VERSION ""

NS_ :

BS_:

BU_: PowertrainControlModule AtmosphericSensor SafetyRestraintSystem2 Aftertreatment_2_GasOutlet Aftertreatment_2_GasIntake DieselPartFilterControl Turbocharger SafetyRestraintSystem1 CabDisplay2 Aftertreatment_1_GasOutlet Aftertreatment_1_GasIntake OnBoardDataLogger OffBoardDiagnosticTool2 OffBoardDiagnosticTool1 FileServer ParkingBrakeController SeatController2 FanDriveController SteeringColumnUnit CommunicationUnitRadio CommunicationUnitSatellite CommunicationUnitCellular PropulsionBatteryCharger ChassisController2 ChassisController1 EngineValveControl AuxiliaryHeater2 AuxiliaryHeater1 ClutchUnit RampControl InformationSystem1 SuspensionSystemController2 OilSensor VehicleDynamicStability ExhaustEmissionController TransmissionDisplay2 TransmissionDisplay1 ClimateControl2 WaterPumpController RearAxleSteeringController LightingOperatorControl SeatController1 IgnitionController2 IgnitionController1 TirePressureController CabController2 CabController1 PneumaticSystemController SuspensionSystemController1 HydraulicPumpController EnduranceBrakingSystem RetarderExhaustEngine2 OnBoardDiagnosticUnit HeadwayController RetarderExhaustEngine1 CabDisplay1 ManagementComputer VirtualTerminal OffVehicleGateway PowerTakeOffFront HitchControl AuxiliaryValveControl BodyController TractorTrailerBridge1 StarterSystem ElectricalSystem VehicleSecurity VehicleNavigation AerodynamicControl ElectricalChargingSystem ClimateControl1 TripRecorder InstrumentCluster SuspensionDriveAxle2 SuspensionDriveAxle1 SuspensionSteerAxle SteeringController FuelSystem CruiseControl RetarderDriveline RetarderEngine BrakesDriveAxle2 BrakesDriveAxle1 BrakesSystemController BrakesSteerAxle AxleDrive2 AxleDrive1 AxleSteering PowerTakeOff ShiftConsoleSecondary ShiftConsolePrimary Transmission2 Transmission1 Engine2 Engine1

BO_ 2365403390 BJM4: 8 Vector__XXX
 SG_ Joystick4Button9PressedStatus : 62|2@1+ (1,0) [0|3] "" Vector__XXX
 SG_ Joystick4Button10PressedStatus : 60|2@1+ (1,0) [0|3] "" Vector__XXX
 SG_ Joystick4Button11PressedStatus : 58|2@1+ (1,0) [0|3] "" Vector__XXX
 SG_ Joystick4Button12PressedStatus : 56|2@1+ (1,0) [0|3] "" Vector__XXX
 SG_ Joystick4Button5PressedStatus : 54|2@1+ (1,0) [0|3] "" Vector__XXX
 SG_ Joystick4Button6PressedStatus : 52|2@1+ (1,0) [0|3] "" Vector__XXX
 SG_ Joystick4Button7PressedStatus : 50|2@1+ (1,0) [0|3] "" Vector__XXX
 SG_ Joystick4Button8PressedStatus : 48|2@1+ (1,0) [0|3] "" Vector__XXX
 SG_ Joystick4Button1PressedStatus : 46|2@1+ (1,0) [0|3] "" Vector__XXX
 SG_ Joystick4Button2PressedStatus : 44|2@1+ (1,0) [0|3] "" Vector__XXX
 SG_ Joystick4Button3PressedStatus : 42|2@1+ (1,0) [0|3] "" Vector__XXX
 SG_ Joystick4Button4PressedStatus : 40|2@1+ (1,0) [0|3] "" Vector__XXX
 SG_ Joystick4XAxisDetentPosStatus : 38|2@1+ (1,0) [0|3] "" Vector__XXX
 SG_ Joystick4YAxisDetentPosStatus : 36|2@1+ (1,0) [0|3] "" Vector__XXX
 SG_ Joystick4YAxisPos : 22|10@1+ (0.1,0) [0|102] "%" Vector__XXX
 SG_ Jystck4YAxsLvrFrwrdPstvPosStatus : 20|2@1+ (1,0) [0|3] "" Vector__XXX
 SG_ Jystck4YAxsLvrBckNgtivePosStatus : 18|2@1+ (1,0) [0|3] "" Vector__XXX
 SG_ Joystick4YAxisNeutralPosStatus : 16|2@1+ (1,0) [0|3] "" Vector__XXX
 SG_ Joystick4XAxisPos : 6|10@1+ (0.1,0) [0|102] "%" Vector__XXX
 SG_ Jystck4XAxsLvrRghtPstvePosStatus : 4|2@1+ (1,0) [0|3] "" Vector__XXX
 SG_ Jystck4XAxsLvrLftNgtivePosStatus : 2|2@1+ (1,0) [0|3] "" Vector__XXX
 SG_ Joystick4XAxisNeutralPosStatus : 0|2@1+ (1,0) [0|3] "" Vector__XXX

BO_ 2365400318 BJM10: 8 Vector__XXX
 SG_ Joystick10Button9PressedStatus : 62|2@1+ (1,0) [0|3] "" Vector__XXX
 SG_ Joystick10Button10PressedStatus : 60|2@1+ (1,0) [0|3] "" Vector__XXX
 SG_ Joystick10Button11PressedStatus : 58|2@1+ (1,0) [0|3] "" Vector__XXX
 SG_ Joystick10Button12PressedStatus : 56|2@1+ (1,0) [0|3] "" Vector__XXX
 SG_ Joystick10Button5PressedStatus : 54|2@1+ (1,0) [0|3] "" Vector__XXX
 SG_ Joystick10Button6PressedStatus : 52|2@1+ (1,0) [0|3] "" Vector__XXX
 SG_ Joystick10Button7PressedStatus : 50|2@1+ (1,0) [0|3] "" Vector__XXX
 SG_ Joystick10Button8PressedStatus : 48|2@1+ (1,0) [0|3] "" Vector__XXX
 SG_ Joystick10Button1PressedStatus : 46|2@1+ (1,0) [0|3] "" Vector__XXX
 SG_ Joystick10Button2PressedStatus : 44|2@1+ (1,0) [0|3] "" Vector__XXX
 SG_ Joystick10Button3PressedStatus : 42|2@1+ (1,0) [0|3] "" Vector__XXX
 SG_ Joystick10Button4PressedStatus : 40|2@1+ (1,0) [0|3] "" Vector__XXX
 SG_ Joystick10XAxisDetentPosStatus : 38|2@1+ (1,0) [0|3] "" Vector__XXX
 SG_ Joystick10YAxisDetentPosStatus : 36|2@1+ (1,0) [0|3] "" Vector__XXX
 SG_ Joystick10YAxisPos : 22|10@1+ (0.1,0) [0|102] "%" Vector__XXX
 SG_ Jystck10YAxsLvrFrwrdPstvPsStatus : 20|2@1+ (1,0) [0|3] "" Vector__XXX
 SG_ Jystck10YAxsLvrBckNgtvePosStatus : 18|2@1+ (1,0) [0|3] "" Vector__XXX
 SG_ Joystick10YAxisNeutralPosStatus : 16|2@1+ (1,0) [0|3] "" Vector__XXX
 SG_ Joystick10XAxisPos : 6|10@1+ (0.1,0) [0|102] "%" Vector__XXX
 SG_ Jystck10XAxsLvrRghtPstvPosStatus : 4|2@1+ (1,0) [0|3] "" Vector__XXX
 SG_ Jystck10XAxsLvrLftNgtvePosStatus : 2|2@1+ (1,0) [0|3] "" Vector__XXX
 SG_ Joystick10XAxisNeutralPosStatus : 0|2@1+ (1,0) [0|3] "" Vector__XXX

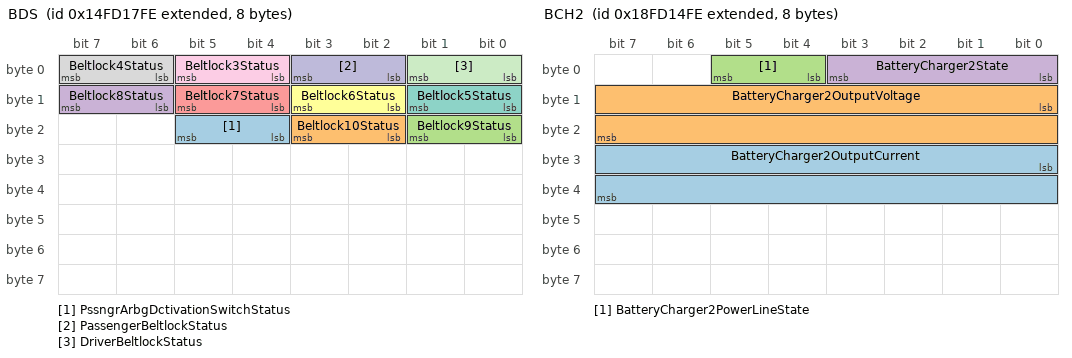
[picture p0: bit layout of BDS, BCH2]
BO_ 2499614718 BDS: 8 Vector__XXX
 SG_ PssngrArbgDctivationSwitchStatus : 20|2@1+ (1,0) [0|3] "" Vector__XXX
 SG_ Beltlock10Status : 18|2@1+ (1,0) [0|3] "" Vector__XXX
 SG_ Beltlock9Status : 16|2@1+ (1,0) [0|3] "" Vector__XXX
 SG_ Beltlock8Status : 14|2@1+ (1,0) [0|3] "" Vector__XXX
 SG_ Beltlock7Status : 12|2@1+ (1,0) [0|3] "" Vector__XXX
 SG_ Beltlock6Status : 10|2@1+ (1,0) [0|3] "" Vector__XXX
 SG_ Beltlock5Status : 8|2@1+ (1,0) [0|3] "" Vector__XXX
 SG_ Beltlock4Status : 6|2@1+ (1,0) [0|3] "" Vector__XXX
 SG_ Beltlock3Status : 4|2@1+ (1,0) [0|3] "" Vector__XXX
 SG_ PassengerBeltlockStatus : 2|2@1+ (1,0) [0|3] "" Vector__XXX
 SG_ DriverBeltlockStatus : 0|2@1+ (1,0) [0|3] "" Vector__XXX

BO_ 2566722814 BCH2: 8 Vector__XXX
 SG_ BatteryCharger2OutputCurrent : 24|16@1+ (0.05,-1600) [-1600|1612.75] "A" Vector__XXX
 SG_ BatteryCharger2OutputVoltage : 8|16@1+ (0.05,0) [0|3212.75] "V" Vector__XXX
 SG_ BatteryCharger2PowerLineState : 4|2@1+ (1,0) [0|3] "" Vector__XXX
 SG_ BatteryCharger2State : 0|4@1+ (1,0) [0|15] "" Vector__XXX

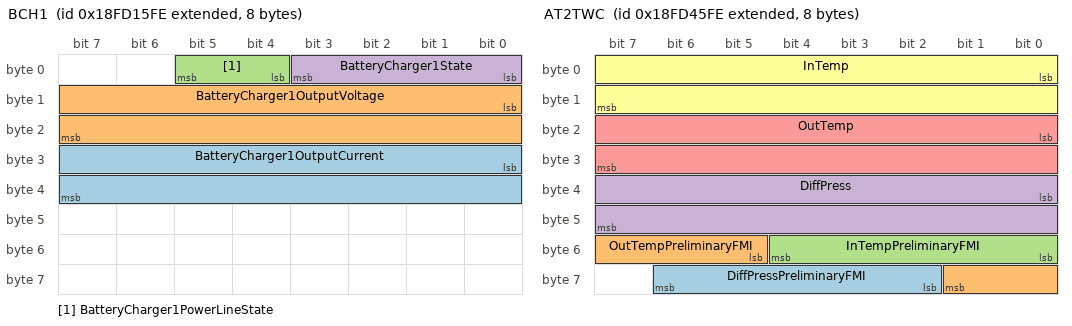
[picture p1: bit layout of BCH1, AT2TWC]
BO_ 2566723070 BCH1: 8 Vector__XXX
 SG_ BatteryCharger1OutputCurrent : 24|16@1+ (0.05,-1600) [-1600|1612.75] "A" Vector__XXX
 SG_ BatteryCharger1OutputVoltage : 8|16@1+ (0.05,0) [0|3212.75] "V" Vector__XXX
 SG_ BatteryCharger1PowerLineState : 4|2@1+ (1,0) [0|3] "" Vector__XXX
 SG_ BatteryCharger1State : 0|4@1+ (1,0) [0|15] "" Vector__XXX

BO_ 2566725118 ATDT2: 8 Vector__XXX
 SG_ TwoTWCDiffTemp : 16|16@1+ (0.03125,-273) [-273|1734.96875] "°C" Vector__XXX
 SG_ OneTWCDiffTemp : 0|16@1+ (0.03125,-273) [-273|1734.96875] "°C" Vector__XXX

BO_ 2566725374 ATDT1: 8 Vector__XXX
 SG_ TwoGOCDiffTemp : 16|16@1+ (0.03125,-273) [-273|1734.96875] "°C" Vector__XXX
 SG_ OneGOCDiffTemp : 0|16@1+ (0.03125,-273) [-273|1734.96875] "°C" Vector__XXX

BO_ 2566712830 AT2WUDOC: 8 Vector__XXX
 SG_ OutTemp : 16|16@1+ (0.03125,-273) [-273|1734.96875] "°C" Vector__XXX
 SG_ InTemp : 0|16@1+ (0.03125,-273) [-273|1734.96875] "°C" Vector__XXX

BO_ 2566735358 AT2TWC: 8 Vector__XXX
 SG_ DiffPressPreliminaryFMI : 58|5@1+ (1,0) [0|31] "" Vector__XXX
 SG_ OutTempPreliminaryFMI : 53|5@1+ (1,0) [0|31] "" Vector__XXX
 SG_ InTempPreliminaryFMI : 48|5@1+ (1,0) [0|31] "" Vector__XXX
 SG_ DiffPress : 32|16@1+ (0.1,0) [0|6425.5] "kPa" Vector__XXX
 SG_ OutTemp : 16|16@1+ (0.03125,-273) [-273|1734.96875] "°C" Vector__XXX
 SG_ InTemp : 0|16@1+ (0.03125,-273) [-273|1734.96875] "°C" Vector__XXX

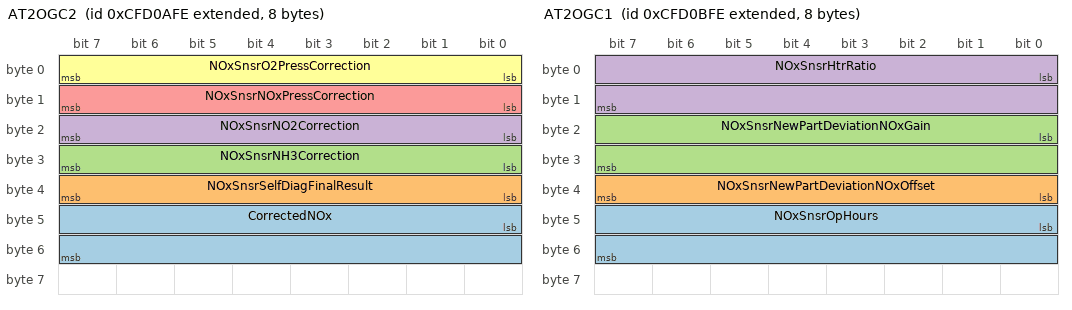
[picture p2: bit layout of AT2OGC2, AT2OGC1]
BO_ 2365393662 AT2OGC2: 8 Vector__XXX
 SG_ CorrectedNOx : 40|16@1+ (0.05,-200) [-200|3012.75] "ppm" Vector__XXX
 SG_ NOxSnsrSelfDiagFinalResult : 32|8@1+ (1,0) [0|250] "" Vector__XXX
 SG_ NOxSnsrNH3Correction : 24|8@1+ (0.5,0) [0|125] "%" Vector__XXX
 SG_ NOxSnsrNO2Correction : 16|8@1+ (0.5,0) [0|125] "%" Vector__XXX
 SG_ NOxSnsrNOxPressCorrection : 8|8@1+ (0.5,0) [0|125] "%/bar" Vector__XXX
 SG_ NOxSnsrO2PressCorrection : 0|8@1+ (0.5,0) [0|125] "%/bar" Vector__XXX

BO_ 2365393918 AT2OGC1: 8 Vector__XXX
 SG_ NOxSnsrOpHours : 40|16@1+ (1,0) [0|64255] "h" Vector__XXX
 SG_ NOxSnsrNewPartDeviationNOxOffset : 32|8@1+ (1,-125) [-125|125] "ppm" Vector__XXX
 SG_ NOxSnsrNewPartDeviationNOxGain : 16|16@1+ (0.1,-100) [-100|100] "%" Vector__XXX
 SG_ NOxSnsrHtrRatio : 0|16@1+ (0.001,0) [0|64.255] "" Vector__XXX

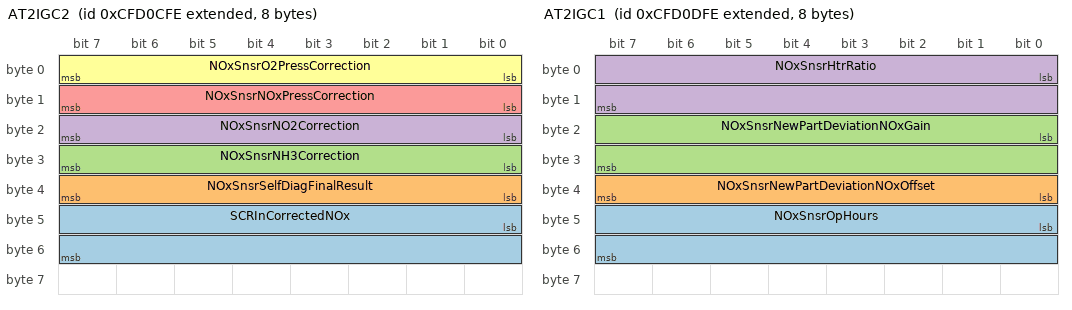
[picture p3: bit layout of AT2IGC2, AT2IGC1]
BO_ 2365394174 AT2IGC2: 8 Vector__XXX
 SG_ SCRInCorrectedNOx : 40|16@1+ (0.05,-200) [-200|3012.75] "ppm" Vector__XXX
 SG_ NOxSnsrSelfDiagFinalResult : 32|8@1+ (1,0) [0|250] "" Vector__XXX
 SG_ NOxSnsrNH3Correction : 24|8@1+ (0.5,0) [0|125] "%" Vector__XXX
 SG_ NOxSnsrNO2Correction : 16|8@1+ (0.5,0) [0|125] "%" Vector__XXX
 SG_ NOxSnsrNOxPressCorrection : 8|8@1+ (0.5,0) [0|125] "%/bar" Vector__XXX
 SG_ NOxSnsrO2PressCorrection : 0|8@1+ (0.5,0) [0|125] "%/bar" Vector__XXX

BO_ 2365394430 AT2IGC1: 8 Vector__XXX
 SG_ NOxSnsrOpHours : 40|16@1+ (1,0) [0|64255] "h" Vector__XXX
 SG_ NOxSnsrNewPartDeviationNOxOffset : 32|8@1+ (1,-125) [-125|125] "ppm" Vector__XXX
 SG_ NOxSnsrNewPartDeviationNOxGain : 16|16@1+ (0.1,-100) [-100|100] "%" Vector__XXX
 SG_ NOxSnsrHtrRatio : 0|16@1+ (0.001,0) [0|64.255] "" Vector__XXX

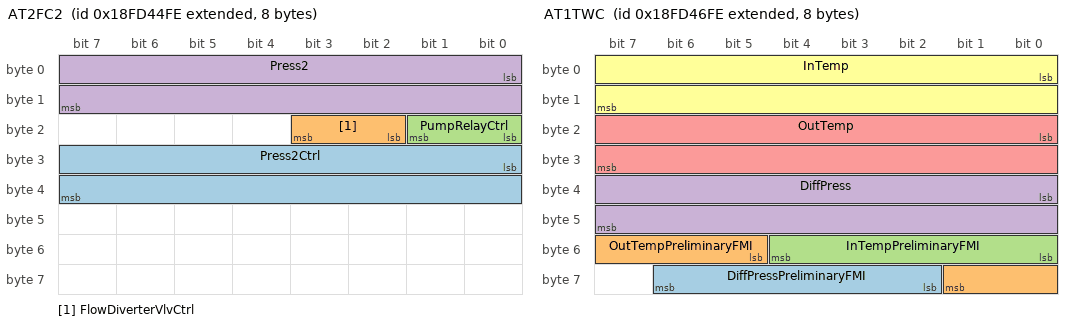
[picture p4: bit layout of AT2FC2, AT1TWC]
BO_ 2566735102 AT2FC2: 8 Vector__XXX
 SG_ Press2Ctrl : 24|16@1+ (0.0025,0) [0|160.6375] "%" Vector__XXX
 SG_ FlowDiverterVlvCtrl : 18|2@1+ (1,0) [0|3] "" Vector__XXX
 SG_ PumpRelayCtrl : 16|2@1+ (1,0) [0|3] "" Vector__XXX
 SG_ Press2 : 0|16@1+ (0.1,0) [0|6425.5] "kPa" Vector__XXX

BO_ 2157313790 AT2DPFSSC: 8 Vector__XXX
 SG_ StdDeviationCalOffset : 16|16@1+ (0.0025,0) [0|160.6375] "%" Vector__XXX
 SG_ MeanCalOffset : 0|16@1+ (0.0025,0) [0|160.6375] "%" Vector__XXX

BO_ 2566724350 AT1WUDOC: 8 Vector__XXX
 SG_ OutTemp : 16|16@1+ (0.03125,-273) [-273|1734.96875] "°C" Vector__XXX
 SG_ InTemp : 0|16@1+ (0.03125,-273) [-273|1734.96875] "°C" Vector__XXX

BO_ 2566735614 AT1TWC: 8 Vector__XXX
 SG_ DiffPressPreliminaryFMI : 58|5@1+ (1,0) [0|31] "" Vector__XXX
 SG_ OutTempPreliminaryFMI : 53|5@1+ (1,0) [0|31] "" Vector__XXX
 SG_ InTempPreliminaryFMI : 48|5@1+ (1,0) [0|31] "" Vector__XXX
 SG_ DiffPress : 32|16@1+ (0.1,0) [0|6425.5] "kPa" Vector__XXX
 SG_ OutTemp : 16|16@1+ (0.03125,-273) [-273|1734.96875] "°C" Vector__XXX
 SG_ InTemp : 0|16@1+ (0.03125,-273) [-273|1734.96875] "°C" Vector__XXX

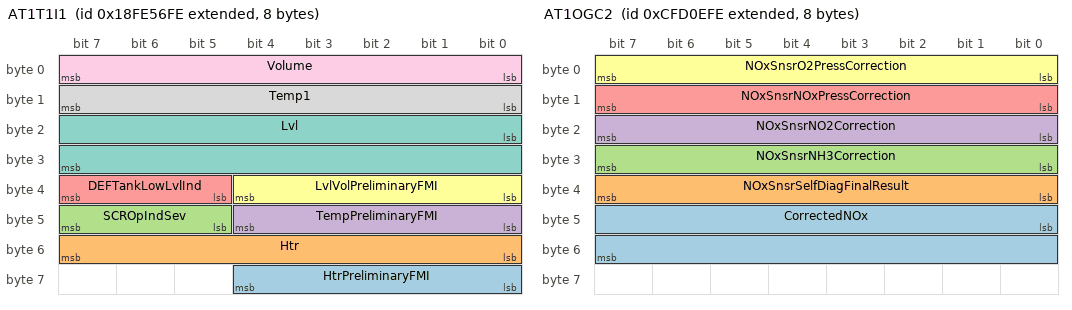
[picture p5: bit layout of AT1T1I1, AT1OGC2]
BO_ 2566805246 AT1T1I1: 8 Vector__XXX
 SG_ HtrPreliminaryFMI : 56|5@1+ (1,0) [0|31] "" Vector__XXX
 SG_ Htr : 48|8@1+ (0.4,0) [0|100] "%" Vector__XXX
 SG_ SCROpIndSev : 45|3@1+ (1,0) [0|7] "" Vector__XXX
 SG_ TempPreliminaryFMI : 40|5@1+ (1,0) [0|31] "" Vector__XXX
 SG_ DEFTankLowLvlInd : 37|3@1+ (1,0) [0|7] "" Vector__XXX
 SG_ LvlVolPreliminaryFMI : 32|5@1+ (1,0) [0|31] "" Vector__XXX
 SG_ Lvl : 16|16@1+ (0.1,0) [0|6425.5] "mm" Vector__XXX
 SG_ Temp1 : 8|8@1+ (1,-40) [-40|210] "°C" Vector__XXX
 SG_ Volume : 0|8@1+ (0.4,0) [0|100] "%" Vector__XXX

BO_ 2365394686 AT1OGC2: 8 Vector__XXX
 SG_ CorrectedNOx : 40|16@1+ (0.05,-200) [-200|3012.75] "ppm" Vector__XXX
 SG_ NOxSnsrSelfDiagFinalResult : 32|8@1+ (1,0) [0|250] "" Vector__XXX
 SG_ NOxSnsrNH3Correction : 24|8@1+ (0.5,0) [0|125] "%" Vector__XXX
 SG_ NOxSnsrNO2Correction : 16|8@1+ (0.5,0) [0|125] "%" Vector__XXX
 SG_ NOxSnsrNOxPressCorrection : 8|8@1+ (0.5,0) [0|125] "%/bar" Vector__XXX
 SG_ NOxSnsrO2PressCorrection : 0|8@1+ (0.5,0) [0|125] "%/bar" Vector__XXX

BO_ 2365394942 AT1OGC1: 8 Vector__XXX
 SG_ NOxSnsrOpHours : 40|16@1+ (1,0) [0|64255] "h" Vector__XXX
 SG_ NOxSnsrNewPartDeviationNOxOffset : 32|8@1+ (1,-125) [-125|125] "ppm" Vector__XXX
 SG_ NOxSnsrNewPartDeviationNOxGain : 16|16@1+ (0.1,-100) [-100|100] "%" Vector__XXX
 SG_ NOxSnsrHtrRatio : 0|16@1+ (0.001,0) [0|64.255] "" Vector__XXX

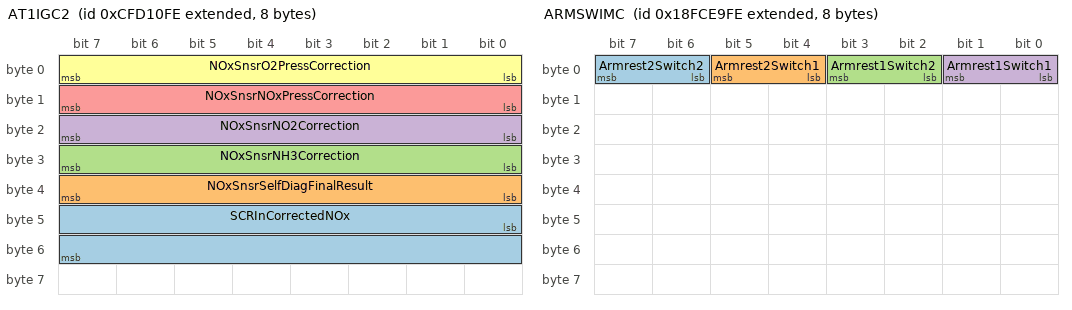
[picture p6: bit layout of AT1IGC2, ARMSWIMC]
BO_ 2365395198 AT1IGC2: 8 Vector__XXX
 SG_ SCRInCorrectedNOx : 40|16@1+ (0.05,-200) [-200|3012.75] "ppm" Vector__XXX
 SG_ NOxSnsrSelfDiagFinalResult : 32|8@1+ (1,0) [0|250] "" Vector__XXX
 SG_ NOxSnsrNH3Correction : 24|8@1+ (0.5,0) [0|125] "%" Vector__XXX
 SG_ NOxSnsrNO2Correction : 16|8@1+ (0.5,0) [0|125] "%" Vector__XXX
 SG_ NOxSnsrNOxPressCorrection : 8|8@1+ (0.5,0) [0|125] "%/bar" Vector__XXX
 SG_ NOxSnsrO2PressCorrection : 0|8@1+ (0.5,0) [0|125] "%/bar" Vector__XXX

BO_ 2365395454 AT1IGC1: 8 Vector__XXX
 SG_ NOxSnsrOpHours : 40|16@1+ (1,0) [0|64255] "h" Vector__XXX
 SG_ NOxSnsrNewPartDeviationNOxOffset : 32|8@1+ (1,-125) [-125|125] "ppm" Vector__XXX
 SG_ NOxSnsrNewPartDeviationNOxGain : 16|16@1+ (0.1,-100) [-100|100] "%" Vector__XXX
 SG_ NOxSnsrHtrRatio : 0|16@1+ (0.001,0) [0|64.255] "" Vector__XXX

BO_ 2157248254 AT1DPFSSC: 8 Vector__XXX
 SG_ StdDeviationCalOffset : 16|16@1+ (0.0025,0) [0|160.6375] "%" Vector__XXX
 SG_ MeanCalOffset : 0|16@1+ (0.0025,0) [0|160.6375] "%" Vector__XXX

BO_ 2566711806 ARMSWIMC: 8 Vector__XXX
 SG_ Armrest2Switch2 : 6|2@1+ (1,0) [0|3] "" Vector__XXX
 SG_ Armrest2Switch1 : 4|2@1+ (1,0) [0|3] "" Vector__XXX
 SG_ Armrest1Switch2 : 2|2@1+ (1,0) [0|3] "" Vector__XXX
 SG_ Armrest1Switch1 : 0|2@1+ (1,0) [0|3] "" Vector__XXX

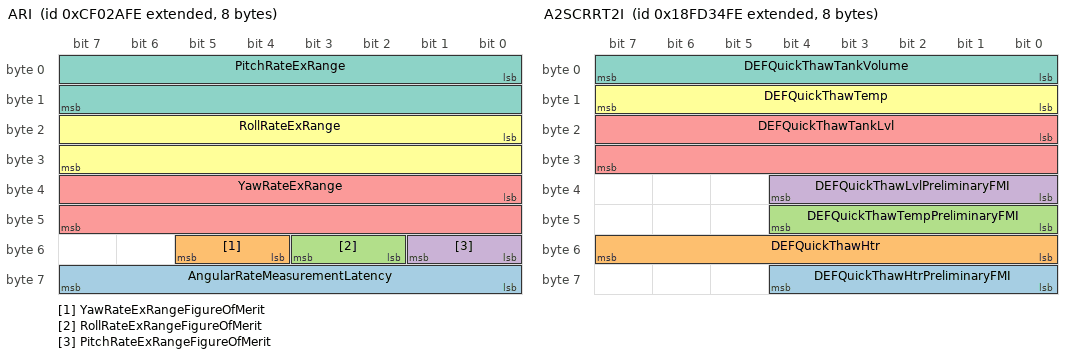
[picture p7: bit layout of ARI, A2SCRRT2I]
BO_ 2364549886 ARI: 8 Vector__XXX
 SG_ AngularRateMeasurementLatency : 56|8@1+ (0.5,0) [0|125] "ms" Vector__XXX
 SG_ YawRateExRangeFigureOfMerit : 52|2@1+ (1,0) [0|3] "" Vector__XXX
 SG_ RollRateExRangeFigureOfMerit : 50|2@1+ (1,0) [0|3] "" Vector__XXX
 SG_ PitchRateExRangeFigureOfMerit : 48|2@1+ (1,0) [0|3] "" Vector__XXX
 SG_ YawRateExRange : 32|16@1+ (0.0078125,-250) [-250|250.992] "deg/s" Vector__XXX
 SG_ RollRateExRange : 16|16@1+ (0.0078125,-250) [-250|250.992] "deg/s" Vector__XXX
 SG_ PitchRateExRange : 0|16@1+ (0.0078125,-250) [-250|250.992] "deg/s" Vector__XXX

BO_ 2566712318 AFT2NAI: 8 Vector__XXX
 SG_ DesulfationStatus : 2|2@1+ (1,0) [0|3] "" Vector__XXX
 SG_ RegenStatus : 0|2@1+ (1,0) [0|3] "" Vector__XXX

BO_ 2566712574 AFT1NAI: 8 Vector__XXX
 SG_ DesulfationStatus : 2|2@1+ (1,0) [0|3] "" Vector__XXX
 SG_ RegenStatus : 0|2@1+ (1,0) [0|3] "" Vector__XXX

BO_ 2164078590 A2SCRSI1: 8 Vector__XXX
 SG_ ConversionEfficiency : 32|8@1+ (0.4,0) [0|100] "%" Vector__XXX
 SG_ CommandedDEFConsumption : 16|16@1+ (0.05,0) [0|3212.75] "L/h" Vector__XXX
 SG_ DEFAvgConsumption : 0|16@1+ (0.05,0) [0|3212.75] "L/h" Vector__XXX

BO_ 2566731006 A2SCRRT2I: 8 Vector__XXX
 SG_ DEFQuickThawHtrPreliminaryFMI : 56|5@1+ (1,0) [0|31] "" Vector__XXX
 SG_ DEFQuickThawHtr : 48|8@1+ (0.4,0) [0|100] "%" Vector__XXX
 SG_ DEFQuickThawTempPreliminaryFMI : 40|5@1+ (1,0) [0|31] "" Vector__XXX
 SG_ DEFQuickThawLvlPreliminaryFMI : 32|5@1+ (1,0) [0|31] "" Vector__XXX
 SG_ DEFQuickThawTankLvl : 16|16@1+ (0.1,0) [0|6425.5] "mm" Vector__XXX
 SG_ DEFQuickThawTemp : 8|8@1+ (1,-40) [-40|210] "°C" Vector__XXX
 SG_ DEFQuickThawTankVolume : 0|8@1+ (0.4,0) [0|100] "%" Vector__XXX

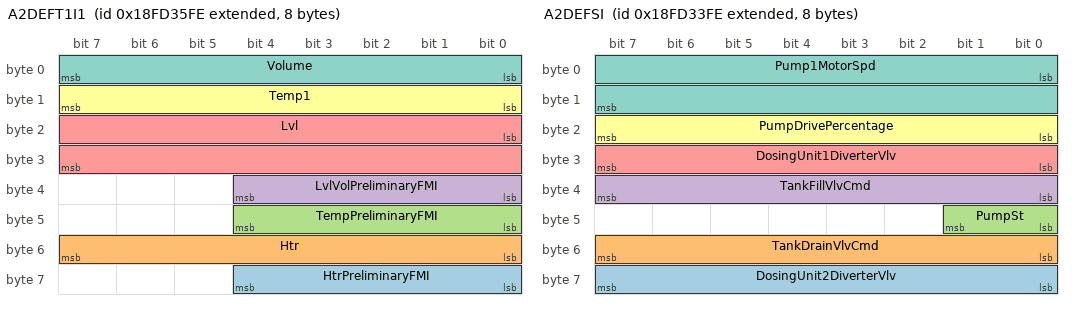
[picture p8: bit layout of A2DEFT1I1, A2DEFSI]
BO_ 2566731262 A2DEFT1I1: 8 Vector__XXX
 SG_ HtrPreliminaryFMI : 56|5@1+ (1,0) [0|31] "" Vector__XXX
 SG_ Htr : 48|8@1+ (0.4,0) [0|100] "%" Vector__XXX
 SG_ TempPreliminaryFMI : 40|5@1+ (1,0) [0|31] "" Vector__XXX
 SG_ LvlVolPreliminaryFMI : 32|5@1+ (1,0) [0|31] "" Vector__XXX
 SG_ Lvl : 16|16@1+ (0.1,0) [0|6425.5] "mm" Vector__XXX
 SG_ Temp1 : 8|8@1+ (1,-40) [-40|210] "°C" Vector__XXX
 SG_ Volume : 0|8@1+ (0.4,0) [0|100] "%" Vector__XXX

BO_ 2566730750 A2DEFSI: 8 Vector__XXX
 SG_ DosingUnit2DiverterVlv : 56|8@1+ (0.4,0) [0|100] "%" Vector__XXX
 SG_ TankDrainVlvCmd : 48|8@1+ (0.4,0) [0|100] "%" Vector__XXX
 SG_ PumpSt : 40|2@1+ (1,0) [0|3] "" Vector__XXX
 SG_ TankFillVlvCmd : 32|8@1+ (0.4,0) [0|100] "%" Vector__XXX
 SG_ DosingUnit1DiverterVlv : 24|8@1+ (0.4,0) [0|100] "%" Vector__XXX
 SG_ PumpDrivePercentage : 16|8@1+ (0.4,0) [0|100] "%" Vector__XXX
 SG_ Pump1MotorSpd : 0|16@1+ (0.5,0) [0|32127.5] "rpm" Vector__XXX

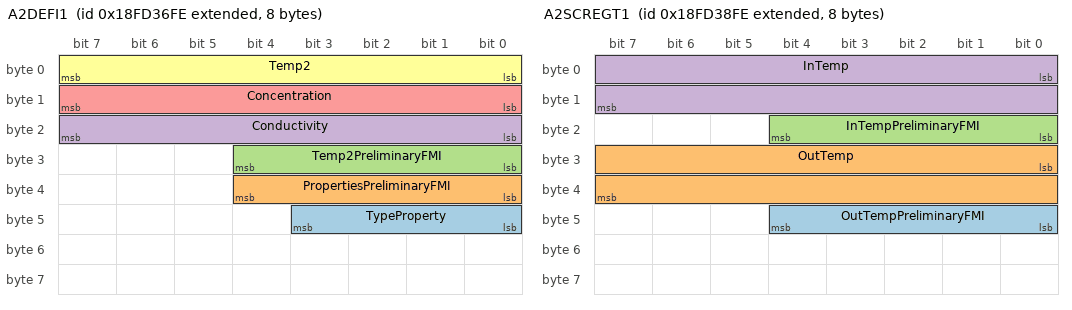
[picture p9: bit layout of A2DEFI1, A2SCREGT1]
BO_ 2566731518 A2DEFI1: 8 Vector__XXX
 SG_ TypeProperty : 40|4@1+ (1,0) [0|15] "" Vector__XXX
 SG_ PropertiesPreliminaryFMI : 32|5@1+ (1,0) [0|31] "" Vector__XXX
 SG_ Temp2PreliminaryFMI : 24|5@1+ (1,0) [0|31] "" Vector__XXX
 SG_ Conductivity : 16|8@1+ (5,0) [0|1250] "µSiemens/mm" Vector__XXX
 SG_ Concentration : 8|8@1+ (0.25,0) [0|62.5] "%" Vector__XXX
 SG_ Temp2 : 0|8@1+ (1,-40) [-40|210] "°C" Vector__XXX

BO_ 2566732030 A2SCREGT1: 8 Vector__XXX
 SG_ OutTempPreliminaryFMI : 40|5@1+ (1,0) [0|31] "" Vector__XXX
 SG_ OutTemp : 24|16@1+ (0.03125,-273) [-273|1734.96875] "°C" Vector__XXX
 SG_ InTempPreliminaryFMI : 16|5@1+ (1,0) [0|31] "" Vector__XXX
 SG_ InTemp : 0|16@1+ (0.03125,-273) [-273|1734.96875] "°C" Vector__XXX

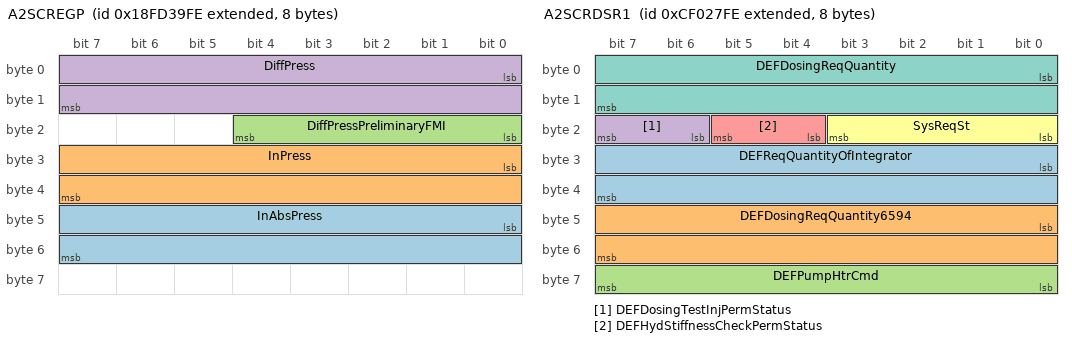
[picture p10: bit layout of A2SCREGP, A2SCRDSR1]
BO_ 2566732286 A2SCREGP: 8 Vector__XXX
 SG_ InAbsPress : 40|16@1+ (0.1,0) [0|6425.5] "kPa" Vector__XXX
 SG_ InPress : 24|16@1+ (0.1,-3212.7) [-3212.7|3212.8] "kPa" Vector__XXX
 SG_ DiffPressPreliminaryFMI : 16|5@1+ (1,0) [0|31] "" Vector__XXX
 SG_ DiffPress : 0|16@1+ (0.1,0) [0|6425.5] "kPa" Vector__XXX

BO_ 2164079358 A2SCRDSR2: 8 Vector__XXX
 SG_ DEFLineHtr10 : 48|2@1+ (1,0) [0|3] "" Vector__XXX
 SG_ DEFLineHtr9 : 46|2@1+ (1,0) [0|3] "" Vector__XXX
 SG_ DEFLineHtr8 : 44|2@1+ (1,0) [0|3] "" Vector__XXX
 SG_ DEFLineHtr7 : 42|2@1+ (1,0) [0|3] "" Vector__XXX
 SG_ DEFLineHtr6 : 40|2@1+ (1,0) [0|3] "" Vector__XXX
 SG_ DEFLineHtr5 : 38|2@1+ (1,0) [0|3] "" Vector__XXX
 SG_ DEFLineHtrRelay3 : 36|2@1+ (1,0) [0|3] "" Vector__XXX
 SG_ DEFLineHtrRelay2 : 34|2@1+ (1,0) [0|3] "" Vector__XXX
 SG_ DEFLineHtrRelay1 : 32|2@1+ (1,0) [0|3] "" Vector__XXX
 SG_ DEFQuickThawHtrCmd : 24|8@1+ (0.4,0) [0|100] "%" Vector__XXX
 SG_ DEFTankHtrCmd : 16|8@1+ (0.4,0) [0|100] "%" Vector__XXX
 SG_ DEFLineHtr4 : 14|2@1+ (1,0) [0|3] "" Vector__XXX
 SG_ DEFLineHtr3 : 12|2@1+ (1,0) [0|3] "" Vector__XXX
 SG_ DEFLineHtr2 : 10|2@1+ (1,0) [0|3] "" Vector__XXX
 SG_ DEFLineHtr1 : 8|2@1+ (1,0) [0|3] "" Vector__XXX
 SG_ DEFDoserHeatingModeReq : 4|3@1+ (1,0) [0|7] "" Vector__XXX
 SG_ DEFDoserFaultSuppressionReq : 2|2@1+ (1,0) [0|3] "" Vector__XXX

BO_ 2364549118 A2SCRDSR1: 8 Vector__XXX
 SG_ DEFReqQuantityOfIntegrator : 24|16@1+ (0.1,0) [0|6425.5] "g" Vector__XXX
 SG_ DEFDosingReqQuantity6594 : 40|16@1+ (0.05,0) [0|3212.75] "g/min" Vector__XXX
 SG_ DEFPumpHtrCmd : 56|8@1+ (0.4,0) [0|100] "%" Vector__XXX
 SG_ DEFDosingTestInjPermStatus : 22|2@1+ (1,0) [0|3] "" Vector__XXX
 SG_ DEFHydStiffnessCheckPermStatus : 20|2@1+ (1,0) [0|3] "" Vector__XXX
 SG_ SysReqSt : 16|4@1+ (1,0) [0|15] "" Vector__XXX
 SG_ DEFDosingReqQuantity : 0|16@1+ (0.3,0) [0|19276.5] "g/h" Vector__XXX

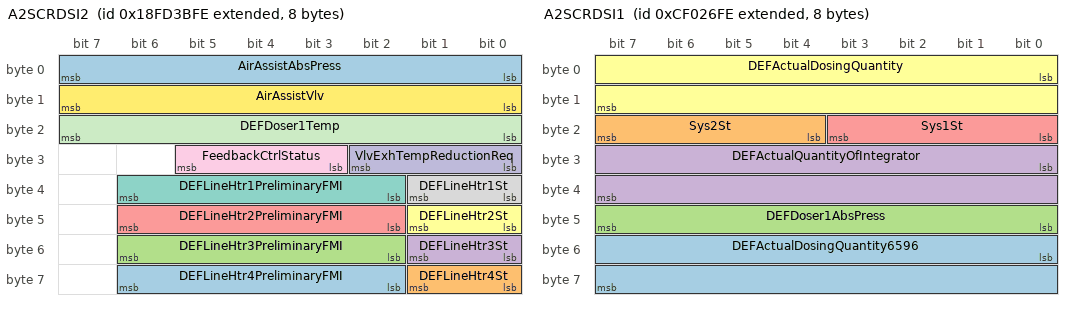
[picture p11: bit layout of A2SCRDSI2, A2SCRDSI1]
BO_ 2566732798 A2SCRDSI2: 8 Vector__XXX
 SG_ DEFLineHtr4PreliminaryFMI : 58|5@1+ (1,0) [0|31] "" Vector__XXX
 SG_ DEFLineHtr4St : 56|2@1+ (1,0) [0|3] "" Vector__XXX
 SG_ DEFLineHtr3PreliminaryFMI : 50|5@1+ (1,0) [0|31] "" Vector__XXX
 SG_ DEFLineHtr3St : 48|2@1+ (1,0) [0|3] "" Vector__XXX
 SG_ DEFLineHtr2PreliminaryFMI : 42|5@1+ (1,0) [0|31] "" Vector__XXX
 SG_ DEFLineHtr2St : 40|2@1+ (1,0) [0|3] "" Vector__XXX
 SG_ DEFLineHtr1PreliminaryFMI : 34|5@1+ (1,0) [0|31] "" Vector__XXX
 SG_ DEFLineHtr1St : 32|2@1+ (1,0) [0|3] "" Vector__XXX
 SG_ FeedbackCtrlStatus : 27|3@1+ (1,0) [0|7] "" Vector__XXX
 SG_ VlvExhTempReductionReq : 24|3@1+ (1,0) [0|7] "" Vector__XXX
 SG_ DEFDoser1Temp : 16|8@1+ (1,-40) [-40|210] "°C" Vector__XXX
 SG_ AirAssistVlv : 8|8@1+ (0.4,0) [0|100] "%" Vector__XXX
 SG_ AirAssistAbsPress : 0|8@1+ (8,0) [0|2000] "kPa" Vector__XXX

BO_ 2364548862 A2SCRDSI1: 8 Vector__XXX
 SG_ DEFActualDosingQuantity6596 : 48|16@1+ (0.05,0) [0|3212.75] "g/min" Vector__XXX
 SG_ Sys2St : 20|4@1+ (1,0) [0|15] "" Vector__XXX
 SG_ DEFDoser1AbsPress : 40|8@1+ (8,0) [0|2000] "kPa" Vector__XXX
 SG_ DEFActualQuantityOfIntegrator : 24|16@1+ (0.1,0) [0|6425.5] "g" Vector__XXX
 SG_ Sys1St : 16|4@1+ (1,0) [0|15] "" Vector__XXX
 SG_ DEFActualDosingQuantity : 0|16@1+ (0.3,0) [0|19276.5] "g/h" Vector__XXX

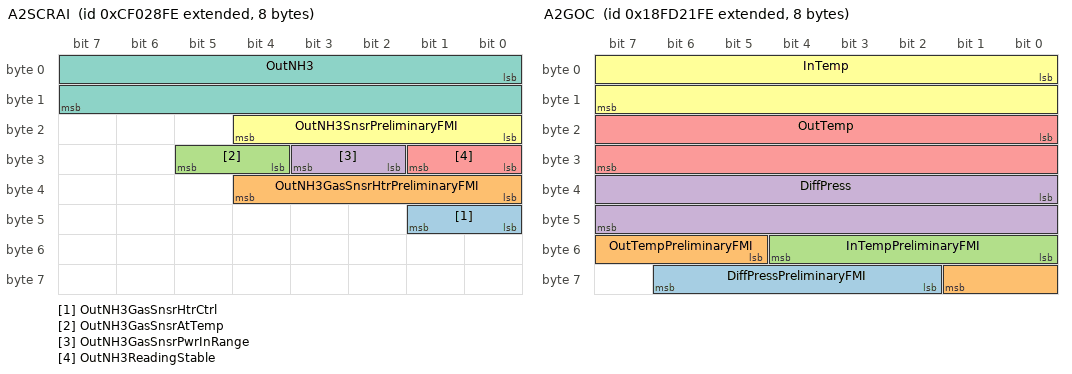
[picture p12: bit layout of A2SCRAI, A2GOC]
BO_ 2364549374 A2SCRAI: 8 Vector__XXX
 SG_ OutNH3GasSnsrHtrCtrl : 40|2@1+ (1,0) [0|3] "" Vector__XXX
 SG_ OutNH3GasSnsrHtrPreliminaryFMI : 32|5@1+ (1,0) [0|31] "" Vector__XXX
 SG_ OutNH3GasSnsrAtTemp : 28|2@1+ (1,0) [0|3] "" Vector__XXX
 SG_ OutNH3GasSnsrPwrInRange : 26|2@1+ (1,0) [0|3] "" Vector__XXX
 SG_ OutNH3ReadingStable : 24|2@1+ (1,0) [0|3] "" Vector__XXX
 SG_ OutNH3SnsrPreliminaryFMI : 16|5@1+ (1,0) [0|31] "" Vector__XXX
 SG_ OutNH3 : 0|16@1+ (0.05,-200) [-200|3012.75] "ppm" Vector__XXX

BO_ 2566726142 A2GOC: 8 Vector__XXX
 SG_ DiffPressPreliminaryFMI : 58|5@1+ (1,0) [0|31] "" Vector__XXX
 SG_ OutTempPreliminaryFMI : 53|5@1+ (1,0) [0|31] "" Vector__XXX
 SG_ InTempPreliminaryFMI : 48|5@1+ (1,0) [0|31] "" Vector__XXX
 SG_ DiffPress : 32|16@1+ (0.1,0) [0|6425.5] "kPa" Vector__XXX
 SG_ OutTemp : 16|16@1+ (0.03125,-273) [-273|1734.96875] "°C" Vector__XXX
 SG_ InTemp : 0|16@1+ (0.03125,-273) [-273|1734.96875] "°C" Vector__XXX

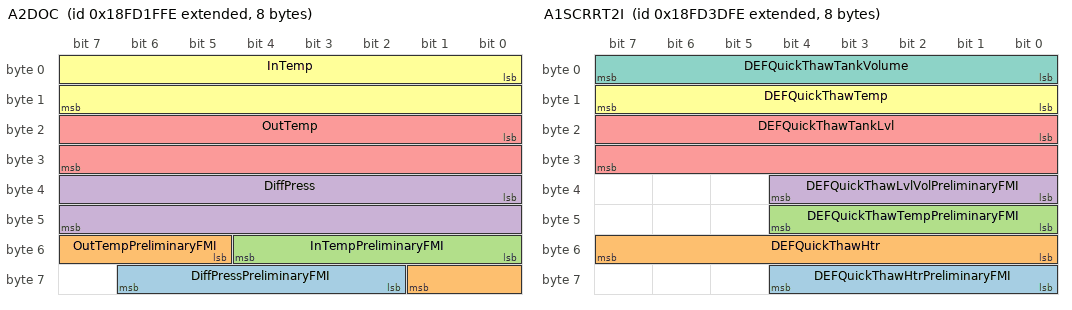
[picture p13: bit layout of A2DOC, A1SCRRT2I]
BO_ 2566725630 A2DOC: 8 Vector__XXX
 SG_ DiffPressPreliminaryFMI : 58|5@1+ (1,0) [0|31] "" Vector__XXX
 SG_ OutTempPreliminaryFMI : 53|5@1+ (1,0) [0|31] "" Vector__XXX
 SG_ InTempPreliminaryFMI : 48|5@1+ (1,0) [0|31] "" Vector__XXX
 SG_ DiffPress : 32|16@1+ (0.5,0) [0|32127.5] "kPa" Vector__XXX
 SG_ OutTemp : 16|16@1+ (0.03125,-273) [-273|1734.96875] "°C" Vector__XXX
 SG_ InTemp : 0|16@1+ (0.03125,-273) [-273|1734.96875] "°C" Vector__XXX

BO_ 2566733310 A1SCRRT2I: 8 Vector__XXX
 SG_ DEFQuickThawHtrPreliminaryFMI : 56|5@1+ (1,0) [0|31] "" Vector__XXX
 SG_ DEFQuickThawHtr : 48|8@1+ (0.4,0) [0|100] "%" Vector__XXX
 SG_ DEFQuickThawTempPreliminaryFMI : 40|5@1+ (1,0) [0|31] "" Vector__XXX
 SG_ DEFQuickThawLvlVolPreliminaryFMI : 32|5@1+ (1,0) [0|31] "" Vector__XXX
 SG_ DEFQuickThawTankLvl : 16|16@1+ (0.1,0) [0|6425.5] "mm" Vector__XXX
 SG_ DEFQuickThawTemp : 8|8@1+ (1,-40) [-40|210] "°C" Vector__XXX
 SG_ DEFQuickThawTankVolume : 0|8@1+ (0.4,0) [0|100] "%" Vector__XXX

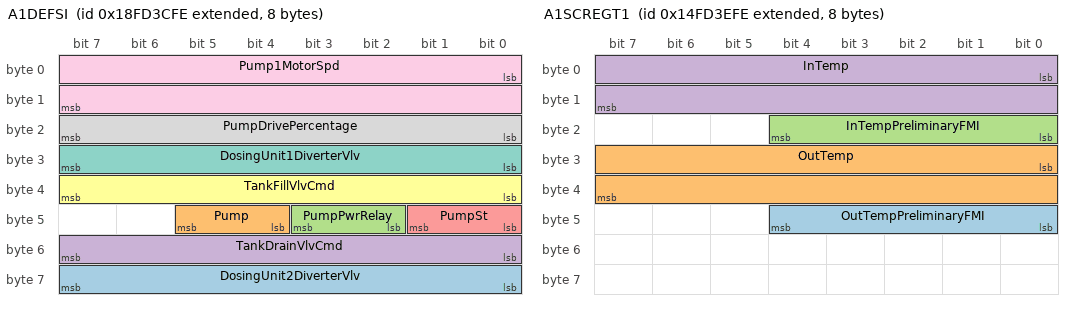
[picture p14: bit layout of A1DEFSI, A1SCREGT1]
BO_ 2566733054 A1DEFSI: 8 Vector__XXX
 SG_ DosingUnit2DiverterVlv : 56|8@1+ (0.4,0) [0|100] "%" Vector__XXX
 SG_ Pump : 44|2@1+ (1,0) [0|3] "" Vector__XXX
 SG_ PumpPwrRelay : 42|2@1+ (1,0) [0|3] "" Vector__XXX
 SG_ TankDrainVlvCmd : 48|8@1+ (0.4,0) [0|100] "%" Vector__XXX
 SG_ PumpSt : 40|2@1+ (1,0) [0|3] "" Vector__XXX
 SG_ TankFillVlvCmd : 32|8@1+ (0.4,0) [0|100] "%" Vector__XXX
 SG_ DosingUnit1DiverterVlv : 24|8@1+ (0.4,0) [0|100] "%" Vector__XXX
 SG_ PumpDrivePercentage : 16|8@1+ (0.4,0) [0|100] "%" Vector__XXX
 SG_ Pump1MotorSpd : 0|16@1+ (0.5,0) [0|32127.5] "rpm" Vector__XXX

BO_ 2499624702 A1SCREGT1: 8 Vector__XXX
 SG_ OutTempPreliminaryFMI : 40|5@1+ (1,0) [0|31] "" Vector__XXX
 SG_ OutTemp : 24|16@1+ (0.03125,-273) [-273|1734.96875] "°C" Vector__XXX
 SG_ InTempPreliminaryFMI : 16|5@1+ (1,0) [0|31] "" Vector__XXX
 SG_ InTemp : 0|16@1+ (0.03125,-273) [-273|1734.96875] "°C" Vector__XXX

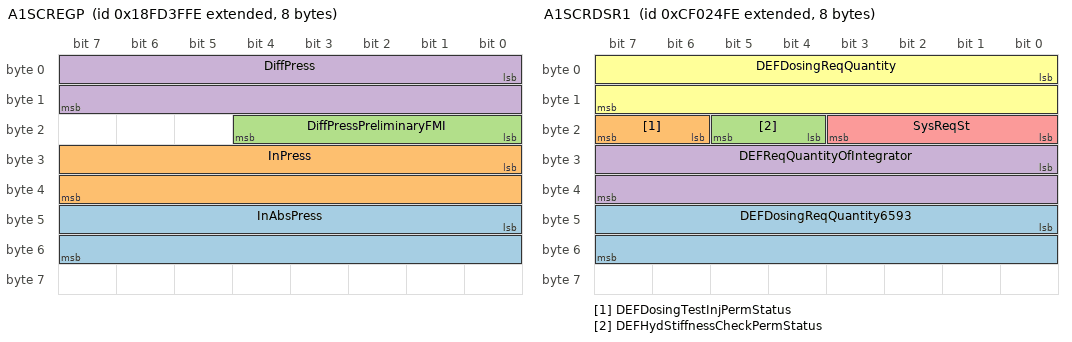
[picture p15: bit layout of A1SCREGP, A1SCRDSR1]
BO_ 2566733822 A1SCREGP: 8 Vector__XXX
 SG_ InAbsPress : 40|16@1+ (0.1,0) [0|6425.5] "kPa" Vector__XXX
 SG_ InPress : 24|16@1+ (0.1,-3212.7) [-3212.7|3212.8] "kPa" Vector__XXX
 SG_ DiffPressPreliminaryFMI : 16|5@1+ (1,0) [0|31] "" Vector__XXX
 SG_ DiffPress : 0|16@1+ (0.1,0) [0|6425.5] "kPa" Vector__XXX

BO_ 2566734078 A1SCRDSR2: 8 Vector__XXX
 SG_ DEFLineHtr10 : 56|2@1+ (1,0) [0|3] "" Vector__XXX
 SG_ DEFLineHtr9 : 54|2@1+ (1,0) [0|3] "" Vector__XXX
 SG_ DEFLineHtr8 : 52|2@1+ (1,0) [0|3] "" Vector__XXX
 SG_ DEFLineHtr7 : 50|2@1+ (1,0) [0|3] "" Vector__XXX
 SG_ DEFLineHtr6 : 48|2@1+ (1,0) [0|3] "" Vector__XXX
 SG_ DEFLineHtr5 : 46|2@1+ (1,0) [0|3] "" Vector__XXX
 SG_ DEFLineHtrRelay3 : 44|2@1+ (1,0) [0|3] "" Vector__XXX
 SG_ DEFLineHtrRelay2 : 42|2@1+ (1,0) [0|3] "" Vector__XXX
 SG_ DEFLineHtrRelay1 : 40|2@1+ (1,0) [0|3] "" Vector__XXX
 SG_ DEFPumpHtrCmd : 32|8@1+ (0.4,0) [0|100] "%" Vector__XXX
 SG_ DEFQuickThawHtrCmd : 24|8@1+ (0.4,0) [0|100] "%" Vector__XXX
 SG_ DEFTankHtrCmd : 16|8@1+ (0.4,0) [0|100] "%" Vector__XXX
 SG_ DEFLineHtr4 : 14|2@1+ (1,0) [0|3] "" Vector__XXX
 SG_ DEFLineHtr3 : 12|2@1+ (1,0) [0|3] "" Vector__XXX
 SG_ DEFLineHtr2 : 10|2@1+ (1,0) [0|3] "" Vector__XXX
 SG_ DEFLineHtr1 : 8|2@1+ (1,0) [0|3] "" Vector__XXX
 SG_ DEFDoserHeatingModeReq : 4|3@1+ (1,0) [0|7] "" Vector__XXX
 SG_ DEFDoserFaultSuppressionReq : 2|2@1+ (1,0) [0|3] "" Vector__XXX

BO_ 2364548350 A1SCRDSR1: 8 Vector__XXX
 SG_ DEFDosingReqQuantity6593 : 40|16@1+ (0.05,0) [0|3212.75] "g/min" Vector__XXX
 SG_ DEFDosingTestInjPermStatus : 22|2@1+ (1,0) [0|3] "" Vector__XXX
 SG_ DEFHydStiffnessCheckPermStatus : 20|2@1+ (1,0) [0|3] "" Vector__XXX
 SG_ DEFReqQuantityOfIntegrator : 24|16@1+ (0.1,0) [0|6425.5] "g" Vector__XXX
 SG_ SysReqSt : 16|4@1+ (1,0) [0|15] "" Vector__XXX
 SG_ DEFDosingReqQuantity : 0|16@1+ (0.3,0) [0|19276.5] "g/h" Vector__XXX

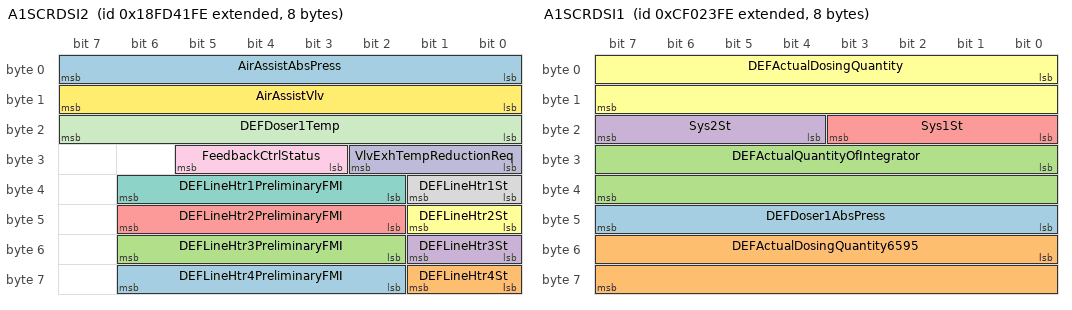
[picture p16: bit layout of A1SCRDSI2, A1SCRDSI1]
BO_ 2566734334 A1SCRDSI2: 8 Vector__XXX
 SG_ DEFLineHtr4PreliminaryFMI : 58|5@1+ (1,0) [0|31] "" Vector__XXX
 SG_ DEFLineHtr4St : 56|2@1+ (1,0) [0|3] "" Vector__XXX
 SG_ DEFLineHtr3PreliminaryFMI : 50|5@1+ (1,0) [0|31] "" Vector__XXX
 SG_ DEFLineHtr3St : 48|2@1+ (1,0) [0|3] "" Vector__XXX
 SG_ DEFLineHtr2PreliminaryFMI : 42|5@1+ (1,0) [0|31] "" Vector__XXX
 SG_ DEFLineHtr2St : 40|2@1+ (1,0) [0|3] "" Vector__XXX
 SG_ DEFLineHtr1PreliminaryFMI : 34|5@1+ (1,0) [0|31] "" Vector__XXX
 SG_ DEFLineHtr1St : 32|2@1+ (1,0) [0|3] "" Vector__XXX
 SG_ FeedbackCtrlStatus : 27|3@1+ (1,0) [0|7] "" Vector__XXX
 SG_ VlvExhTempReductionReq : 24|3@1+ (1,0) [0|7] "" Vector__XXX
 SG_ DEFDoser1Temp : 16|8@1+ (1,-40) [-40|210] "°C" Vector__XXX
 SG_ AirAssistVlv : 8|8@1+ (0.4,0) [0|100] "%" Vector__XXX
 SG_ AirAssistAbsPress : 0|8@1+ (8,0) [0|2000] "kPa" Vector__XXX

BO_ 2364548094 A1SCRDSI1: 8 Vector__XXX
 SG_ DEFDoser1AbsPress : 40|8@1+ (8,0) [0|2000] "kPa" Vector__XXX
 SG_ DEFActualDosingQuantity6595 : 48|16@1+ (0.05,0) [0|3212.75] "g/min" Vector__XXX
 SG_ DEFActualQuantityOfIntegrator : 24|16@1+ (0.1,0) [0|6425.5] "g" Vector__XXX
 SG_ Sys2St : 20|4@1+ (1,0) [0|15] "" Vector__XXX
 SG_ Sys1St : 16|4@1+ (1,0) [0|15] "" Vector__XXX
 SG_ DEFActualDosingQuantity : 0|16@1+ (0.3,0) [0|19276.5] "g/h" Vector__XXX

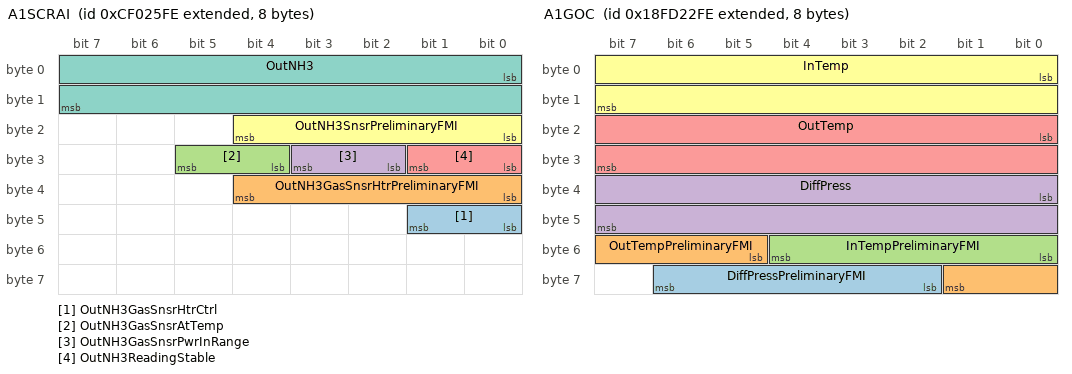
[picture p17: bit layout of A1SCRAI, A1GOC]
BO_ 2364548606 A1SCRAI: 8 Vector__XXX
 SG_ OutNH3GasSnsrHtrCtrl : 40|2@1+ (1,0) [0|3] "" Vector__XXX
 SG_ OutNH3GasSnsrHtrPreliminaryFMI : 32|5@1+ (1,0) [0|31] "" Vector__XXX
 SG_ OutNH3GasSnsrAtTemp : 28|2@1+ (1,0) [0|3] "" Vector__XXX
 SG_ OutNH3GasSnsrPwrInRange : 26|2@1+ (1,0) [0|3] "" Vector__XXX
 SG_ OutNH3ReadingStable : 24|2@1+ (1,0) [0|3] "" Vector__XXX
 SG_ OutNH3SnsrPreliminaryFMI : 16|5@1+ (1,0) [0|31] "" Vector__XXX
 SG_ OutNH3 : 0|16@1+ (0.05,-200) [-200|3012.75] "ppm" Vector__XXX

BO_ 2566726398 A1GOC: 8 Vector__XXX
 SG_ DiffPressPreliminaryFMI : 58|5@1+ (1,0) [0|31] "" Vector__XXX
 SG_ OutTempPreliminaryFMI : 53|5@1+ (1,0) [0|31] "" Vector__XXX
 SG_ InTempPreliminaryFMI : 48|5@1+ (1,0) [0|31] "" Vector__XXX
 SG_ DiffPress : 32|16@1+ (0.1,0) [0|6425.5] "kPa" Vector__XXX
 SG_ OutTemp : 16|16@1+ (0.03125,-273) [-273|1734.96875] "°C" Vector__XXX
 SG_ InTemp : 0|16@1+ (0.03125,-273) [-273|1734.96875] "°C" Vector__XXX

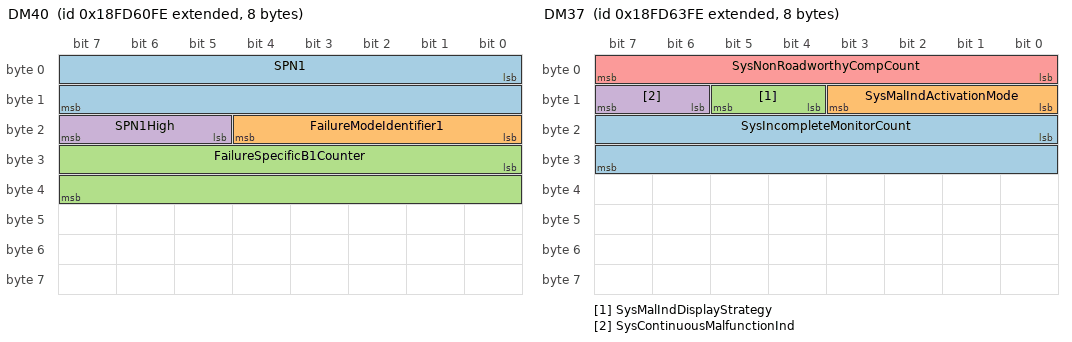
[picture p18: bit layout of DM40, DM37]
BO_ 2566742270 DM40: 8 Vector__XXX
 SG_ SPN1 : 0|16@1+ (1,0) [0|65536] "" Vector__XXX
 SG_ FailureModeIdentifier1 : 16|5@1+ (1,0) [0|0] "" Vector__XXX
 SG_ FailureSpecificB1Counter : 24|16@1+ (0.1,0) [0|6425.5] "hr" Vector__XXX
 SG_ SPN1High : 21|3@1+ (1,0) [0|7] "" Vector__XXX

BO_ 2566742526 DM39: 8 Vector__XXX
 SG_ SysGreatestB1Counter : 32|16@1+ (0.1,0) [0|6425.5] "hr" Vector__XXX
 SG_ SysCumulativeContinuousMITime : 0|32@1+ (0.05,0) [0|210554060.75] "hr" Vector__XXX

BO_ 2566742782 DM38: 8 Vector__XXX
 SG_ RegulationDescription : 0|8@1+ (1,0) [0|255] "" Vector__XXX

BO_ 2566743038 DM37: 8 Vector__XXX
 SG_ SysIncompleteMonitorCount : 16|16@1+ (1,0) [0|64512] "" Vector__XXX
 SG_ SysMalIndActivationMode : 8|4@1+ (1,0) [0|15] "" Vector__XXX
 SG_ SysMalIndDisplayStrategy : 12|2@1+ (1,0) [0|3] "" Vector__XXX
 SG_ SysContinuousMalfunctionInd : 14|2@1+ (1,0) [0|3] "" Vector__XXX
 SG_ SysNonRoadworthyCompCount : 0|8@1+ (1,0) [0|250] "" Vector__XXX

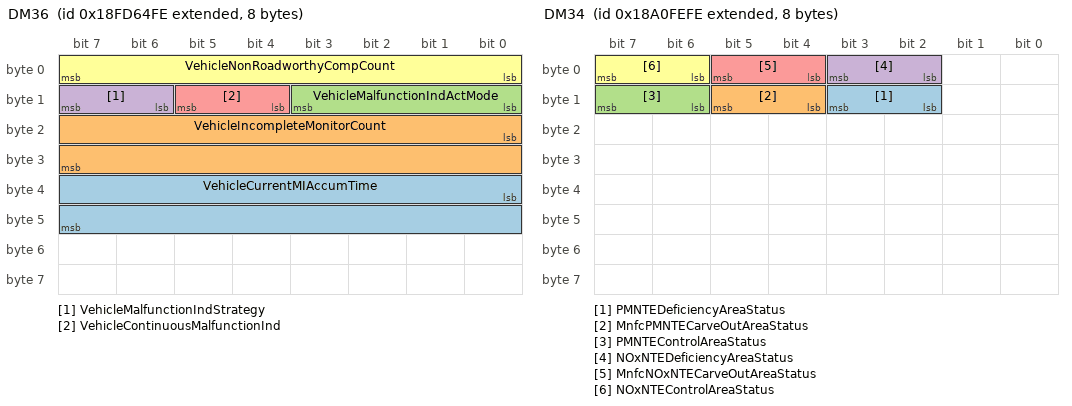
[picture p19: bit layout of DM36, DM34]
BO_ 2566743294 DM36: 8 Vector__XXX
 SG_ VehicleCurrentMIAccumTime : 32|16@1+ (1,0) [0|64255] "min" Vector__XXX
 SG_ VehicleIncompleteMonitorCount : 16|16@1+ (1,0) [0|64255] "" Vector__XXX
 SG_ VehicleMalfunctionIndActMode : 8|4@1+ (1,0) [0|15] "" Vector__XXX
 SG_ VehicleMalfunctionIndStrategy : 14|2@1+ (1,0) [0|3] "" Vector__XXX
 SG_ VehicleContinuousMalfunctionInd : 12|2@1+ (1,0) [0|3] "" Vector__XXX
 SG_ VehicleNonRoadworthyCompCount : 0|8@1+ (1,0) [0|250] "" Vector__XXX

BO_ 2560687870 DM34: 8 Vector__XXX
 SG_ PMNTEDeficiencyAreaStatus : 10|2@1+ (1,0) [0|3] "" Vector__XXX
 SG_ MnfcPMNTECarveOutAreaStatus : 12|2@1+ (1,0) [0|3] "" Vector__XXX
 SG_ PMNTEControlAreaStatus : 14|2@1+ (1,0) [0|3] "" Vector__XXX
 SG_ NOxNTEDeficiencyAreaStatus : 2|2@1+ (1,0) [0|3] "" Vector__XXX
 SG_ MnfcNOxNTECarveOutAreaStatus : 4|2@1+ (1,0) [0|3] "" Vector__XXX
 SG_ NOxNTEControlAreaStatus : 6|2@1+ (1,0) [0|3] "" Vector__XXX

BO_ 2292317950 DM33: 9 Vector__XXX
 SG_ AECDEngineHours1Timer2 : 40|32@1+ (1,0) [0|4294967295] "min" Vector__XXX
 SG_ AECDEngineHours1Timer1 : 8|32@1+ (1,0) [0|4294967295] "min" Vector__XXX
 SG_ AECDNumber1 : 0|8@1+ (1,0) [0|250] "" Vector__XXX

BO_ 2566809342 BM: 8 Vector__XXX
 SG_ BatteryMainSwitchHoldState : 0|2@1+ (1,0) [0|3] "" Vector__XXX

BO_ 2365446910 BJM3: 8 Vector__XXX
 SG_ Joystick3XAxisDetentPosStatus : 38|2@1+ (1,0) [0|3] "" Vector__XXX
 SG_ Joystick3Button9PressedStatus : 62|2@1+ (1,0) [0|3] "" Vector__XXX
 SG_ Joystick3Button10PressedStatus : 60|2@1+ (1,0) [0|3] "" Vector__XXX
 SG_ Joystick3Button11PressedStatus : 58|2@1+ (1,0) [0|3] "" Vector__XXX
 SG_ Joystick3Button12PressedStatus : 56|2@1+ (1,0) [0|3] "" Vector__XXX
 SG_ Joystick3YAxisDetentPosStatus : 36|2@1+ (1,0) [0|3] "" Vector__XXX
 SG_ Joystick3YAxisPos : 22|10@1+ (0.1,0) [0|100] "%" Vector__XXX
 SG_ Jystck3YAxsLvrFrwrdPstvPosStatus : 20|2@1+ (1,0) [0|3] "" Vector__XXX
 SG_ Jystck3YAxsLvrBckNgtivePosStatus : 18|2@1+ (1,0) [0|3] "" Vector__XXX
 SG_ Joystick3YAxisNeutralPosStatus : 16|2@1+ (1,0) [0|3] "" Vector__XXX
 SG_ Joystick3XAxisPos : 6|10@1+ (0.1,0) [0|100] "%" Vector__XXX
 SG_ Jystck3XAxsLvrRghtPstvePosStatus : 4|2@1+ (1,0) [0|3] "" Vector__XXX
 SG_ Jystck3XAxsLvrLftNgtivePosStatus : 2|2@1+ (1,0) [0|3] "" Vector__XXX
 SG_ Joystick3XAxisNeutralPosStatus : 0|2@1+ (1,0) [0|3] "" Vector__XXX
 SG_ Joystick3Button5PressedStatus : 54|2@1+ (1,0) [0|3] "" Vector__XXX
 SG_ Joystick3Button6PressedStatus : 52|2@1+ (1,0) [0|3] "" Vector__XXX
 SG_ Joystick3Button7PressedStatus : 50|2@1+ (1,0) [0|3] "" Vector__XXX
 SG_ Joystick3Button8PressedStatus : 48|2@1+ (1,0) [0|3] "" Vector__XXX
 SG_ Joystick3Button1PressedStatus : 46|2@1+ (1,0) [0|3] "" Vector__XXX
 SG_ Joystick3Button2PressedStatus : 44|2@1+ (1,0) [0|3] "" Vector__XXX
 SG_ Joystick3Button3PressedStatus : 42|2@1+ (1,0) [0|3] "" Vector__XXX
 SG_ Joystick3Button4PressedStatus : 40|2@1+ (1,0) [0|3] "" Vector__XXX

CM_ BO_ 2365403390 "Basic Joystick Message 4
Used to transfer information about the measured status of the 1st 2 axes and up to 12 buttons of a joystick.  Additional handle information is available in the Expanded Joystick Message.
10-bit position parameters are ...";
CM_ SG_ 2365403390 Joystick4Button9PressedStatus "Reports when the joystick button has been pressed.

00 Button not pressed
01 Button pressed
10 Error Indicator
11 Not Available";
CM_ SG_ 2365403390 Joystick4Button10PressedStatus "Reports when the joystick button has been pressed.

00 Button not pressed
01 Button pressed
10 Error Indicator
11 Not Available";
CM_ SG_ 2365403390 Joystick4Button11PressedStatus "Reports when the joystick button has been pressed.

00 Button not pressed
01 Button pressed
10 Error Indicator
11 Not Available";
CM_ SG_ 2365403390 Joystick4Button12PressedStatus "Reports when the joystick button has been pressed.

00 Button not pressed
01 Button pressed
10 Error Indicator
11 Not Available";
CM_ SG_ 2365403390 Joystick4Button5PressedStatus "Reports when the joystick button has been pressed.

00 Button not pressed
01 Button pressed
10 Error Indicator
11 Not Available";
CM_ SG_ 2365403390 Joystick4Button6PressedStatus "Reports when the joystick button has been pressed.

00 Button not pressed
01 Button pressed
10 Error Indicator
11 Not Available";
CM_ SG_ 2365403390 Joystick4Button7PressedStatus "Reports when the joystick button has been pressed.

00 Button not pressed
01 Button pressed
10 Error Indicator
11 Not Available";
CM_ SG_ 2365403390 Joystick4Button8PressedStatus "Reports when the joystick button has been pressed.

00 Button not pressed
01 Button pressed
10 Error Indicator
11 Not Available";
CM_ SG_ 2365403390 Joystick4Button1PressedStatus "Reports when the joystick button has been pressed.

00 Button not pressed
01 Button pressed
10 Error Indicator
11 Not Available";
CM_ SG_ 2365403390 Joystick4Button2PressedStatus "Reports when the joystick button has been pressed.

00 Button not pressed
01 Button pressed
10 Error Indicator
11 Not Available";
CM_ SG_ 2365403390 Joystick4Button3PressedStatus "Reports when the joystick button has been pressed.

00 Button not pressed
01 Button pressed
10 Error Indicator
11 Not Available";
CM_ SG_ 2365403390 Joystick4Button4PressedStatus "Reports when the joystick button has been pressed.

00 Button not pressed
01 Button pressed
10 Error Indicator
11 Not Available";
CM_ SG_ 2365403390 Joystick4XAxisDetentPosStatus "Reports when the current joystick position is in the detent position for that axis of travel.

00 Not in the Detent Position
01 In the Detent Position
10 Error Indicator
11 Not Available";
CM_ SG_ 2365403390 Joystick4YAxisDetentPosStatus "Reports when the current joystick position is in the detent position for that axis of travel.

00 Not in the Detent Position
01 In the Detent Position
10 Error Indicator
11 Not Available";
CM_ SG_ 2365403390 Joystick4YAxisPos "The position of the joystick in the relative motion of travel from the neutral position.  Position value of 0 is Neutral and position value 1000 (100%) is the end of linear zone.  Value of 1022 indicates an error has occurred.";
CM_ SG_ 2365403390 Jystck4YAxsLvrFrwrdPstvPosStatus "Reports when the current joystick position is on the positive travel side (forward, right, clockwise, up) relative to the neutral position for that axis of travel.
00 Not on Positive side of Neutral
01 On positive side of Neutral
10 Error ...";
CM_ SG_ 2365403390 Jystck4YAxsLvrBckNgtivePosStatus "Reports when the current joystick position is on the negative travel side (back, left, counterclockwise, down) relative to the neutral position for that axis of travel.
00 Not on negative side of Neutral
01 On negative side of Neutral
10 Error ...";
CM_ SG_ 2365403390 Joystick4YAxisNeutralPosStatus "Reports when the current joystick position is in the neutral position for that axis of travel.  The neutral position measurement must be determined from some mechanism other than the axis position measurement device.
00 Not in Neutral Position
01 ...";
CM_ SG_ 2365403390 Joystick4XAxisPos "The position of the joystick in the relative motion of travel from the neutral position.  Position value of 0 is Neutral and position value 1000 (100%) is the end of linear zone.  Value of 1022 indicates an error has occurred.";
CM_ SG_ 2365403390 Jystck4XAxsLvrRghtPstvePosStatus "Reports when the current joystick position is on the positive travel side (forward, right, clockwise, up) relative to the neutral position for that axis of travel.
00 Not on Positive side of Neutral
01 On positive side of Neutral
10 Error ...";
CM_ SG_ 2365403390 Jystck4XAxsLvrLftNgtivePosStatus "Reports when the current joystick position is on the negative travel side (back, left, counterclockwise, down) relative to the neutral position for that axis of travel.
00 Not on negative side of Neutral
01 On negative side of Neutral
10 Error ...";
CM_ SG_ 2365403390 Joystick4XAxisNeutralPosStatus "Reports when the current joystick position is in the neutral position for that axis of travel.  The neutral position measurement must be determined from some mechanism other than the axis position measurement device.
00 Not in Neutral Position
01 ...";
CM_ BO_ 2365400318 "Basic Joystick Message 10
Used to transfer information about the measured status of the 1st 2 axes and up to 12 buttons of a joystick.  Additional handle information is available in the Expanded Joystick Message.
10-bit position parameters are ...";
CM_ SG_ 2365400318 Joystick10Button9PressedStatus "Reports when the joystick button has been pressed.

00 Button not pressed
01 Button pressed
10 Error Indicator
11 Not Available";
CM_ SG_ 2365400318 Joystick10Button10PressedStatus "Reports when the joystick button has been pressed.

00 Button not pressed
01 Button pressed
10 Error Indicator
11 Not Available";
CM_ SG_ 2365400318 Joystick10Button11PressedStatus "Reports when the joystick button has been pressed.

00 Button not pressed
01 Button pressed
10 Error Indicator
11 Not Available";
CM_ SG_ 2365400318 Joystick10Button12PressedStatus "Reports when the joystick button has been pressed.

00 Button not pressed
01 Button pressed
10 Error Indicator
11 Not Available";
CM_ SG_ 2365400318 Joystick10Button5PressedStatus "Reports when the joystick button has been pressed.

00 Button not pressed
01 Button pressed
10 Error Indicator
11 Not Available";
CM_ SG_ 2365400318 Joystick10Button6PressedStatus "Reports when the joystick button has been pressed.

00 Button not pressed
01 Button pressed
10 Error Indicator
11 Not Available";
CM_ SG_ 2365400318 Joystick10Button7PressedStatus "Reports when the joystick button has been pressed.

00 Button not pressed
01 Button pressed
10 Error Indicator
11 Not Available";
CM_ SG_ 2365400318 Joystick10Button8PressedStatus "Reports when the joystick button has been pressed.

00 Button not pressed
01 Button pressed
10 Error Indicator
11 Not Available";
CM_ SG_ 2365400318 Joystick10Button1PressedStatus "Reports when the joystick button has been pressed.

00 Button not pressed
01 Button pressed
10 Error Indicator
11 Not Available";
CM_ SG_ 2365400318 Joystick10Button2PressedStatus "Reports when the joystick button has been pressed.

00 Button not pressed
01 Button pressed
10 Error Indicator
11 Not Available";
CM_ SG_ 2365400318 Joystick10Button3PressedStatus "Reports when the joystick button has been pressed.

00 Button not pressed
01 Button pressed
10 Error Indicator
11 Not Available";
CM_ SG_ 2365400318 Joystick10Button4PressedStatus "Reports when the joystick button has been pressed.

00 Button not pressed
01 Button pressed
10 Error Indicator
11 Not Available";
CM_ SG_ 2365400318 Joystick10XAxisDetentPosStatus "Reports when the current joystick position is in the detent position for that axis of travel.

00 Not in the Detent Position
01 In the Detent Position
10 Error Indicator
11 Not Available";
CM_ SG_ 2365400318 Joystick10YAxisDetentPosStatus "Reports when the current joystick position is in the detent position for that axis of travel.

00 Not in the Detent Position
01 In the Detent Position
10 Error Indicator
11 Not Available";
CM_ SG_ 2365400318 Joystick10YAxisPos "The position of the joystick in the relative motion of travel from the neutral position.  Position value of 0 is Neutral and position value 1000 (100%) is the end of linear zone.  Value of 1022 indicates an error has occurred.";
CM_ SG_ 2365400318 Jystck10YAxsLvrFrwrdPstvPsStatus "Reports when the current joystick position is on the positive travel side (forward, right, clockwise, up) relative to the neutral position for that axis of travel.
00 Not on Positive side of Neutral
01 On positive side of Neutral
10 Error ...";
CM_ SG_ 2365400318 Jystck10YAxsLvrBckNgtvePosStatus "Reports when the current joystick position is on the negative travel side (back, left, counterclockwise, down) relative to the neutral position for that axis of travel.
00 Not on negative side of Neutral
01 On negative side of Neutral
10 Error ...";
CM_ SG_ 2365400318 Joystick10YAxisNeutralPosStatus "Reports when the current joystick position is in the neutral position for that axis of travel.  The neutral position measurement must be determined from some mechanism other than the axis position measurement device.
00 Not in Neutral Position
01 ...";
CM_ SG_ 2365400318 Joystick10XAxisPos "The position of the joystick in the relative motion of travel from the neutral position.  Position value of 0 is Neutral and position value 1000 (100%) is the end of linear zone.  Value of 1022 indicates an error has occurred.";
CM_ SG_ 2365400318 Jystck10XAxsLvrRghtPstvPosStatus "Reports when the current joystick position is on the positive travel side (forward, right, clockwise, up) relative to the neutral position for that axis of travel.
00 Not on Positive side of Neutral
01 On positive side of Neutral
10 Error ...";
CM_ SG_ 2365400318 Jystck10XAxsLvrLftNgtvePosStatus "Reports when the current joystick position is on the negative travel side (back, left, counterclockwise, down) relative to the neutral position for that axis of travel.
00 Not on negative side of Neutral
01 On negative side of Neutral
10 Error ...";
CM_ SG_ 2365400318 Joystick10XAxisNeutralPosStatus "Reports when the current joystick position is in the neutral position for that axis of travel.  The neutral position measurement must be determined from some mechanism other than the axis position measurement device.
00 Not in Neutral Position
01 ...";
CM_ BO_ 2499614718 "Beltlock and Airbag Deactivation Switch Information
Message containing Beltlock States and the Passener Airbag Deactivation Switch State.";
CM_ SG_ 2499614718 PssngrArbgDctivationSwitchStatus "State of switch used to deactivate Passenger Airbag manually.

00 = passenger airbag activated
01 = passenger airbag deactivated
10 = Error - State of deactivation switch cannot be determined
11 = not available";
CM_ SG_ 2499614718 Beltlock10Status "State of switch used to determine if Beltlock 10 is buckled.

00 = unlocked
01 = locked
10 = Error - Beltlock state cannot be determined
11 = not available";
CM_ SG_ 2499614718 Beltlock9Status "State of switch used to determine if Beltlock 9 is buckled.

00 = unlocked
01 = locked
10 = Error - Beltlock state cannot be determined
11 = not available";
CM_ SG_ 2499614718 Beltlock8Status "State of switch used to determine if Beltlock 8 is buckled.

00 = unlocked
01 = locked
10 = Error - Beltlock state cannot be determined
11 = not available";
CM_ SG_ 2499614718 Beltlock7Status "State of switch used to determine if Beltlock 7 is buckled.

00 = unlocked
01 = locked
10 = Error - Beltlock state cannot be determined
11 = not available";
CM_ SG_ 2499614718 Beltlock6Status "State of switch used to determine if Beltlock 6 is buckled.

00 = unlocked
01 = locked
10 = Error - Beltlock state cannot be determined
11 = not available";
CM_ SG_ 2499614718 Beltlock5Status "State of switch used to determine if Beltlock 5 is buckled.

00 = unlocked
01 = locked
10 = Error - Beltlock state cannot be determined
11 = not available";
CM_ SG_ 2499614718 Beltlock4Status "State of switch used to determine if Beltlock 4 is buckled.

00 = unlocked
01 = locked
10 = Error - Beltlock state cannot be determined
11 = not available";
CM_ SG_ 2499614718 Beltlock3Status "State of switch used to determine if Beltlock 3 is buckled.

00 = unlocked
01 = locked
10 = Error - Beltlock state cannot be determined
11 = not available";
CM_ SG_ 2499614718 PassengerBeltlockStatus "State of switch used to determine if Passenger Beltlock is buckled.

00 = unlocked
01 = locked
10 = Error - Beltlock state cannot be determined
11 = not available";
CM_ SG_ 2499614718 DriverBeltlockStatus "State of switch used to determine if Driver Beltlock is buckled.

00 = unlocked
01 = locked
10 = Error - Beltlock state cannot be determined
11 = not available";
CM_ BO_ 2566722814 "Battery Charger 2
Parameters for the battery charger connected to the auxiliary battery.";
CM_ SG_ 2566722814 BatteryCharger2OutputCurrent "Output current of the battery charger connected to the main battery. If positive, this parameter shows the charging current of the battery charger connected to the main battery.  Otherwise, if the charger hardware permits, this parameter represents ...";
CM_ SG_ 2566722814 BatteryCharger2OutputVoltage "Output voltage measured on the battery terminals of the offline battery charger connected to the auxiliary battery.";
CM_ SG_ 2566722814 BatteryCharger2PowerLineState "A state of the battery charger connection to the power line for the charger connected to the auxiliary battery.
0 - Disconnected. The power line is disconnected from the charger.
1 - Connected. The power line is connected to the charger.
2 - ...";
CM_ SG_ 2566722814 BatteryCharger2State "A state of the offline battery charger connected to the auxiliary battery.
0 - Idling. The power line or the battery is disconnected from the charger.
1 - Charging the battery.
2 - Stand-by or maintaining the battery charge.
3 to 12 - Reserved
 ...";
CM_ BO_ 2566723070 "Battery Charger 1
Parameters for the battery charger connected to the main battery.";
CM_ SG_ 2566723070 BatteryCharger1OutputCurrent "Output current of the battery charger connected to the main battery. If positive, this parameter shows the charging current of the battery charger connected to the main battery.  Otherwise, if the charger hardware permits, this parameter represents ...";
CM_ SG_ 2566723070 BatteryCharger1OutputVoltage "Output voltage measured on the battery terminals of the battery charger connected to the main battery.";
CM_ SG_ 2566723070 BatteryCharger1PowerLineState "A state of the battery charger connection to the power line for the charger connected to the main battery.
0 - Disconnected. The power line is disconnected from the charger.
1 - Connected. The power line is connected to the charger.
2 - Error
3 ...";
CM_ SG_ 2566723070 BatteryCharger1State "A state of the battery charger connected to the main battery.
0 - Idling. The power line or the battery is disconnected from the charger.
1 - Charging the battery.
2 - Stand-by or maintaining the battery charge.
3 to 12 - Reserved
13 - Battery ...";
CM_ BO_ 2566725118 "Aftertreatment Differential Temperature 2 
The purpose of this PGN is to group the aftertreatment differential temperature data. These values include the differential temperature measure between the intake and outlet of aftertreatment components.";
CM_ SG_ 2566725118 TwoTWCDiffTemp "The differential engine combustion byproducts gas temperature measured between the intake and outlet of the three way catalyst for exhaust bank 2.";
CM_ SG_ 2566725118 OneTWCDiffTemp "The differential engine combustion byproducts gas temperature measured between the intake and outlet of the three way catalyst for exhaust bank 1.";
CM_ BO_ 2566725374 "Aftertreatment Differential Temperature 1 
The purpose of this PGN is to group the aftertreatment differential temperature data. These values include the differential temperature measure between the intake and outlet of aftertreatment components.";
CM_ SG_ 2566725374 TwoGOCDiffTemp "The differential engine combustion byproducts gas temperature measured between the intake and outlet of the gas oxidation catalyst for exhaust bank 2.  This parameter should be used with engine fueled by gaseous fuel like natural gas or propane ...";
CM_ SG_ 2566725374 OneGOCDiffTemp "The differential engine combustion byproducts gas temperature measured between the intake and outlet of the gas oxidation catalyst for exhaust bank 1.  This parameter should be used with engine fueled by gaseous fuel like natural gas or propane ...";
CM_ BO_ 2566712830 "Aftertreatment 2 Warm Up Diesel Oxidation Catalyst Information
This PGN contains information for the warm up oxidation catalytic converter in exhaust bank 2.";
CM_ SG_ 2566712830 OutTemp "Temperature of engine combustion byproducts leaving the warm up Diesel Oxidation Catalyst in exhaust bank 2.  This diesel parameter should be used with engines fueled by diesel fuel (not gaseous fuel like natural gas or propane).  A separate ...";
CM_ SG_ 2566712830 InTemp "Temperature of engine combustion byproducts entering the warm up Diesel Oxidation Catalyst in exhaust bank 2.  This diesel parameter should be used with engines fueled by diesel fuel (not gaseous fuel like natural gas or propane).  A separate ...";
CM_ BO_ 2566735358 "Aftertreatment 2 Three Way Catalyst
The purpose of this PGN is to group the aftertreatment Three Way Catalyst data for bank 2. These values include the intake temperature, outlet temperature and differential pressure as well as the associated ...";
CM_ SG_ 2566735358 DiffPressPreliminaryFMI "Used to identify the applicable J1939-73 FMI detected in the Three Way Catalytic Converter differential pressure sensor by the manufacturer's sensor control software in exhaust bank 2. When there is no failure FMI 31 is sent. In the case of multiple ...";
CM_ SG_ 2566735358 OutTempPreliminaryFMI "Used to identify the applicable J1939-73 FMI detected in the Three Way Catalyst outlet temperature sensor by the manufacturer's sensor control software in exhaust bank 2. When there is no failure FMI 31 is sent. In the case of multiple failures the ...";
CM_ SG_ 2566735358 InTempPreliminaryFMI "Used to identify the applicable J1939-73 FMI detected in the Three Way Catalyst intake temperature sensor by the manufacturer's sensor control software in exhaust bank 2. When there is no failure FMI 31 is sent. In the case of multiple failures the ...";
CM_ SG_ 2566735358 DiffPress "Exhaust differential pressure measured between the intake and exhaust of a Three Way Catalyst in exhaust bank 2.

(For a single exhaust bank system, refer to parameters in PGN 64838.)";
CM_ SG_ 2566735358 OutTemp "Temperature of engine combustion byproducts leaving the Three Way Catalyst in exhaust bank 2. 
 
(For a single exhaust bank system, refer to parameters in PGN 64838.)";
CM_ SG_ 2566735358 InTemp "Temperature of engine combustion byproducts entering the Three Way Catalyst in exhaust bank 2.

(For a single exhaust bank system, refer to parameters in PGN 64838.)";
CM_ BO_ 2365393662 "Aftertreatment 2 Outlet Gas NOx Sensor Correction Data 2";
CM_ SG_ 2365393662 CorrectedNOx "The corrected outlet NOx value  for aftertreatment 2 shall include all learned adaptions and offsets that are used to adjust the raw signal.
2016 MY and later engines with NOx sensors may be required to output a ‘corrected' NOx sensor signal in ...";
CM_ SG_ 2365393662 NOxSnsrSelfDiagFinalResult "Self-diagnosis result for NOx sensor ATO2 (Aftertreatment Outlet Bank 2) as a ratio of detected value to reference value defined by supplier.
This result is used to determine if the signal resulting from the self-diagnosis test (as represented as a ...";
CM_ SG_ 2365393662 NOxSnsrNH3Correction "Correction of NH3 at the NOx-signal to correct (recalculate) sensor signal on the Engine ECU side.";
CM_ SG_ 2365393662 NOxSnsrNO2Correction "Correction of NO2 at the NOx-signal to correct (recalculate) sensor signal on the Engine ECU side.";
CM_ SG_ 2365393662 NOxSnsrNOxPressCorrection "Correction of pressure NOx-signal to correct (recalculate) sensor signal on the Engine ECU side.";
CM_ SG_ 2365393662 NOxSnsrO2PressCorrection "Correction of pressure Lambda-signal to correct (recalculate) sensor signal on the Engine ECU side.";
CM_ BO_ 2365393918 "Aftertreatment 2 Outlet Gas NOx Sensor Correction Data 1";
CM_ SG_ 2365393918 NOxSnsrOpHours "Counted hours that the NOx-sensor was operated with status 'dewpoint reached'";
CM_ SG_ 2365393918 NOxSnsrNewPartDeviationNOxOffset "New part deviation NOx_Offset to correct (recalculate) sensor signal on the Engine ECU side.";
CM_ SG_ 2365393918 NOxSnsrNewPartDeviationNOxGain "New part deviation NOx_Gain to correct (recalculate) sensor signal on the Engine ECU side.";
CM_ SG_ 2365393918 NOxSnsrHtrRatio "Heater ratio to determine temperature at sensor tip.";
CM_ BO_ 2365394174 "Aftertreatment 2 Intake Gas NOx Sensor Correction Data 2";
CM_ SG_ 2365394174 SCRInCorrectedNOx "The corrected intake Selective Catalytic Reduction NOx value for aftertreatment 2 shall include all learned adaptions and offsets that are used to adjust the raw signal.
2016 MY and later engines with NOx sensors may be required to output a ...";
CM_ SG_ 2365394174 NOxSnsrSelfDiagFinalResult "Self-diagnosis result for NOx sensor ATI2 (Aftertreatment Intake Bank 2) as a ratio of detected value to reference value defined by supplier.
This result is used to determine if the signal resulting from the self-diagnosis test (as represented as a ...";
CM_ SG_ 2365394174 NOxSnsrNH3Correction "Correction of NH3 at the NOx-signal to correct (recalculate) sensor signal on the Engine ECU side.";
CM_ SG_ 2365394174 NOxSnsrNO2Correction "Correction of NO2 at the NOx-signal to correct (recalculate) sensor signal on the Engine ECU side.";
CM_ SG_ 2365394174 NOxSnsrNOxPressCorrection "Correction of pressure NOx-signal to correct (recalculate) sensor signal on the Engine ECU side.";
CM_ SG_ 2365394174 NOxSnsrO2PressCorrection "Correction of pressure Lambda-signal to correct (recalculate) sensor signal on the Engine ECU side.";
CM_ BO_ 2365394430 "Aftertreatment 2 Intake Gas NOx Sensor Correction Data 1";
CM_ SG_ 2365394430 NOxSnsrOpHours "Counted hours that the NOx-sensor was operated with status 'dewpoint reached'";
CM_ SG_ 2365394430 NOxSnsrNewPartDeviationNOxOffset "New part deviation NOx_Offset to correct (recalculate) sensor signal on the Engine ECU side.";
CM_ SG_ 2365394430 NOxSnsrNewPartDeviationNOxGain "New part deviation NOx_Gain to correct (recalculate) sensor signal on the Engine ECU side.";
CM_ SG_ 2365394430 NOxSnsrHtrRatio "Heater ratio to determine temperature at sensor tip.";
CM_ BO_ 2566735102 "Aftertreatment 2 Fuel Control 2
Contains information about the aftertreatment 2 fuel system. See also PGN 64928.";
CM_ SG_ 2566735102 Press2Ctrl "Indicates how the device is controlling the aftertreatment 2 fuel pressure 2 regulating control valve.   0% = fully closed, 100%=fully open.";
CM_ SG_ 2566735102 FlowDiverterVlvCtrl "Indicates how the device is controlling the aftertreatment 2 fuel flow diverter valve. When this valve is on it diverts fuel flow from the Aftertreatment 2 Regeneration Device.

00 off
01 on
10 reserved for SAE assignment
11 not available";
CM_ SG_ 2566735102 PumpRelayCtrl "Indicates how the device is controlling the aftertreatment 2 fuel pump relay.

00 off
01 on
10 reserved for SAE assignment
11 not available";
CM_ SG_ 2566735102 Press2 "Second fuel pressure measurement for the aftertreatment 2 system.";
CM_ BO_ 2157313790 "Aftertreatment 2 Diesel Particulate Filter Soot Sensor Calibration
The purpose of this PGN is to group the Aftertreatment 2 DPF soot measurement calibration parameters. These values include soot sensor signal mean and standard deviation calibration ...";
CM_ SG_ 2157313790 StdDeviationCalOffset "Calibration offset for the soot standard deviation for Aftertreatment 2 Diesel Particulate Filter soot sensor.";
CM_ SG_ 2157313790 MeanCalOffset "Calibration offset for the soot Mean for Aftertreatment 2 Diesel Particulate Filter soot sensor.";
CM_ BO_ 2566724350 "Aftertreatment 1 Warm Up Diesel Oxidation Catalyst Information
This PGN contains information for the warm up oxidation catalytic converter in exhaust bank 1.";
CM_ SG_ 2566724350 OutTemp "This is the temperature measured at the outlet of the warm up oxidation catalytic converter in exhaust bank 1.";
CM_ SG_ 2566724350 InTemp "This is the temperature measured at the intake of the warm up oxidation catalytic converter in exhaust bank 1.";
CM_ BO_ 2566735614 "Aftertreatment 1 Three Way Catalyst
The purpose of this PGN is to group the aftertreatment Three Way Catalyst data for bank 1. These values include the intake temperature, outlet temperature and differential pressure as well as the associated ...";
CM_ SG_ 2566735614 DiffPressPreliminaryFMI "Used to identify the applicable J1939-73 FMI detected in the Three Way Catalytic Converter differential pressure sensor by the manufacturer's sensor control software in exhaust bank 1. When there is no failure FMI 31 is sent. In the case of multiple ...";
CM_ SG_ 2566735614 OutTempPreliminaryFMI "Used to identify the applicable J1939-73 FMI detected in the Three Way Catalyst outlet temperature sensor by the manufacturer's sensor control software in exhaust bank 1. When there is no failure FMI 31 is sent. In the case of multiple failures the ...";
CM_ SG_ 2566735614 InTempPreliminaryFMI "Used to identify the applicable J1939-73 FMI detected in the Three Way Catalyst intake temperature sensor by the manufacturer's sensor control software in exhaust bank 1. When there is no failure FMI 31 is sent. In the case of multiple failures the ...";
CM_ SG_ 2566735614 DiffPress "Exhaust differential pressure measured between the intake and exhaust of a Three Way Catalyst in exhaust bank 1.";
CM_ SG_ 2566735614 OutTemp "Temperature of engine combustion byproducts leaving the Three Way Catalyst in exhaust bank 1.";
CM_ SG_ 2566735614 InTemp "Temperature of engine combustion byproducts entering the Three Way Catalyst in exhaust bank 1.";
CM_ BO_ 2566805246 "Aftertreatment 1 Diesel Exhaust Fluid Tank 1 Information 1
Contains information on various tank levels";
CM_ SG_ 2566805246 HtrPreliminaryFMI "Used to identify the applicable J1939-73 FMI detected for the heater of the diesel exhaust fluid tank for aftertreatment system 1 (exhaust bank 1), as detected by the manufacturer's control software.  When there is no failure, FMI 31 is sent. In the ...";
CM_ SG_ 2566805246 Htr "Percentage of heating applied to the aftertreatment 1 diesel exhaust fluid tank heater.  A value of 0% means no heating applied, a value of 100% means full heating applied.  The diesel exhaust fluid tank heater warms the diesel exhaust fluid in the ...";
CM_ SG_ 2566805246 SCROpIndSev "Severity status of the operator inducement system for anomalies with the SCR system, such as tampering, low DEF quality, and DEF tank level.  Higher numerical levels indicate more severe levels of inducement.  Level 1 is the least severe.
000 - ...";
CM_ SG_ 2566805246 TempPreliminaryFMI "Used to identify the applicable J1939-73 FMI detected for the diesel exhaust fluid tank temperature for aftertreatment system 1 (exhaust bank 1), as detected by the manufacturer's control software. When there is no failure, FMI 31 is sent. In the ...";
CM_ SG_ 2566805246 DEFTankLowLvlInd "The desired illumination of the driver's warning indicator for diesel exhaust fluid (DEF) tank low level.
000 - Off -  indicates adequate DEF level
e.g., for Euro VI this is used to indicate the driver warning system is non-active for diesel ...";
CM_ SG_ 2566805246 LvlVolPreliminaryFMI "Used to identify the applicable J1939-73 FMI detected in the diesel exhaust fluid tank level sensor by the manufacturer's sensor control software.  This FMI is applicable to either the diesel exhaust fluid tank level or diesel exhaust fluid tank ...";
CM_ SG_ 2566805246 Lvl "The diesel exhaust fluid level height in mm in the diesel exhaust fluid storage container for aftertreatment system 1 (exhaust bank 1).  See SPN 1761 and SPN 7530 for alternate measurements.
Parameter Specific Indicator:
A value of 0xFB indicates ...";
CM_ SG_ 2566805246 Temp1 "Temperature of the diesel exhaust fluid in the storage tank.";
CM_ SG_ 2566805246 Volume "Ratio of volume of diesel exhaust fluid to the total volume of diesel exhaust fluid storage container for aftertreatment system 1 (exhaust bank 1).  0% is empty and 100% is full.  See SPN 3517 and SPN 7530 for alternate measurements.
Parameter ...";
CM_ BO_ 2365394686 "Aftertreatment 1 Outlet Gas NOx Sensor Correction Data 2";
CM_ SG_ 2365394686 CorrectedNOx "The corrected outlet NOx value for aftertreatment 1 shall include all learned adaptions and offsets that are used to adjust the raw signal.
2016 MY and later engines with NOx sensors may be required to output a ‘corrected' NOx sensor signal in ...";
CM_ SG_ 2365394686 NOxSnsrSelfDiagFinalResult "Self-diagnosis result for NOx sensor ATO1 (Aftertreatment Outlet Bank 1) as a ratio of detected value to reference value defined by supplier.
This result is used to determine if the signal resulting from the self-diagnosis test (as represented as a ...";
CM_ SG_ 2365394686 NOxSnsrNH3Correction "Correction of NH3 at the NOx-signal to correct (recalculate) sensor signal on the Engine ECU side.";
CM_ SG_ 2365394686 NOxSnsrNO2Correction "Correction of NO2 at the NOx-signal to correct (recalculate) sensor signal on the Engine ECU side.";
CM_ SG_ 2365394686 NOxSnsrNOxPressCorrection "Correction of pressure NOx-signal to correct (recalculate) sensor signal on the Engine ECU side.";
CM_ SG_ 2365394686 NOxSnsrO2PressCorrection "Correction of pressure Lambda-signal to correct (recalculate) sensor signal on the Engine ECU side.";
CM_ BO_ 2365394942 "Aftertreatment 1 Outlet Gas NOx Sensor Correction Data 1";
CM_ SG_ 2365394942 NOxSnsrOpHours "Counted hours that the NOx-sensor was operated with status 'dewpoint reached'";
CM_ SG_ 2365394942 NOxSnsrNewPartDeviationNOxOffset "New part deviation NOx_Offset to correct (recalculate) sensor signal on the Engine ECU side.";
CM_ SG_ 2365394942 NOxSnsrNewPartDeviationNOxGain "New part deviation NOx_Gain to correct (recalculate) sensor signal on the Engine ECU side.";
CM_ SG_ 2365394942 NOxSnsrHtrRatio "Heater ratio to determine temperature at sensor tip.";
CM_ BO_ 2365395198 "Aftertreatment 1 Intake Gas NOx Sensor Correction Data 2";
CM_ SG_ 2365395198 SCRInCorrectedNOx "The corrected intake Selective Catalytic Reduction NOx value for aftertreatment 1 shall include all learned adaptions and offsets that are used to adjust the raw signal.
2016 MY and later engines with NOx sensors may be required to output a ...";
CM_ SG_ 2365395198 NOxSnsrSelfDiagFinalResult "Self-diagnosis result for NOx sensor ATI1 (Aftertreatment Intake Bank 1) as a ratio of detected value to reference value defined by supplier.
This result is used to determine if the signal resulting from the self-diagnosis test (as represented as a ...";
CM_ SG_ 2365395198 NOxSnsrNH3Correction "Correction of NH3 at the NOx-signal to correct (recalculate) sensor signal on the Engine ECU side.";
CM_ SG_ 2365395198 NOxSnsrNO2Correction "Correction of NO2 at the NOx-signal to correct (recalculate) sensor signal on the Engine ECU side.";
CM_ SG_ 2365395198 NOxSnsrNOxPressCorrection "Correction of pressure NOx-signal to correct (recalculate) sensor signal on the Engine ECU side.";
CM_ SG_ 2365395198 NOxSnsrO2PressCorrection "Correction of pressure Lambda-signal to correct (recalculate) sensor signal on the Engine ECU side.";
CM_ BO_ 2365395454 "Aftertreatment 1 Intake Gas NOx Sensor Correction Data 1";
CM_ SG_ 2365395454 NOxSnsrOpHours "Counted hours that the NOx-sensor was operated with status 'dewpoint reached'";
CM_ SG_ 2365395454 NOxSnsrNewPartDeviationNOxOffset "New part deviation NOx_Offset to correct (recalculate) sensor signal on the Engine ECU side.";
CM_ SG_ 2365395454 NOxSnsrNewPartDeviationNOxGain "New part deviation NOx_Gain to correct (recalculate) sensor signal on the Engine ECU side.";
CM_ SG_ 2365395454 NOxSnsrHtrRatio "Heater ratio to determine temperature at sensor tip.";
CM_ BO_ 2157248254 "Aftertreatment 1 Diesel Particulate Filter Soot Sensor Calibration
The purpose of this PGN is to group the Aftertreatment 1 DPF soot measurement calibration parameters. These values include soot sensor signal mean and standard deviation calibration ...";
CM_ SG_ 2157248254 StdDeviationCalOffset "Calibration offset for the soot standard deviation for Aftertreatment 1 Diesel Particulate Filter soot sensor.";
CM_ SG_ 2157248254 MeanCalOffset "Calibration offset for the soot Mean for Aftertreatment 1 Diesel Particulate Filter soot sensor.";
CM_ BO_ 2566711806 "Armrest Switch Matrix Commands
Operator commands sent via the Armrest Switch Matrices.";
CM_ SG_ 2566711806 Armrest2Switch2 "Status of the second switch located in armrest 2.

00: Off
01: On
10: Reserved
11: Don't care/take no action";
CM_ SG_ 2566711806 Armrest2Switch1 "Status of the first switch located in armrest 2.

00: Off
01: On
10: Reserved
11: Don't care/take no action";
CM_ SG_ 2566711806 Armrest1Switch2 "Status of the second switch located in armrest 1.

00: Off
01: On
10: Reserved
11: Don't care/take no action";
CM_ SG_ 2566711806 Armrest1Switch1 "Status of the first switch located in armrest 1.

00: Off
01: On
10: Reserved
11: Don't care/take no action";
CM_ BO_ 2364549886 "Angular Rate Information
The Angular Rate Information message shall provide a measurement of the vehicle's pitch rate, roll rate, and yaw rate measurements.  The vehicle dynamics measurements in this message shall be according to a Z-Down axis ...";
CM_ SG_ 2364549886 AngularRateMeasurementLatency "The estimated measurement latency of the measurement.
NOTE: This is only the sensor latency and does not include any additional latencies that might exist because of the CAN Bus or overall system implementation. Latency is the time from sensor ...";
CM_ SG_ 2364549886 YawRateExRangeFigureOfMerit "Figure of merit for yaw angle measurement.

00 = Yaw rate fully functional. Data is within sensor specification.
01 = Yaw rate degraded. Data is suspect due to environmental conditions.
10 = Error
11 = Not available";
CM_ SG_ 2364549886 RollRateExRangeFigureOfMerit "Figure of merit for roll rate measurement.

00 = Roll rate fully functional. Data is within sensor specification.
01 = Roll rate degraded. Data is suspect due to environmental conditions.
10 = Error
11 = Not available";
CM_ SG_ 2364549886 PitchRateExRangeFigureOfMerit "Figure of merit for pitch rate measurement.

00 = Pitch rate fully functional. Data is within sensor specification.
01 = Pitch rate degraded. Data is suspect due to environmental conditions.
10 = Error
11 = Not available";
CM_ SG_ 2364549886 YawRateExRange "Yaw rate is the rate-of-change of the yaw angle over time.  A positive yaw rate signal results when the object turns clockwise.  This parameter is defined according to a Z-Down axis system and the sign of the value is in accordance to the right-hand ...";
CM_ SG_ 2364549886 RollRateExRange "Roll rate is the rate-of-change of the roll angle over time.  The roll rate for increasing roll to the right is reported with a positive value. Roll angle is the same for both Z-Down and Z-Up axis systems, since both systems have positive X axis ...";
CM_ SG_ 2364549886 PitchRateExRange "Pitch rate is the rate-of-change of the pitch angle over time, where the pitch angle vector is in the direction of travel of the vehicle. The pitch rate for increasing ascent over time is reported with a positive value. This parameter is defined ...";
CM_ BO_ 2566712318 "Aftertreatment 2 NOx Adsorber Information
This message contains NOx adsorber information for aftertreatment system 2 (or bank 2).";
CM_ SG_ 2566712318 DesulfationStatus "Indicates whether the NOx adsorber desulfation regeneration in the second aftertreatment system is active or inactive

00  Inactive
01  Active
10  Error indicator
11  Not available";
CM_ SG_ 2566712318 RegenStatus "Indicates whether the NOx adsorber regeneration in the second aftertreatment system is active or inactive

00  Inactive
01  Active
10  Error indicator
11  Not available";
CM_ BO_ 2566712574 "Aftertreatment 1 NOx Adsorber Information
This message contains NOx adsorber information for aftertreatment system 1 (or bank 1).";
CM_ SG_ 2566712574 DesulfationStatus "Indicates whether the NOx adsorber desulfation regeneration in the first aftertreatment system is active or inactive

00  Inactive
01  Active
10  Error indicator
11  Not available";
CM_ SG_ 2566712574 RegenStatus "Indicates whether the NOx adsorber regeneration in the first aftertreatment system is active or inactive.

00  Inactive
01  Active
10  Error indicator
11  Not available";
CM_ BO_ 2164078590 "Aftertreatment 2 SCR Service Information 1
This message contains SCR service information for aftertreatment system 2 (or bank 2).";
CM_ SG_ 2164078590 ConversionEfficiency "The SCR conversion efficiency percentage.  Calculated as 100 times the catalyst intake NOx minus the catalyst outlet NOx divided by the catalyst intake NOx.  The catalyst conversion efficiency number in itself does not imply emissions compliance or ...";
CM_ SG_ 2164078590 CommandedDEFConsumption "This parameter transmits the amount of diesel exhaust fluid that the emissions control system has requested to be used, averaged over the past 15 hours of engine operation.
Used to determine whether the SCR system is using an appropriate amount of ...";
CM_ SG_ 2164078590 DEFAvgConsumption "Measured use of diesel exhaust fluid by a Selective Catalytic Reduction system for exhaust emission control, averaged over the previous 15 hours of engine operation.
Used to determine whether the SCR system is using an appropriate amount of diesel ...";
CM_ BO_ 2566731006 "Aftertreatment 2 SCR Reagant Tank 2 Information
This message contains SCR reagent tank 2 information for aftertreatment system 2 (or bank 2).  The second tank for the aftertreatment system is usually a smaller quick-thaw reagent tank located in ...";
CM_ SG_ 2566731006 DEFQuickThawHtrPreliminaryFMI "Used to identify the applicable J1939-73 FMI detected for the heater of the diesel exhaust fluid quick thaw tank for aftertreatment system 2 (exhaust bank 2), as detected by the manufacturer's control software.  When there is no failure, FMI 31 is ...";
CM_ SG_ 2566731006 DEFQuickThawHtr "The diesel exhaust fluid quick thaw tank heater percentage for aftertreatment system 2 (exhaust bank 2). 0% is off. See SPN 5415 for the command for this tank heater.";
CM_ SG_ 2566731006 DEFQuickThawTempPreliminaryFMI "Used to identify the applicable J1939-73 FMI detected for the diesel exhaust fluid quick thaw tank temperature for aftertreatment system 2 (exhaust bank 2), as detected by the manufacturer's control software. When there is no failure, FMI 31 is ...";
CM_ SG_ 2566731006 DEFQuickThawLvlPreliminaryFMI "Used to identify the applicable J1939-73 FMI detected for the fluid level height of the diesel exhaust fluid quick thaw tank for aftertreatment system 2 (exhaust bank 2), as detected by the manufacturer's control software.  This FMI is applicable to ...";
CM_ SG_ 2566731006 DEFQuickThawTankLvl "The diesel exhaust fluid level height in mm in the diesel exhaust fluid quick thaw tank for aftertreatment system 2 (exhaust bank 2).  See SPN 4433 for alternate measurement.
Parameter Specific Indicator:
A value of 0xFB indicates conditions are ...";
CM_ SG_ 2566731006 DEFQuickThawTemp "The diesel exhaust fluid quick thaw tank temperature for aftertreatment system 2 (exhaust bank 2).";
CM_ SG_ 2566731006 DEFQuickThawTankVolume "Ratio of volume of diesel exhaust fluid to the total volume of diesel exhaust fluid storage container for aftertreatment system 2 (exhaust bank 2).  0% is empty and 100% is full.  An alternative to this SPN is SPN 4435.
Parameter Specific ...";
CM_ BO_ 2566731262 "Aftertreatment 2 Diesel Exhaust Fluid Tank 1 Information 1
This message contains diesel exhaust fluid tank 1 information for aftertreatment system 2 (or bank 2).  The first tank for the aftertreatment sytem is primary reagent storage tank.";
CM_ SG_ 2566731262 HtrPreliminaryFMI "Used to identify the applicable J1939-73 FMI detected for the heater of the diesel exhaust fluid tank for aftertreatment system 2 (exhaust bank 2), as detected by the manufacturer's control software.  When there is no failure, FMI 31 is sent. In the ...";
CM_ SG_ 2566731262 Htr "Percentage of heating applied to the aftertreatment 2 diesel exhaust fluid tank heater.  A value of 0% means no heating applied, a value of 100% means full heating applied.  The diesel exhaust fluid tank heater warms the diesel exhaust fluid in the ...";
CM_ SG_ 2566731262 TempPreliminaryFMI "Used to identify the applicable J1939-73 FMI detected for the diesel exhaust fluid tank temperature for aftertreatment system 2 (exhaust bank 2), as detected by the manufacturer's control software. When there is no failure, FMI 31 is sent. In the ...";
CM_ SG_ 2566731262 LvlVolPreliminaryFMI "Used to identify the applicable J1939-73 FMI detected in the diesel exhaust fluid tank level sensor by the manufacturer's sensor control software.  This FMI is applicable to either the diesel exhaust fluid tank level or diesel exhaust fluid tank ...";
CM_ SG_ 2566731262 Lvl "The diesel exhaust fluid level height in mm in the diesel exhaust fluid storage container for aftertreatment system 2 (exhaust bank 2).  See SPN 4426 and SPN 7531 for alternate measurements.
Parameter Specific Indicator:
A value of 0xFB indicates ...";
CM_ SG_ 2566731262 Temp1 "Temperature of the diesel exhaust fluid in the storage tank.";
CM_ SG_ 2566731262 Volume "Ratio of volume of diesel exhaust fluid to the total volume of the diesel exhaust fluid storage container for aftertreatment system 2 (exhaust bank 2).  0% is empty and 100% is full.  See SPN 4428 and SPN 7531 for alternate measurements.
Parameter ...";
CM_ BO_ 2566730750 "Aftertreatment 2 Diesel Exhaust Fluid Supply Information
This message contains diesel exhaust fluid supply information for aftertreatment system 2 (or bank 2).";
CM_ SG_ 2566730750 DosingUnit2DiverterVlv "Command to the valve which determines whether the diesel exhaust fluid of dosing unit 2 is delivered to the injector or is routed back to the diesel exhaust fluid tank. Zero directs all diesel exhaust fluid flow to the injector, 100% sends all ...";
CM_ SG_ 2566730750 TankDrainVlvCmd "Commanded percentage of maximum Aftertreatment 2 Diesel Exhaust Fluid Tank Drain Valve opening. 100% means the the drain valve is fully open providing maximum flow of diesel exhaust fluid out of  the diesel exhaust fluid tank.";
CM_ SG_ 2566730750 PumpSt "State of Aftertreatment 2 Diesel Exhaust Fluid dosing pump.

00  pump operational
01  pump error
10  reserved for SAE assignment
11 not available";
CM_ SG_ 2566730750 TankFillVlvCmd "Commanded percentage of maximum Aftertreatment 2 Diesel Exhaust Fluid Tank Fill Valve opening. 100% means the fill valve is fully open providing maximum flow of diesel exhaust fluid into the diesel exhaust fluid tank.";
CM_ SG_ 2566730750 DosingUnit1DiverterVlv "Command to the valve which determines whether the diesel exhaust fluid of dosing unit 1 is delivered to the injector or is routed back to the diesel exhaust fluid tank. Zero directs all diesel exhaust fluid flow to the injector, 100% sends all ...";
CM_ SG_ 2566730750 PumpDrivePercentage "The percent (command) sent to the motor to control the speed of  the diesel exhaust fluid pump.";
CM_ SG_ 2566730750 Pump1MotorSpd "Rotational speed of the motor driving the first or only pump for the diesel exhaust fluid used in aftertreatment system 2 (exhaust bank 2).";
CM_ BO_ 2566731518 "Aftertreatment 2 Diesel Exhaust Fluid Information 1
Sensor Information which measures temperature, concentration, and conductivity of the diesel exhaust fluid of the aftertreatment 2 system.";
CM_ SG_ 2566731518 TypeProperty "This parameter indicates the property of the fluid compound in the tank.  A value of 0011 indicates uncontaminated Diesel Exhaust Fluid.
0000 - Urea concentration too high
0001 - Urea concentration too low
0010 - Fluid is diesel
0011 - Diesel ...";
CM_ SG_ 2566731518 PropertiesPreliminaryFMI "Used to identify the applicable J1939-73 FMI that applies to the most significant failure of the diesel exhaust fluid properties sensor.  This may be used for indicating failures of the diesel exhaust fluid concentration, diesel exhaust fluid ...";
CM_ SG_ 2566731518 Temp2PreliminaryFMI "Used to identify the applicable J1939-73 FMI that applies to the most significant failure of the diesel exhaust fluid temperature sensor.  When there is no failure FMI 31 is sent. In the case of multiple failures the most severe is communicated.";
CM_ SG_ 2566731518 Conductivity "A measure of the conductivity of the diesel exhaust fluid at the sensor.  The conductivity is an indication of the diesel exhaust fluid's chemical make up.";
CM_ SG_ 2566731518 Concentration "A measure of the concentration of urea in water.  Zero percent means that the tank contains no urea.  A 32.5% value indicates that the reagent is of the proper concentration.  The 32.5% value indicates that the concentration is highest quality.
 ...";
CM_ SG_ 2566731518 Temp2 "Temperature of the diesel exhaust fluid at the device measuring diesel exhaust fluid quality";
CM_ BO_ 2566732030 "Aftertreatment 2 SCR Exhaust Gas Temperature 1
This message contains SCR catalyst intake and outlet exhaust gas temperature information for aftertreatment system 2 (or bank 2).";
CM_ SG_ 2566732030 OutTempPreliminaryFMI "Used to identify the applicable J1939-73 FMI detected in the SCR outlet temperature sensor by the manufacturer's sensor control software in exhaust bank 2. When there is no failure FMI 31 is sent. In the case of multiple failures the most severe is ...";
CM_ SG_ 2566732030 OutTemp "Temperature of engine combustion byproducts leaving the SCR exhaust in exhaust bank 2.";
CM_ SG_ 2566732030 InTempPreliminaryFMI "Used to identify the applicable J1939-73 FMI detected in the SCR intake temperature sensor by the manufacturer's sensor control software in exhaust bank 2. When there is no failure FMI 31 is sent. In the case of multiple failures the most severe is ...";
CM_ SG_ 2566732030 InTemp "Temperature of engine combustion byproducts entering the SCR in exhaust bank 2.";
CM_ BO_ 2566732286 "Aftertreatment 2 SCR Exhaust Gas Pressures
This message contains SCR catalyst exhaust gas pressure information for aftertreatment system 2 (or bank 2).";
CM_ SG_ 2566732286 InAbsPress "Used to read the pressure at the catalyst intake of the selective catalytic reduction system of aftertreatment 2.";
CM_ SG_ 2566732286 InPress "The gage pressure at the intake of the selective catalytic reduction system of Aftertreatment 2.";
CM_ SG_ 2566732286 DiffPressPreliminaryFMI "Used to identify the applicable J1939-73 FMI detected in the SCR differential pressure sensor by the manufacturer's sensor control software in exhaust bank 2. When there is no failure FMI 31 is sent. In the case of multiple failures the most severe ...";
CM_ SG_ 2566732286 DiffPress "Differential pressure measured between the intake and exhaust of an SCR component in exhaust bank 2.";
CM_ BO_ 2164079358 "Aftertreatment 2 SCR Dosing System Requests 2
This message contains SCR dosing system request information for aftertreatment system 2 (or bank 2).";
CM_ SG_ 2164079358 DEFLineHtr10 "The diesel exhaust fluid line heater 10 request for aftertreatment system 2 (exhaust bank 2).

00 = request for heater to be inactive
01 = request for heater to be active
10 = reserved for future assignment by SAE
11 = not available";
CM_ SG_ 2164079358 DEFLineHtr9 "The diesel exhaust fluid line heater 9 request for aftertreatment system 2 (exhaust bank 2).

00 = request for heater to be inactive
01 = request for heater to be active
10 = reserved for future assignment by SAE
11 = not available";
CM_ SG_ 2164079358 DEFLineHtr8 "The diesel exhaust fluid line heater 8 request for aftertreatment system 2 (exhaust bank 2).

00 = request for heater to be inactive
01 = request for heater to be active
10 = reserved for future assignment by SAE
11 = not available";
CM_ SG_ 2164079358 DEFLineHtr7 "The diesel exhaust fluid line heater 7 request for aftertreatment system 2 (exhaust bank 2).

00 = request for heater to be inactive
01 = request for heater to be active
10 = reserved for future assignment by SAE
11 = not available";
CM_ SG_ 2164079358 DEFLineHtr6 "The diesel exhaust fluid line heater 6 request for aftertreatment system 2 (exhaust bank 2).

00 = request for heater to be inactive
01 = request for heater to be active
10 = reserved for future assignment by SAE
11 = not available";
CM_ SG_ 2164079358 DEFLineHtr5 "Identifies the diesel exhaust fluid line heater 5 request for aftertreatment system 2 (exhaust bank 2).

00 request for heater to be inactive 
01 request for heater to be active 
10 reserved for future assignment by SAE 
11 not available";
CM_ SG_ 2164079358 DEFLineHtrRelay3 "The aftertreatment system 2 diesel exhaust fluid line heater relay 3 is used to energize one or more DEF line heaters.

00 - Off
01 - On
10 - Error
11 - Not available";
CM_ SG_ 2164079358 DEFLineHtrRelay2 "The aftertreatment system 2 diesel exhaust fluid line heater relay 2 is used to energize one or more DEF line heaters.

00 - Off
01 - On
10 - Error
11 - Not available";
CM_ SG_ 2164079358 DEFLineHtrRelay1 "The aftertreatment system 2 diesel exhaust fluid line heater relay 1 is used to energize one or more DEF line heaters.

00 - Off
01 - On
10 - Error
11 - Not available";
CM_ SG_ 2164079358 DEFQuickThawHtrCmd "The command for the heater of the diesel exhaust fluid quick thaw tank for aftertreatment system 2 (exhaust bank 2).  See SPN 4438 for the measured heater percentage for the heater of this same tank.";
CM_ SG_ 2164079358 DEFTankHtrCmd "Command for the Aftertreatment 2 Diesel Exhaust Fluid Tank Heater.  A value of 0% means no heating applied, a value of 100% means full heating applied.  See SPN 4431 for the measured value of the Aftertreatment 2 Diesel Exhaust Fluid Tank Heater.";
CM_ SG_ 2164079358 DEFLineHtr4 "The diesel exhaust fluid line heater 4 request for aftertreatment system 2 (exhaust bank 2). 
 
00 request for heater to be inactive 
01 request for heater to be active 
10 reserved for future assignment by SAE 
11 not available";
CM_ SG_ 2164079358 DEFLineHtr3 "The diesel exhaust fluid line heater 3 request for aftertreatment system 2 (exhaust bank 2). 

00 request for heater to be inactive 
01 request for heater to be active 
10 reserved for future assignment by SAE 
11 not available";
CM_ SG_ 2164079358 DEFLineHtr2 "The diesel exhaust fluid line heater 2 request for aftertreatment system 2 (exhaust bank 2). 

00 request for heater to be inactive 
01 request for heater to be active 
10 reserved for future assignment by SAE 
11 not available";
CM_ SG_ 2164079358 DEFLineHtr1 "The diesel exhaust fluid line heater 1 request for aftertreatment system 2 (exhaust bank 2). 

00 request for heater to be inactive 
01 request for heater to be active 
10 reserved for future assignment by SAE 
11 not available";
CM_ SG_ 2164079358 DEFDoserHeatingModeReq "Used if multiple heater modes are available in the Doser.

000   Heater off
001   Heater economy mode
010   Heater automatic mode
011   Heater on
100 - 110    Reserved
111   Not available";
CM_ SG_ 2164079358 DEFDoserFaultSuppressionReq "Used if external devices can warn of conditions that require suppression of potential faults in the doser due to environmental conditions.

00    Error suppression off
01    Error suppression on
10    Reserved
11    Not available";
CM_ BO_ 2364549118 "Aftertreatment 2 SCR Dosing System Requests 1
This message contains SCR dosing system request information for aftertreatment system 2 (or bank 2).";
CM_ SG_ 2364549118 DEFReqQuantityOfIntegrator "Represents the command for the diesel exhaust fluid quantity integrator in the dosing control unit";
CM_ SG_ 2364549118 DEFDosingReqQuantity6594 "Requested dosing quantity of diesel exhaust fluid. This SPN is a high range measurement. See SPN 4401 if high range is not needed.";
CM_ SG_ 2364549118 DEFPumpHtrCmd "Command for the Aftertreatment 2 Diesel Exhaust Fluid Pump Heater.  A value of 0% means no heating commanded, a value of 100% means full heating commanded.";
CM_ SG_ 2364549118 DEFDosingTestInjPermStatus "After a request to permit the DEF dosing test injection has been indicated, this permission status is expected by the DEF control unit for aftertreatment system 2.
00 = not allowed
01 = DEF dosing test injection allowed
10 = error
11 = not ...";
CM_ SG_ 2364549118 DEFHydStiffnessCheckPermStatus "After a request to permit the DEF hydraulic stiffness check has been indicated, this permission status is expected by the DEF control unit for aftertreatment system 2.
00 = not allowed
01 = DEF hydraulic stiffness check allowed
10 = error
11 = ...";
CM_ SG_ 2364549118 SysReqSt "Requested state of SCR system for aftertreatment system 2 (exhaust bank 2).
0000 Dormant (sleep mode)
0001 Preparing dosing readiness (wake up; prepare to operate; wait for start)
0010 Normal dosing operation
0011 System error pending
0100 ...";
CM_ SG_ 2364549118 DEFDosingReqQuantity "Actual requested dosing quantity of diesel exhaust fluid.";
CM_ BO_ 2566732798 "Aftertreatment 2 SCR Dosing System Information 2
This message contains SCR dosing system information for aftertreatment system 2 (or bank 2).  See PGN 61478 for more information.";
CM_ SG_ 2566732798 DEFLineHtr4PreliminaryFMI "Used to identify the applicable J1939-73 FMI detected in the diesel exhaust fluid line heater 4, by the manufacturer's control software in exhaust bank 2. When there is no failure FMI 31 is sent. In the case of multiple failures the most severe is ...";
CM_ SG_ 2566732798 DEFLineHtr4St "The diesel exhaust fluid line heater 4 state for aftertreatment system 2 (exhaust bank 2).

00 heater inactive 
01 heater active 
10 error 
11 not available";
CM_ SG_ 2566732798 DEFLineHtr3PreliminaryFMI "Used to identify the applicable J1939-73 FMI detected in the diesel exhaust fluid line heater 3, by the manufacturer's control software in exhaust bank 2. When there is no failure FMI 31 is sent. In the case of multiple failures the most severe is ...";
CM_ SG_ 2566732798 DEFLineHtr3St "The diesel exhaust fluid line heater 3 state for aftertreatment system 2 (exhaust bank 2).

00 heater inactive 
01 heater active 
10 error 
11 not available";
CM_ SG_ 2566732798 DEFLineHtr2PreliminaryFMI "Used to identify the applicable J1939-73 FMI detected in the diesel exhaust fluid line heater 2, by the manufacturer's control software in exhaust bank 2. When there is no failure FMI 31 is sent. In the case of multiple failures the most severe is ...";
CM_ SG_ 2566732798 DEFLineHtr2St "The diesel exhaust fluid line heater 2 state for aftertreatment system 2 (exhaust bank 2).

00 heater inactive 
01 heater active 
10 error 
11 not available";
CM_ SG_ 2566732798 DEFLineHtr1PreliminaryFMI "Used to identify the applicable J1939-73 FMI detected in the diesel exhaust fluid line heater 1, by the manufacturer's control software in exhaust bank 2. When there is no failure FMI 31 is sent. In the case of multiple failures the most severe is ...";
CM_ SG_ 2566732798 DEFLineHtr1St "The diesel exhaust fluid line heater 1 state for aftertreatment system 2 (exhaust bank 2).

00 heater inactive 
01 heater active 
10 error 
11 not available";
CM_ SG_ 2566732798 FeedbackCtrlStatus "The SCR feedback control status (open/closed loop) for aftertreatment system 2 (exhaust bank 2).
000 open loop control active
001 closed loop control active
010 reserved for future assignment by SAE
011 reserved for future assignment by SAE
100 ...";
CM_ SG_ 2566732798 VlvExhTempReductionReq "Protection request for the dosing valve of the SCR-system to prevent overheating
000:    no request
001:    reduction request stage 1
010:    reduction request stage 2
011:    reserved for future assignment by SAE
100:    reserved for future ...";
CM_ SG_ 2566732798 DEFDoser1Temp "The temperature (measured closest to dosing valve) of the first or only DEF doser for aftertreatment system 2 (exhaust bank 2).";
CM_ SG_ 2566732798 AirAssistVlv "The position of the valve used to regulate the air supply of an air assist SCR dosing system for an engine. 0% represents no supply and 100% is full supply.";
CM_ SG_ 2566732798 AirAssistAbsPress "The SCR dosing system air assist absolute pressure for aftertreatment system 2 (exhaust bank 2).  The air assist system is used to improve the dosed reagent atomization.";
CM_ BO_ 2364548862 "Aftertreatment 2 SCR Dosing System Information 1
This message contains SCR dosing system information for aftertreatment system 2 (or bank 2).  See PGN 64827 for more information.";
CM_ SG_ 2364548862 DEFActualDosingQuantity6596 "Actual dosing quantity of diesel exhaust fluid. See SPN 4384 if high range measurement is not needed.";
CM_ SG_ 2364548862 Sys2St "Actual state of SCR system 2
0000 = Dormant (sleep mode)
0001 = Preparing dosing readiness (wake up; prepare to operate; wait for start)
0010 = Normal dosing operation
0011 = System error pending
0100 = Purging (SCR dosing system is removing ...";
CM_ SG_ 2364548862 DEFDoser1AbsPress "The absolute pressure (measured closest to dosing valve) of the first or only DEF doser for aftertreatment system 2 (exhaust bank 2).";
CM_ SG_ 2364548862 DEFActualQuantityOfIntegrator "The SCR requested diesel exhaust fluid integrator total quantity for aftertreatment system 2 (exhaust bank 2).";
CM_ SG_ 2364548862 Sys1St "Actual state of SCR system 1.
0000    Dormant (sleep mode)
0001    Preparing dosing readiness (wake up; prepare to operate; wait for start)
0010    Normal dosing operation
0011    System error pending
0100    Purging (SCR dosing system is ...";
CM_ SG_ 2364548862 DEFActualDosingQuantity "Actual reducing agent quantity of SCR system.";
CM_ BO_ 2364549374 "Aftertreatment 2 SCR Ammonia Information
This message contains outlet ammonia information for aftertreatment system 2 (or bank 2).";
CM_ SG_ 2364549374 OutNH3GasSnsrHtrCtrl "Indicates the heater status in the warm-up process. Upon receiving a power-up command, the NH3 gas sensor ramps up according to a manufacturer defined profile. The Preheat 1, Preheat 2, and Automatic messages are regions within this profile in ...";
CM_ SG_ 2364549374 OutNH3GasSnsrHtrPreliminaryFMI "Used to identify the applicable J1939-73 FMI detected in the heater of the outlet NH3 exhaust gas sensor by the manufacturer's sensor control software in exhaust bank 2. When there is no failure FMI 31 is sent. In the case of multiple failures the ...";
CM_ SG_ 2364549374 OutNH3GasSnsrAtTemp "Indicates that the heater element of the aftertreatment outlet NH3 gas sensor is within the manufacturer's specified range for accurate measurements in exhaust bank 2.
00 - Heater element is not in range
01 - Heater element is in range
10 - Error
 ...";
CM_ SG_ 2364549374 OutNH3GasSnsrPwrInRange "Indicates that the power supplied to the aftertreatment outlet NH3 gas sensor is within the manufacturer's specification in exhaust bank 2.

00 - Heater element is not in range
01 - Heater element is in range
10 - Error
11 - Not available";
CM_ SG_ 2364549374 OutNH3ReadingStable "Indicates that the NH3 reading of the aftertreatment outlet NH3 sensor is stable as determined by the manufacturer's control software in exhaust bank 2.

00 - Reading is not stable
01 - Reading is stable
10 - Error
11 - Not available";
CM_ SG_ 2364549374 OutNH3SnsrPreliminaryFMI "Used to identify the applicable J1939-73 FMI detected in the aftertreatment outlet NH3 sensor by the manufacturer's sensor control software in exhaust bank 2. When there is no failure FMI 31 is sent. In the case of multiple failures the most severe ...";
CM_ SG_ 2364549374 OutNH3 "The amount of NH3 in the exhaust exiting the aftertreatment system measured by a NH3 sensor at the aftertreatment outlet, represented in NH3 molecule parts per million non-NH3 molecules in exhaust bank 2.";
CM_ BO_ 2566726142 "Aftertreatment 2 Gas Oxidation Catalyst
The purpose of this PGN is to group the aftertreatment gas oxidation catalyst data for bank 2. These values include the intake temperature, outlet temperature and differential pressure as well as the ...";
CM_ SG_ 2566726142 DiffPressPreliminaryFMI "Used to identify the applicable J1939-73 FMI detected in the gas oxidation catalyst differential pressure sensor by the manufacturer's sensor control software in exhaust bank 2. When there is no failure FMI 31 is sent. In the case of multiple ...";
CM_ SG_ 2566726142 OutTempPreliminaryFMI "Used to identify the applicable J1939-73 FMI detected in the gas oxidation catalyst outlet gas temperature sensor by the manufacturer's sensor control software in exhaust bank 2. When there is no failure FMI 31 is sent. In the case of multiple ...";
CM_ SG_ 2566726142 InTempPreliminaryFMI "Used to identify the applicable J1939-73 FMI detected in the gas oxidation catalyst intake gas temperature sensor by the manufacturer's sensor control software in exhaust bank 2. When there is no failure FMI 31 is sent. In the case of multiple ...";
CM_ SG_ 2566726142 DiffPress "Exhaust differential pressure measured between the intake and exhaust of the gas oxidation catalyst in exhaust bank 2.  This parameter should be used with engines fueled by gaseous fuel like natural gas or propane.  A separate parameter has been ...";
CM_ SG_ 2566726142 OutTemp "Temperature of engine combustion byproducts leaving the gas oxidation catalyst in exhaust bank 2.  This parameter should be used with engines fueled by gaseous fuel like natural gas or propane.  A separate parameter has been defined for diesel ...";
CM_ SG_ 2566726142 InTemp "Temperature of engine combustion byproducts entering the gas oxidation catalyst in exhaust bank 2.  This parameter should be used with engines fueled by gaseous fuel like natural gas or propane.  A separate parameter has been defined for diesel ...";
CM_ BO_ 2566725630 "Aftertreatment 2 Diesel Oxidation Catalyst
The purpose of this PGN is to group the aftertreatment diesel oxidation catalyst data for bank 2. These values include the intake temperature, outlet temperature and differential pressure as well as the ...";
CM_ SG_ 2566725630 DiffPressPreliminaryFMI "Used to identify the applicable J1939-73 FMI detected in the diesel oxidation catalyst differential pressure sensor by the manufacturer's sensor control software in exhaust bank 2. When there is no failure FMI 31 is sent. In the case of multiple ...";
CM_ SG_ 2566725630 OutTempPreliminaryFMI "Used to identify the applicable J1939-73 FMI detected in the diesel oxidation catalyst outlet gas temperature sensor by the manufacturer's sensor control software in exhaust bank 2. When there is no failure FMI 31 is sent. In the case of multiple ...";
CM_ SG_ 2566725630 InTempPreliminaryFMI "Used to identify the applicable J1939-73 FMI detected in the diesel oxidation catalyst intake temperature sensor by the manufacturer's sensor control software in exhaust bank 2. When there is no failure FMI 31 is sent. In the case of multiple ...";
CM_ SG_ 2566725630 DiffPress "Exhaust differential pressure measured between the intake and exhaust of a diesel oxidation catalyst in exhaust bank 2.  This parameter should be used with engines fueled by diesel fuel (not gaseous fuel like natural gas or propane).  A separate ...";
CM_ SG_ 2566725630 OutTemp "Temperature of engine combustion byproducts leaving the diesel oxidation catalyst exhaust in exhaust bank 2.  This parameter should be used with engines fueled by diesel fuel (not gaseous fuel like natural gas or propane).  A separate parameter has ...";
CM_ SG_ 2566725630 InTemp "Temperature of engine combustion byproducts entering the diesel oxidation catalyst in exhaust bank 2.  This parameter should be used with engines fueled by diesel fuel (not gaseous fuel like natural gas or propane).  A separate parameter has been ...";
CM_ BO_ 2566733310 "Aftertreatment 1 SCR Reagant Tank 2 Information
This message contains SCR reagent tank 2 information for aftertreatment system 1 (or bank 1).  The second tank for the aftertreatment system is usually a smaller quick-thaw reagent tank located in ...";
CM_ SG_ 2566733310 DEFQuickThawHtrPreliminaryFMI "Used to identify the applicable J1939-73 FMI detected for the heater of the diesel exhaust fluid quick thaw tank for aftertreatment system 1 (exhaust bank 1), as detected by the manufacturer's control software.  When there is no failure, FMI 31 is ...";
CM_ SG_ 2566733310 DEFQuickThawHtr "The diesel exhaust fluid quick thaw tank heater percentage for aftertreatment system 1 (exhaust bank 1). 0% is off. See SPN 5414 for the command for this tank heater.";
CM_ SG_ 2566733310 DEFQuickThawTempPreliminaryFMI "Used to identify the applicable J1939-73 FMI detected for the diesel exhaust fluid quick thaw tank temperature for aftertreatment system 1 (exhaust bank 1), as detected by the manufacturer's control software. When there is no failure, FMI 31 is ...";
CM_ SG_ 2566733310 DEFQuickThawLvlVolPreliminaryFMI "Used to identify the applicable J1939-73 FMI detected for the fluid level height of the diesel exhaust fluid quick thaw tank for aftertreatment system 1 (exhaust bank 1), as detected by the manufacturer's control software.  This FMI is applicable to ...";
CM_ SG_ 2566733310 DEFQuickThawTankLvl "The diesel exhaust fluid level height in mm in the diesel exhaust fluid quick thaw tank for aftertreatment system 1 (exhaust bank 1). See SPN 4367 for alternate measurement.
Parameter Specific Indicator:
A value of 0xFB indicates conditions are ...";
CM_ SG_ 2566733310 DEFQuickThawTemp "The diesel exhaust fluid quick thaw tank temperature for aftertreatment system 1 (exhaust bank 1).";
CM_ SG_ 2566733310 DEFQuickThawTankVolume "Ratio of volume of diesel exhaust fluid to the total volume of the diesel exhaust fluid quick thaw tank for aftertreatment system 1 (exhaust bank 1).  0% is empty and 100% is full.  See SPN 4369 for an alternate measurement.
Parameter Specific ...";
CM_ BO_ 2566733054 "Aftertreatment 1 Diesel Exhaust Fluid Supply Information
This message contains diesel exhaust fluid supply information for aftertreatment system 1 (or bank 1).";
CM_ SG_ 2566733054 DosingUnit2DiverterVlv "Command to the valve which determines whether the diesel exhaust fluid on dosing unit 2 is delivered to the injector or is routed back to the diesel exhaust fluid tank. Zero directs all diesel exhaust fluid flow to the injector, 100% sends all ...";
CM_ SG_ 2566733054 Pump "State of the aftertreatment 1 Diesel Exhaust Fluid dosing pump.  Indicates if the pump is currently active (pumping).
00 off
01 on
10 error
11 not available
The aftertreatment 1 Diesel Exhaust Fluid dosing pump is a device that delivers a ...";
CM_ SG_ 2566733054 PumpPwrRelay "The state of the aftertreatment 1 diesel exhaust fluid pump power relay.

00 not active - no power is being applied to the relay
01 active - power is being applied to the relay
10 error
11 not available";
CM_ SG_ 2566733054 TankDrainVlvCmd "Commanded percentage of maximum Aftertreatment 1 Diesel Exhaust Fluid Tank Drain Valve opening. 100% means the drain valve is fully open providing maximum flow of diesel exhaust fluid out of the diesel exhaust fluid tank.";
CM_ SG_ 2566733054 PumpSt "State of the aftertreatment 1 Diesel Exhaust Fluid dosing pump.  Indicates whether or not the pump is operational.

00  pump operational
01  pump error
10  reserved for SAE assignment
11 not available";
CM_ SG_ 2566733054 TankFillVlvCmd "Commanded percentage of maximum Aftertreatment 1 Diesel Exhaust Fluid Tank Fill Valve opening. 100% means the fill valve is fully open providing maximum flow of diesel exhaust fluid into the diesel exhaust fluid tank.";
CM_ SG_ 2566733054 DosingUnit1DiverterVlv "Command to the valve which determines whether the diesel exhaust fluid on dosing unit 1 is delivered to the injector or is routed back to the diesel exhaust fluid tank. Zero directs all diesel exhaust fluid flow to the injector, 100% sends all ...";
CM_ SG_ 2566733054 PumpDrivePercentage "The percent (command) sent to the motor to control the speed of the diesel exhaust fluid pump.";
CM_ SG_ 2566733054 Pump1MotorSpd "Rotational speed of the motor driving the first or only pump for the diesel exhaust fluid used in aftertreatment system 1 (exhaust bank 1).";
CM_ BO_ 2499624702 "Aftertreatment 1 SCR Exhaust Gas Temperature 1
This message contains SCR catalyst intake and outlet exhaust gas temperature information for aftertreatment system 1 (or bank 1).";
CM_ SG_ 2499624702 OutTempPreliminaryFMI "Used to identify the applicable J1939-73 FMI detected in the SCR outlet temperature sensor by the manufacturer's sensor control software in exhaust bank 1. When there is no failure FMI 31 is sent. In the case of multiple failures the most severe is ...";
CM_ SG_ 2499624702 OutTemp "Temperature of engine combustion byproducts leaving the SCR outlet in exhaust bank 1.";
CM_ SG_ 2499624702 InTempPreliminaryFMI "Used to identify the applicable J1939-73 FMI detected in the SCR intake temperature sensor by the manufacturer's sensor control software in exhaust bank 1. When there is no failure FMI 31 is sent. In the case of multiple failures the most severe is ...";
CM_ SG_ 2499624702 InTemp "Temperature of engine combustion byproducts entering the SCR in exhaust bank 1.";
CM_ BO_ 2566733822 "Aftertreatment 1 SCR Exhaust Gas Pressures
This message contains SCR catalyst exhaust gas pressure information for aftertreatment system 1 (or bank 1).";
CM_ SG_ 2566733822 InAbsPress "Used to read the pressure at the catalyst intake of the selective catalytic reduction system of aftertreatment 1.";
CM_ SG_ 2566733822 InPress "The gage pressure at the intake of the selective catalytic reduction system of Aftertreatment 1.";
CM_ SG_ 2566733822 DiffPressPreliminaryFMI "Used to identify the applicable J1939-73 FMI detected in the SCR differential pressure sensor by the manufacturer's sensor control software in exhaust bank 1. When there is no failure FMI 31 is sent. In the case of multiple failures the most severe ...";
CM_ SG_ 2566733822 DiffPress "Differential pressure measured between the intake and outlet of an SCR component in exhaust bank 1.";
CM_ BO_ 2566734078 "Aftertreatment 1 SCR Dosing System Requests 2
This message contains SCR dosing system request information for aftertreatment system 1 (or bank 1).  See PGN 61476 for more information.";
CM_ SG_ 2566734078 DEFLineHtr10 "The diesel exhaust fluid line heater 10 request for aftertreatment system 1 (exhaust bank 1).

00 = request for heater to be inactive
01 = request for heater to be active
10 = reserved for future assignment by SAE
11 = not available";
CM_ SG_ 2566734078 DEFLineHtr9 "The diesel exhaust fluid line heater 9 request for aftertreatment system 1 (exhaust bank 1).

00 = request for heater to be inactive
01 = request for heater to be active
10 = reserved for future assignment by SAE
11 = not available";
CM_ SG_ 2566734078 DEFLineHtr8 "The diesel exhaust fluid line heater 8 request for aftertreatment system 1 (exhaust bank 1).

00 = request for heater to be inactive
01 = request for heater to be active
10 = reserved for future assignment by SAE
11 = not available";
CM_ SG_ 2566734078 DEFLineHtr7 "The diesel exhaust fluid line heater 7 request for aftertreatment system 1 (exhaust bank 1).

00 = request for heater to be inactive
01 = request for heater to be active
10 = reserved for future assignment by SAE
11 = not available";
CM_ SG_ 2566734078 DEFLineHtr6 "The diesel exhaust fluid line heater 6 request for aftertreatment system 1 (exhaust bank 1).

00 = request for heater to be inactive
01 = request for heater to be active
10 = reserved for future assignment by SAE
11 = not available";
CM_ SG_ 2566734078 DEFLineHtr5 "The diesel exhaust fluid line heater 5 request for aftertreatment system 1 (exhaust bank 1).

00 = request for heater to be inactive
01 = request for heater to be active
10 = reserved for future assignment by SAE
11 = not available";
CM_ SG_ 2566734078 DEFLineHtrRelay3 "The aftertreatment diesel exhaust fluid line heater relay 3 is used to energize one or more DEF line heaters.

00 - Off
01 - On
10 - Error
11 - Not available";
CM_ SG_ 2566734078 DEFLineHtrRelay2 "The Aftertreatment Diesel Exhaust Fluid Line Heater Relay 2 is used to energize one or more DEF line heaters.

00 - Off
01 - On
10 - Error
11 - Not available";
CM_ SG_ 2566734078 DEFLineHtrRelay1 "The Aftertreatment Diesel Exhaust Fluid Line Heater Relay 1 is used to energize one or more DEF line heaters.

00 - Off
01 - On
10 - Error
11 - Not available";
CM_ SG_ 2566734078 DEFPumpHtrCmd "Command for the Aftertreatment 1 Diesel Exhaust Fluid Pump Heater. A value of 0% means no heating commanded, a value of 100% means full heating commanded. See SPN 5706 for the measured value of the Aftertreatment 1 Diesel Exhaust Fluid Heater.";
CM_ SG_ 2566734078 DEFQuickThawHtrCmd "The command for the heater of the diesel exhaust fluid quick thaw tank for aftertreatment system 1 (exhaust bank 1).  See SPN 4372 for the measured heater percentage for the heater of this same tank.";
CM_ SG_ 2566734078 DEFTankHtrCmd "Command for the Aftertreatment 1 Diesel Exhaust Fluid Tank Heater.  A value of 0% means no heating applied, a value of 100% means full heating applied.  See SPN 3363 for the measured value of the Aftertreatment 1 Diesel Exhaust Fluid Tank Heater.";
CM_ SG_ 2566734078 DEFLineHtr4 "The diesel exhaust fluid line heater 4 request for aftertreatment system 1 (exhaust bank 1).
 
00 request for heater to be inactive 
01 request for heater to be active 
10 reserved for future assignment by SAE 
11 not available";
CM_ SG_ 2566734078 DEFLineHtr3 "The diesel exhaust fluid line heater 3 request for aftertreatment system 1 (exhaust bank 1).
 
00 request for heater to be inactive 
01 request for heater to be active 
10 reserved for future assignment by SAE 
11 not available";
CM_ SG_ 2566734078 DEFLineHtr2 "The diesel exhaust fluid line heater 2 request for aftertreatment system 1 (exhaust bank 1).
 
00 request for heater to be inactive 
01 request for heater to be active 
10 reserved for future assignment by SAE 
11 not available";
CM_ SG_ 2566734078 DEFLineHtr1 "The diesel exhaust fluid line heater 1 request for aftertreatment system 1 (exhaust bank 1).
 
00 request for heater to be inactive 
01 request for heater to be active 
10 reserved for future assignment by SAE 
11 not available";
CM_ SG_ 2566734078 DEFDoserHeatingModeReq "Used if multiple heater modes are available in the Doser.

000   Heater off
001   Heater economy mode
010   Heater automatic mode
011   Heater on
100 - 110    Reserved
111   Not available";
CM_ SG_ 2566734078 DEFDoserFaultSuppressionReq "Used if external devices can warn of conditions that require suppression of potential faults in the doser due to environmental conditions.

00    Error suppression off
01    Error suppression on
10    Reserved
11    Not available";
CM_ BO_ 2364548350 "Aftertreatment 1 SCR Dosing System Requests 1
This message contains SCR dosing system request information for aftertreatment system 1 (or bank 1).  See PGN 64832 for more information.";
CM_ SG_ 2364548350 DEFDosingReqQuantity6593 "Requested dosing quantity of diesel exhaust fluid. This SPN is a high range measurement. See SPN 4348 if high range is not needed.";
CM_ SG_ 2364548350 DEFDosingTestInjPermStatus "After a request to permit the DEF dosing test injection has been indicated, this permission status is expected by the DEF control unit for aftertreatment system 1.
00 = not allowed
01 = DEF dosing test injection allowed
10 = error
11 = not ...";
CM_ SG_ 2364548350 DEFHydStiffnessCheckPermStatus "After a request to permit the DEF hydraulic stiffness check has been indicated, this permission status is expected by the DEF control unit for aftertreatment system 1.
00 = not allowed
01 = DEF hydraulic stiffness check allowed
10 = error
11 = ...";
CM_ SG_ 2364548350 DEFReqQuantityOfIntegrator "Represents the command for the diesel exhaust fluid quantity integrator in the dosing control unit";
CM_ SG_ 2364548350 SysReqSt "Requested state of SCR system for aftertreatment system 1 (exhaust bank 1).
0000 Dormant (sleep mode)
0001 Preparing dosing readiness (wake up; prepare to operate; wait for start)
0010 Normal dosing operation
0011 System error pending
0100 ...";
CM_ SG_ 2364548350 DEFDosingReqQuantity "Actual requested dosing quantity of diesel exhaust fluid.";
CM_ BO_ 2566734334 "Aftertreatment 1 SCR Dosing System Information 2
This message contains SCR dosing system information for aftertreatment system 1 (or bank 1).  See PGN 61475 for more information.";
CM_ SG_ 2566734334 DEFLineHtr4PreliminaryFMI "Used to identify the applicable J1939-73 FMI detected in the diesel exhaust fluid line heater 4, by the manufacturer's control software in exhaust bank 1. When there is no failure FMI 31 is sent. In the case of multiple failures the most severe is ...";
CM_ SG_ 2566734334 DEFLineHtr4St "The diesel exhaust fluid line heater 4 state for aftertreatment system 1 (exhaust bank 1). 

00 heater inactive 
01 heater active 
10 error 
11 not available";
CM_ SG_ 2566734334 DEFLineHtr3PreliminaryFMI "Used to identify the applicable J1939-73 FMI detected in the diesel exhaust fluid line heater 3, by the manufacturer's control software in exhaust bank 1. When there is no failure FMI 31 is sent. In the case of multiple failures the most severe is ...";
CM_ SG_ 2566734334 DEFLineHtr3St "The diesel exhaust fluid line heater 3 state for aftertreatment system 1 (exhaust bank 1). 

00 heater inactive 
01 heater active 
10 error 
11 not available";
CM_ SG_ 2566734334 DEFLineHtr2PreliminaryFMI "Used to identify the applicable J1939-73 FMI detected in the diesel exhaust fluid line heater 2, by the manufacturer's control software in exhaust bank 1. When there is no failure FMI 31 is sent. In the case of multiple failures the most severe is ...";
CM_ SG_ 2566734334 DEFLineHtr2St "The diesel exhaust fluid line heater 2 state for aftertreatment system 1 (exhaust bank 1). 
 
00 heater inactive 
01 heater active 
10 error 
11 not available";
CM_ SG_ 2566734334 DEFLineHtr1PreliminaryFMI "Used to identify the applicable J1939-73 FMI detected in the diesel exhaust fluid line heater 1, by the manufacturer's control software in exhaust bank 1. When there is no failure FMI 31 is sent. In the case of multiple failures the most severe is ...";
CM_ SG_ 2566734334 DEFLineHtr1St "The diesel exhaust fluid line heater 1 state for aftertreatment system 1 (exhaust bank 1). 

00 heater inactive 
01 heater active 
10 error 
11 not available";
CM_ SG_ 2566734334 FeedbackCtrlStatus "The SCR feedback control status (open/closed loop) for aftertreatment system 1 (exhaust bank 1).
000 open loop control active
001 closed loop control active
010 reserved for future assignment by SAE
011 reserved for future assignment by SAE
100 ...";
CM_ SG_ 2566734334 VlvExhTempReductionReq "Protection request for the dosing valve of the SCR-system to prevent overheating
000:    no request
001:    reduction request stage 1
010:    reduction request stage 2
011:    reserved for future assignment by SAE
100:    reserved for future ...";
CM_ SG_ 2566734334 DEFDoser1Temp "The temperature (measured closest to dosing valve) of the first or only DEF dosing unit for aftertreatment system 1 (exhaust bank 1).";
CM_ SG_ 2566734334 AirAssistVlv "The position of the valve used to regulate the air supply of an air assist SCR dosing system for an engine. 0% represents no supply and 100% is full supply.";
CM_ SG_ 2566734334 AirAssistAbsPress "The SCR dosing system air assist absolute pressure for aftertreatment system 1 (exhaust bank 1).  The air assist system is used to improve the dosed reagent atomization.";
CM_ BO_ 2364548094 "Aftertreatment 1 SCR Dosing System Information 1
This message contains SCR dosing system information for aftertreatment system 1 (or bank 1).  See PGN 64833 for more information.";
CM_ SG_ 2364548094 DEFDoser1AbsPress "The absolute pressure (measured closest to dosing valve) of the first or only DEF dosing unit for aftertreatment system 1 (exhaust bank 1).";
CM_ SG_ 2364548094 DEFActualDosingQuantity6595 "Actual dosing quantity of diesel exhaust fluid. See SPN 4331 if high range measurement is not needed.";
CM_ SG_ 2364548094 DEFActualQuantityOfIntegrator "The SCR requested diesel exhaust fluid integrator total quantity for aftertreatment system 1 (exhaust bank 1).";
CM_ SG_ 2364548094 Sys2St "Actual state of SCR system 2
0000 = Dormant (sleep mode)
0001 = Preparing dosing readiness (wake up; prepare to operate; wait for start)
0010 = Normal dosing operation
0011 = System error pending
0100 = Purging (SCR dosing system is removing ...";
CM_ SG_ 2364548094 Sys1St "Actual state of SCR system
0000    Dormant (sleep mode)
0001    Preparing dosing readiness (wake up; prepare to operate; wait for start)
0010    Normal dosing operation
0011    System error pending
0100    Purging (SCR dosing system is removing ...";
CM_ SG_ 2364548094 DEFActualDosingQuantity "Actual reducing agent quantity of SCR-system";
CM_ BO_ 2364548606 "Aftertreatment 1 SCR Ammonia Information
This message contains aftertreatment outlet ammonia information for aftertreatment system 1 (or bank 1).";
CM_ SG_ 2364548606 OutNH3GasSnsrHtrCtrl "Indicates the heater status in the warm-up process. Upon receiving a power-up command, the NH3 gas sensor ramps up according to a manufacturer defined profile. The Preheat 1, Preheat 2, and Automatic messages are regions within this profile in ...";
CM_ SG_ 2364548606 OutNH3GasSnsrHtrPreliminaryFMI "Used to identify the applicable J1939-73 FMI detected in the heater of the outlet NH3 exhaust gas sensor by the manufacturer's sensor control software in exhaust bank 1. When there is no failure FMI 31 is sent. In the case of multiple failures the ...";
CM_ SG_ 2364548606 OutNH3GasSnsrAtTemp "Indicates that the heater element of the aftertreatment outlet NH3 gas sensor is within the manufacturer's specified range for accurate measurements in exhaust bank 1.
00 - Heater element is not in range
01 - Heater element is in range
10 - Error
 ...";
CM_ SG_ 2364548606 OutNH3GasSnsrPwrInRange "Indicates that the power supplied to the aftertreatment outlet NH3 gas sensor is within the manufacturer's specification in exhaust bank 1.

00 - Power is not in range
01 - Power is in range
10 - Error
11 - Not available";
CM_ SG_ 2364548606 OutNH3ReadingStable "Indicates that the NH3 reading of the aftertreatment outlet NH3 sensor is stable as determined by the manufacturer's control software in exhaust bank 1.

00 - Reading is not stable
01 - Reading is stable
10 - Error
11 - Not available";
CM_ SG_ 2364548606 OutNH3SnsrPreliminaryFMI "Used to identify the applicable J1939-73 FMI detected in the aftertreatment outlet NH3 sensor by the manufacturer's sensor control software in exhaust bank 1. When there is no failure FMI 31 is sent. In the case of multiple failures the most severe ...";
CM_ SG_ 2364548606 OutNH3 "The amount of NH3 in the exhaust exiting the aftertreatment system measured by a NH3 sensor at the aftertreatment outlet, represented in NH3 molecule parts per million non-NH3 molecules in exhaust bank 1.";
CM_ BO_ 2566726398 "Aftertreatment 1 Gas Oxidation Catalyst
The purpose of this PGN is to group the aftertreatment gas oxidation catalyst data for bank 1. These values include the intake temperature, outlet temperature and differential pressure as well as the ...";
CM_ SG_ 2566726398 DiffPressPreliminaryFMI "Used to identify the applicable J1939-73 FMI detected in the gas oxidation catalyst differential pressure sensor by the manufacturer's sensor control software in exhaust bank 1. When there is no failure FMI 31 is sent. In the case of multiple ...";
CM_ SG_ 2566726398 OutTempPreliminaryFMI "Used to identify the applicable J1939-73 FMI detected in the gas oxidation catalyst outlet temperature sensor by the manufacturer's sensor control software in exhaust bank 1. When there is no failure FMI 31 is sent. In the case of multiple failures ...";
CM_ SG_ 2566726398 InTempPreliminaryFMI "Used to identify the applicable J1939-73 FMI detected in the gas oxidation catalyst intake temperature sensor by the manufacturer's sensor control software in exhaust bank 1. When there is no failure FMI 31 is sent. In the case of multiple failures ...";
CM_ SG_ 2566726398 DiffPress "Exhaust differential pressure measured between the intake and exhaust of the gas oxidation catalyst in exhaust bank 1.  This parameter should be used with engines fueled by gaseous fuel like natural gas or propane.  A separate parameter has been ...";
CM_ SG_ 2566726398 OutTemp "Temperature of engine combustion byproducts leaving the gas oxidation catalyst in exhaust bank 1.  This parameter should be used with engines fueled by gaseous fuel like natural gas or propane.  A separate parameter has been defined for diesel ...";
CM_ SG_ 2566726398 InTemp "Temperature of engine combustion byproducts entering the gas oxidation catalyst in exhaust bank 1.  This parameter should be used with engines fueled by gaseous fuel like natural gas or propane.  A separate parameter has been defined for diesel ...";
CM_ BO_ 2566742270 "Harmonized B1 Failure Counts (HB1C)
HB1C provides the system specific individual B1 failure counters, when supported by the system.";
CM_ SG_ 2566742270 SPN1 "This 19-bit number is used to identify the item for which diagnostics are being reported.";
CM_ SG_ 2566742270 FailureModeIdentifier1 "The FMI defines the type of failure detected in the subsystem identified by an SPN.";
CM_ SG_ 2566742270 FailureSpecificB1Counter "The Failure Specific B1 Counter provides an individual B1 counter";
CM_ SG_ 2566742270 SPN1High "SPN #1 (Conversion Version 4)";
CM_ BO_ 2566742526 "Cumulative Continuous MI – System (HCMI) 
HCMI provides the system specific cumulative.";
CM_ SG_ 2566742526 SysGreatestB1Counter "System Greatest B1 Counter";
CM_ SG_ 2566742526 SysCumulativeContinuousMITime "System Cumulative Continuous MI Time";
CM_ BO_ 2566742782 "Harmonized Global Regulation Description (HGRD)
HGRD provides a description of the UN/ECE WWH OBD Global Technical Regulation (GTR) to which the sub-system or
component complies.";
CM_ SG_ 2566742782 RegulationDescription "Global Technical Regulation Description";
CM_ BO_ 2566743038 "Harmonized Roadworthiness – System (HRWS)
HRWS reports subsystem (or component) roadworthiness to the VOBD function to aggregate in the HRWV message.";
CM_ SG_ 2566743038 SysIncompleteMonitorCount "System Incomplete Monitor Count";
CM_ SG_ 2566743038 SysMalIndActivationMode "System Malfunction Indicator Status";
CM_ SG_ 2566743038 SysMalIndDisplayStrategy "System Malfunction Indicator Display";
CM_ SG_ 2566743038 SysContinuousMalfunctionInd "System Continuous Malfunction Indicator";
CM_ SG_ 2566743038 SysNonRoadworthyCompCount "System Non-Roadworthy Component Count";
CM_ BO_ 2566743294 "Harmonized Roadworthiness - Vehicle (HRWV)
HRWV provides the aggregated roadworthiness from the VOBD (Vehicle On-Board Diagnostics) to a scan tool or similar inquiry device.";
CM_ SG_ 2566743294 VehicleCurrentMIAccumTime "Vehicle current malfunction indicator accumulated time reports the accumulated count (in minutes) that the malfunction indicator lamp (MIL) is activated (on) for the current malfunction indicator (MI) activation (or the last MI activation).
For US, ...";
CM_ SG_ 2566743294 VehicleIncompleteMonitorCount "Vehicle Incomplete Monitor Count";
CM_ SG_ 2566743294 VehicleMalfunctionIndActMode "Vehicle Malfunction Indicator Status ";
CM_ SG_ 2566743294 VehicleMalfunctionIndStrategy "Vehicle Malfunction Indicator Display Strategy ";
CM_ SG_ 2566743294 VehicleContinuousMalfunctionInd "Vehicle Continuous Malfunction Indicator";
CM_ SG_ 2566743294 VehicleNonRoadworthyCompCount "Vehicle Non-Roadworthy Component Count";
CM_ BO_ 2560687870 "NTE Status
The status of engine operating in the NTE control areas for given pollutants, such as NOx and PM.";
CM_ SG_ 2560687870 PMNTEDeficiencyAreaStatus "Status of engine operation within the PM NTE Deficiency Area.  The PM NTE Deficiency Area is defined as bounded regions or conditions within the NTE control area for PM where the manufacturer has received a deficiency.  If the application does not ...";
CM_ SG_ 2560687870 MnfcPMNTECarveOutAreaStatus "Status of engine operation within the manufacturer specific PM NTE limited testing region.  The manufacturer specific PM NTE  limited testing region is defined as bounded regions within the NTE control area for PM where the manufacturer has limited ...";
CM_ SG_ 2560687870 PMNTEControlAreaStatus "Status of engine operation within the bounded region of the engine's torque and speed map where emissions must not exceed a specific emission cap for PM under the NTE requirement.";
CM_ SG_ 2560687870 NOxNTEDeficiencyAreaStatus "Status of engine operation within the NOx NTE Deficiency Area.  The NOx NTE Deficiency Area is defined as bounded regions or conditions within the NTE control area for NOx where the manufacturer has received a deficiency.  If the application does ...";
CM_ SG_ 2560687870 MnfcNOxNTECarveOutAreaStatus "Status of engine operation within the manufacturer specific NOx NTE limited testing region.  The manufacturer specific NOx NTE limited testing region is defined as bounded regions within the NTE control area for NOx where the manufacturer has ...";
CM_ SG_ 2560687870 NOxNTEControlAreaStatus "Status of engine operation within the bounded region of the engine's torque and speed map where emissions must not exceed a specific emission cap for NOx under the NTE requirement.";
CM_ BO_ 2292317950 "Emission Increasing Auxiliary Emission Control Device Active Time
The total engine run time while each of the Emission Increasing Auxiliary Emission Control Devices (EI-AECDs) is active.";
CM_ SG_ 2292317950 AECDEngineHours1Timer2 "The total engine running hours recorded in the second timer for the EI-AECD";
CM_ SG_ 2292317950 AECDEngineHours1Timer1 "The total engine running hours recorded in the first timer for the EI-AECD";
CM_ SG_ 2292317950 AECDNumber1 "The manufacturer assigned number for the specific EI-AECD";
CM_ BO_ 2566809342 "Battery Main Switch Information";
CM_ SG_ 2566809342 BatteryMainSwitchHoldState "Parameter indicating whether the battery main switch is held due to an external request or not. The state battery main switch held indicates that the battery main switch is about to switch off.
00 Battery main switch not held
01 Battery main ...";
CM_ BO_ 2365446910 "Basic Joystick Message 3
Used to transfer information about the measured status of the 1st 2 axes and up to 12 buttons of a joystick.  Additional handle information is available in the Expanded Joystick Message.
10-bit position parameters are ...";
CM_ SG_ 2365446910 Joystick3XAxisDetentPosStatus "Reports when the current joystick position is in the detent position for that axis of travel.

00 Not in the Detent Position
01 In the Detent Position
10 Error Indicator
11 Not Available";
CM_ SG_ 2365446910 Joystick3Button9PressedStatus "Reports when the joystick button has been pressed.

00 Button not pressed
01 Button pressed
10 Error Indicator
11 Not Available";
CM_ SG_ 2365446910 Joystick3Button10PressedStatus "Reports when the joystick button has been pressed.

00 Button not pressed
01 Button pressed
10 Error Indicator
11 Not Available";
CM_ SG_ 2365446910 Joystick3Button11PressedStatus "Reports when the joystick button has been pressed.

00 Button not pressed
01 Button pressed
10 Error Indicator
11 Not Available";
CM_ SG_ 2365446910 Joystick3Button12PressedStatus "Reports when the joystick button has been pressed.

00 Button not pressed
01 Button pressed
10 Error Indicator
11 Not Available";
CM_ SG_ 2365446910 Joystick3YAxisDetentPosStatus "Reports when the current joystick position is in the detent position for that axis of travel.

00 Not in the Detent Position
01 In the Detent Position
10 Error Indicator
11 Not Available";
CM_ SG_ 2365446910 Joystick3YAxisPos "The position of the joystick in the relative motion of travel from the neutral position.  Position value of 0 is Neutral and position value 1000 (100%) is the end of linear zone.  Value of 1022 indicates an error has occurred.";
CM_ SG_ 2365446910 Jystck3YAxsLvrFrwrdPstvPosStatus "Reports when the current joystick position is on the positive travel side (forward, right, clockwise, up) relative to the neutral position for that axis of travel.
00 Not on Positive side of Neutral
01 On positive side of Neutral
10 Error ...";
CM_ SG_ 2365446910 Jystck3YAxsLvrBckNgtivePosStatus "Reports when the current joystick position is on the negative travel side (back, left, counterclockwise, down) relative to the neutral position for that axis of travel.
00 Not on negative side of Neutral
01 On negative side of Neutral
10 Error ...";
CM_ SG_ 2365446910 Joystick3YAxisNeutralPosStatus "Reports when the current joystick position is in the neutral position for that axis of travel.  The neutral position measurement must be determined from some mechanism other than the axis position measurement device.
00 Not in Neutral Position
01 ...";
CM_ SG_ 2365446910 Joystick3XAxisPos "The position of the joystick in the relative motion of travel from the neutral position.  Position value of 0 is Neutral and position value 1000 (100%) is the end of linear zone.  Value of 1022 indicates an error has occurred.";
CM_ SG_ 2365446910 Jystck3XAxsLvrRghtPstvePosStatus "Reports when the current joystick position is on the positive travel side (forward, right, clockwise, up) relative to the neutral position for that axis of travel.
00 Not on Positive side of Neutral
01 On positive side of Neutral
10 Error ...";
CM_ SG_ 2365446910 Jystck3XAxsLvrLftNgtivePosStatus "Reports when the current joystick position is on the negative travel side (back, left, counterclockwise, down) relative to the neutral position for that axis of travel.
00 Not on negative side of Neutral
01 On negative side of Neutral
10 Error ...";
CM_ SG_ 2365446910 Joystick3XAxisNeutralPosStatus "Reports when the current joystick position is in the neutral position for that axis of travel.  The neutral position measurement must be determined from some mechanism other than the axis position measurement device.
00 Not in Neutral Position
01 ...";
CM_ SG_ 2365446910 Joystick3Button5PressedStatus "Reports when the joystick button has been pressed.

00 Button not pressed
01 Button pressed
10 Error Indicator
11 Not Available";
CM_ SG_ 2365446910 Joystick3Button6PressedStatus "Reports when the joystick button has been pressed.

00 Button not pressed
01 Button pressed
10 Error Indicator
11 Not Available";
CM_ SG_ 2365446910 Joystick3Button7PressedStatus "Reports when the joystick button has been pressed.

00 Button not pressed
01 Button pressed
10 Error Indicator
11 Not Available";
CM_ SG_ 2365446910 Joystick3Button8PressedStatus "Reports when the joystick button has been pressed.

00 Button not pressed
01 Button pressed
10 Error Indicator
11 Not Available";
CM_ SG_ 2365446910 Joystick3Button1PressedStatus "Reports when the joystick button has been pressed.

00 Button not pressed
01 Button pressed
10 Error Indicator
11 Not Available";
CM_ SG_ 2365446910 Joystick3Button2PressedStatus "Reports when the joystick button has been pressed.

00 Button not pressed
01 Button pressed
10 Error Indicator
11 Not Available";
CM_ SG_ 2365446910 Joystick3Button3PressedStatus "Reports when the joystick button has been pressed.

00 Button not pressed
01 Button pressed
10 Error Indicator
11 Not Available";
CM_ SG_ 2365446910 Joystick3Button4PressedStatus "Reports when the joystick button has been pressed.

00 Button not pressed
01 Button pressed
10 Error Indicator
11 Not Available";
BA_DEF_ SG_  "SigType" ENUM  "Default","Range","RangeSigned","ASCII","Discrete","Control","ReferencePGN","DTC","StringDelimiter","StringLength","StringLengthControl","MessageCounter","MessageChecksum";
BA_DEF_ SG_  "GenSigStartValue" INT 0 2147483647;
BA_DEF_ SG_  "GenSigSendType" ENUM  "Cyclic","OnWrite","OnWriteWithRepetition","OnChange","OnChangeWithRepetition","IfActive","IfActiveWithRepetition","NoSigSendType";
BA_DEF_ SG_  "GenSigILSupport" ENUM  "No","Yes";
BA_DEF_ SG_  "GenSigEVName" STRING ;
BA_DEF_ SG_  "SPN" INT 0 524287;
BA_DEF_ BO_  "TpJ1939VarDlc" ENUM  "No","Yes";
BA_DEF_ BO_  "GenMsgCycleTimeFast" INT 0 3600000;
BA_DEF_ BO_  "GenMsgStartDelayTime" INT 0 100000;
BA_DEF_ BO_  "GenMsgILSupport" ENUM  "No","Yes";
BA_DEF_ BO_  "GenMsgDelayTime" INT 0 1000;
BA_DEF_ BO_  "GenMsgRequestable" INT 0 1;
BA_DEF_ BO_  "GenMsgSendType" ENUM  "cyclic","NotUsed","NotUsed","NotUsed","NotUsed","NotUsed","NotUsed","IfActive","noMsgSendType";
BA_DEF_ BO_  "VFrameFormat" ENUM  "StandardCAN","ExtendedCAN","reserved","J1939PG";
BA_DEF_ BO_  "GenMsgCycleTime" INT 0 3600000;
BA_DEF_ BO_  "SendOnChange" ENUM  "No","Yes";
BA_DEF_ SG_  "SystemSignalLongSymbol" STRING ;
BA_DEF_DEF_  "SigType" "Default";
BA_DEF_DEF_  "GenSigStartValue" 0;
BA_DEF_DEF_  "GenSigSendType" "NoSigSendType";
BA_DEF_DEF_  "GenSigILSupport" "Yes";
BA_DEF_DEF_  "GenSigEVName" "Env@Nodename_@Signame";
BA_DEF_DEF_  "SPN" 0;
BA_DEF_DEF_  "TpJ1939VarDlc" "No";
BA_DEF_DEF_  "GenMsgCycleTimeFast" 0;
BA_DEF_DEF_  "GenMsgStartDelayTime" 0;
BA_DEF_DEF_  "GenMsgILSupport" "Yes";
BA_DEF_DEF_  "GenMsgDelayTime" 0;
BA_DEF_DEF_  "GenMsgRequestable" 1;
BA_DEF_DEF_  "GenMsgSendType" "noMsgSendType";
BA_DEF_DEF_  "VFrameFormat" "J1939PG";
BA_DEF_DEF_  "GenMsgCycleTime" 0;
BA_DEF_DEF_  "SendOnChange" "No";
BA_DEF_DEF_  "SystemSignalLongSymbol" "";
BA_ "GenMsgCycleTime" BO_ 2365403390 100;
BA_ "GenMsgSendType" BO_ 2365403390 0;
BA_ "GenMsgDelayTime" BO_ 2365403390 20;
BA_ "GenMsgCycleTime" BO_ 2365400318 100;
BA_ "GenMsgSendType" BO_ 2365400318 0;
BA_ "GenMsgDelayTime" BO_ 2365400318 20;
BA_ "GenMsgCycleTime" BO_ 2499614718 250;
BA_ "GenMsgSendType" BO_ 2499614718 0;
BA_ "GenMsgCycleTime" BO_ 2566722814 1000;
BA_ "GenMsgSendType" BO_ 2566722814 0;
BA_ "GenMsgCycleTime" BO_ 2566723070 1000;
BA_ "GenMsgSendType" BO_ 2566723070 0;
BA_ "GenMsgCycleTime" BO_ 2566712830 500;
BA_ "GenMsgSendType" BO_ 2566712830 0;
BA_ "GenMsgCycleTime" BO_ 2566735358 500;
BA_ "GenMsgSendType" BO_ 2566735358 0;
BA_ "GenMsgCycleTime" BO_ 2365393918 1000;
BA_ "GenMsgSendType" BO_ 2365393918 0;
BA_ "GenMsgCycleTime" BO_ 2365394430 1000;
BA_ "GenMsgSendType" BO_ 2365394430 0;
BA_ "GenMsgCycleTime" BO_ 2566735102 500;
BA_ "GenMsgSendType" BO_ 2566735102 0;
BA_ "GenMsgCycleTime" BO_ 2566724350 500;
BA_ "GenMsgSendType" BO_ 2566724350 0;
BA_ "GenMsgCycleTime" BO_ 2566735614 500;
BA_ "GenMsgSendType" BO_ 2566735614 0;
BA_ "GenMsgCycleTime" BO_ 2566805246 1000;
BA_ "GenMsgSendType" BO_ 2566805246 0;
BA_ "GenMsgCycleTime" BO_ 2365394942 1000;
BA_ "GenMsgSendType" BO_ 2365394942 0;
BA_ "GenMsgCycleTime" BO_ 2365395454 1000;
BA_ "GenMsgSendType" BO_ 2365395454 0;
BA_ "GenMsgCycleTime" BO_ 2566711806 100;
BA_ "GenMsgSendType" BO_ 2566711806 0;
BA_ "GenMsgCycleTime" BO_ 2364549886 10;
BA_ "GenMsgSendType" BO_ 2364549886 0;
BA_ "GenMsgCycleTime" BO_ 2566712318 1000;
BA_ "GenMsgSendType" BO_ 2566712318 0;
BA_ "GenMsgCycleTime" BO_ 2566712574 1000;
BA_ "GenMsgSendType" BO_ 2566712574 0;
BA_ "GenMsgCycleTime" BO_ 2566731006 1000;
BA_ "GenMsgSendType" BO_ 2566731006 0;
BA_ "GenMsgCycleTime" BO_ 2566731262 1000;
BA_ "GenMsgSendType" BO_ 2566731262 0;
BA_ "GenMsgCycleTime" BO_ 2566730750 1000;
BA_ "GenMsgSendType" BO_ 2566730750 0;
BA_ "GenMsgCycleTime" BO_ 2566731518 1000;
BA_ "GenMsgSendType" BO_ 2566731518 0;
BA_ "GenMsgCycleTime" BO_ 2566732030 500;
BA_ "GenMsgSendType" BO_ 2566732030 0;
BA_ "GenMsgCycleTime" BO_ 2566732286 500;
BA_ "GenMsgSendType" BO_ 2566732286 0;
BA_ "GenMsgCycleTime" BO_ 2164079358 500;
BA_ "GenMsgSendType" BO_ 2164079358 0;
BA_ "GenMsgCycleTime" BO_ 2364549118 50;
BA_ "GenMsgSendType" BO_ 2364549118 0;
BA_ "GenMsgCycleTime" BO_ 2566732798 500;
BA_ "GenMsgSendType" BO_ 2566732798 0;
BA_ "GenMsgCycleTime" BO_ 2364548862 50;
BA_ "GenMsgSendType" BO_ 2364548862 0;
BA_ "GenMsgCycleTime" BO_ 2364549374 50;
BA_ "GenMsgSendType" BO_ 2364549374 0;
BA_ "GenMsgCycleTime" BO_ 2566726142 500;
BA_ "GenMsgSendType" BO_ 2566726142 0;
BA_ "GenMsgCycleTime" BO_ 2566725630 500;
BA_ "GenMsgSendType" BO_ 2566725630 0;
BA_ "GenMsgCycleTime" BO_ 2566733310 1000;
BA_ "GenMsgSendType" BO_ 2566733310 0;
BA_ "GenMsgCycleTime" BO_ 2566733054 1000;
BA_ "GenMsgSendType" BO_ 2566733054 0;
BA_ "GenMsgCycleTime" BO_ 2499624702 500;
BA_ "GenMsgSendType" BO_ 2499624702 0;
BA_ "GenMsgCycleTime" BO_ 2566733822 500;
BA_ "GenMsgSendType" BO_ 2566733822 0;
BA_ "GenMsgCycleTime" BO_ 2566734078 500;
BA_ "GenMsgSendType" BO_ 2566734078 0;
BA_ "GenMsgCycleTime" BO_ 2364548350 50;
BA_ "GenMsgSendType" BO_ 2364548350 0;
BA_ "GenMsgCycleTime" BO_ 2566734334 500;
BA_ "GenMsgSendType" BO_ 2566734334 0;
BA_ "GenMsgCycleTime" BO_ 2364548094 50;
BA_ "GenMsgSendType" BO_ 2364548094 0;
BA_ "GenMsgCycleTime" BO_ 2364548606 50;
BA_ "GenMsgSendType" BO_ 2364548606 0;
BA_ "GenMsgCycleTime" BO_ 2566726398 500;
BA_ "GenMsgSendType" BO_ 2566726398 0;
BA_ "TpJ1939VarDlc" BO_ 2566742270 1;
BA_ "TpJ1939VarDlc" BO_ 2566742782 1;
BA_ "TpJ1939VarDlc" BO_ 2560687870 1;
BA_ "TpJ1939VarDlc" BO_ 2292317950 1;
BA_ "GenMsgCycleTime" BO_ 2566809342 1000;
BA_ "GenMsgSendType" BO_ 2566809342 0;
BA_ "GenMsgCycleTime" BO_ 2365446910 100;
BA_ "GenMsgSendType" BO_ 2365446910 0;
BA_ "GenMsgDelayTime" BO_ 2365446910 20;
BA_ "SPN" SG_ 2365403390 Joystick4Button9PressedStatus 4512;
BA_ "SigType" SG_ 2365403390 Joystick4Button9PressedStatus 4;
BA_ "SPN" SG_ 2365403390 Joystick4Button10PressedStatus 4511;
BA_ "SigType" SG_ 2365403390 Joystick4Button10PressedStatus 4;
BA_ "SPN" SG_ 2365403390 Joystick4Button11PressedStatus 4510;
BA_ "SigType" SG_ 2365403390 Joystick4Button11PressedStatus 4;
BA_ "SPN" SG_ 2365403390 Joystick4Button12PressedStatus 4509;
BA_ "SigType" SG_ 2365403390 Joystick4Button12PressedStatus 4;
BA_ "SPN" SG_ 2365403390 Joystick4Button5PressedStatus 4508;
BA_ "SigType" SG_ 2365403390 Joystick4Button5PressedStatus 4;
BA_ "SPN" SG_ 2365403390 Joystick4Button6PressedStatus 4507;
BA_ "SigType" SG_ 2365403390 Joystick4Button6PressedStatus 4;
BA_ "SPN" SG_ 2365403390 Joystick4Button7PressedStatus 4506;
BA_ "SigType" SG_ 2365403390 Joystick4Button7PressedStatus 4;
BA_ "SPN" SG_ 2365403390 Joystick4Button8PressedStatus 4505;
BA_ "SigType" SG_ 2365403390 Joystick4Button8PressedStatus 4;
BA_ "SPN" SG_ 2365403390 Joystick4Button1PressedStatus 4504;
BA_ "SigType" SG_ 2365403390 Joystick4Button1PressedStatus 4;
BA_ "SPN" SG_ 2365403390 Joystick4Button2PressedStatus 4503;
BA_ "SigType" SG_ 2365403390 Joystick4Button2PressedStatus 4;
BA_ "SPN" SG_ 2365403390 Joystick4Button3PressedStatus 4502;
BA_ "SigType" SG_ 2365403390 Joystick4Button3PressedStatus 4;
BA_ "SPN" SG_ 2365403390 Joystick4Button4PressedStatus 4501;
BA_ "SigType" SG_ 2365403390 Joystick4Button4PressedStatus 4;
BA_ "SPN" SG_ 2365403390 Joystick4XAxisDetentPosStatus 4500;
BA_ "SigType" SG_ 2365403390 Joystick4XAxisDetentPosStatus 4;
BA_ "SPN" SG_ 2365403390 Joystick4YAxisDetentPosStatus 4499;
BA_ "SigType" SG_ 2365403390 Joystick4YAxisDetentPosStatus 4;
BA_ "SPN" SG_ 2365403390 Joystick4YAxisPos 4498;
BA_ "SPN" SG_ 2365403390 Jystck4YAxsLvrFrwrdPstvPosStatus 4497;
BA_ "SigType" SG_ 2365403390 Jystck4YAxsLvrFrwrdPstvPosStatus 4;
BA_ "SPN" SG_ 2365403390 Jystck4YAxsLvrBckNgtivePosStatus 4496;
BA_ "SigType" SG_ 2365403390 Jystck4YAxsLvrBckNgtivePosStatus 4;
BA_ "SPN" SG_ 2365403390 Joystick4YAxisNeutralPosStatus 4495;
BA_ "SigType" SG_ 2365403390 Joystick4YAxisNeutralPosStatus 4;
BA_ "SPN" SG_ 2365403390 Joystick4XAxisPos 4494;
BA_ "SPN" SG_ 2365403390 Jystck4XAxsLvrRghtPstvePosStatus 4493;
BA_ "SigType" SG_ 2365403390 Jystck4XAxsLvrRghtPstvePosStatus 4;
BA_ "SPN" SG_ 2365403390 Jystck4XAxsLvrLftNgtivePosStatus 4492;
BA_ "SigType" SG_ 2365403390 Jystck4XAxsLvrLftNgtivePosStatus 4;
BA_ "SPN" SG_ 2365403390 Joystick4XAxisNeutralPosStatus 4491;
BA_ "SigType" SG_ 2365403390 Joystick4XAxisNeutralPosStatus 4;
BA_ "SPN" SG_ 2365400318 Joystick10Button9PressedStatus 4734;
BA_ "SigType" SG_ 2365400318 Joystick10Button9PressedStatus 4;
BA_ "SPN" SG_ 2365400318 Joystick10Button10PressedStatus 4733;
BA_ "SigType" SG_ 2365400318 Joystick10Button10PressedStatus 4;
BA_ "SPN" SG_ 2365400318 Joystick10Button11PressedStatus 4732;
BA_ "SigType" SG_ 2365400318 Joystick10Button11PressedStatus 4;
BA_ "SPN" SG_ 2365400318 Joystick10Button12PressedStatus 4731;
BA_ "SigType" SG_ 2365400318 Joystick10Button12PressedStatus 4;
BA_ "SPN" SG_ 2365400318 Joystick10Button5PressedStatus 4730;
BA_ "SigType" SG_ 2365400318 Joystick10Button5PressedStatus 4;
BA_ "SPN" SG_ 2365400318 Joystick10Button6PressedStatus 4729;
BA_ "SigType" SG_ 2365400318 Joystick10Button6PressedStatus 4;
BA_ "SPN" SG_ 2365400318 Joystick10Button7PressedStatus 4728;
BA_ "SigType" SG_ 2365400318 Joystick10Button7PressedStatus 4;
BA_ "SPN" SG_ 2365400318 Joystick10Button8PressedStatus 4727;
BA_ "SigType" SG_ 2365400318 Joystick10Button8PressedStatus 4;
BA_ "SPN" SG_ 2365400318 Joystick10Button1PressedStatus 4726;
BA_ "SigType" SG_ 2365400318 Joystick10Button1PressedStatus 4;
BA_ "SPN" SG_ 2365400318 Joystick10Button2PressedStatus 4725;
BA_ "SigType" SG_ 2365400318 Joystick10Button2PressedStatus 4;
BA_ "SPN" SG_ 2365400318 Joystick10Button3PressedStatus 4724;
BA_ "SigType" SG_ 2365400318 Joystick10Button3PressedStatus 4;
BA_ "SPN" SG_ 2365400318 Joystick10Button4PressedStatus 4723;
BA_ "SigType" SG_ 2365400318 Joystick10Button4PressedStatus 4;
BA_ "SPN" SG_ 2365400318 Joystick10XAxisDetentPosStatus 4722;
BA_ "SigType" SG_ 2365400318 Joystick10XAxisDetentPosStatus 4;
BA_ "SPN" SG_ 2365400318 Joystick10YAxisDetentPosStatus 4721;
BA_ "SigType" SG_ 2365400318 Joystick10YAxisDetentPosStatus 4;
BA_ "SPN" SG_ 2365400318 Joystick10YAxisPos 4720;
BA_ "SPN" SG_ 2365400318 Jystck10YAxsLvrFrwrdPstvPsStatus 4719;
BA_ "SigType" SG_ 2365400318 Jystck10YAxsLvrFrwrdPstvPsStatus 4;
BA_ "SPN" SG_ 2365400318 Jystck10YAxsLvrBckNgtvePosStatus 4718;
BA_ "SigType" SG_ 2365400318 Jystck10YAxsLvrBckNgtvePosStatus 4;
BA_ "SPN" SG_ 2365400318 Joystick10YAxisNeutralPosStatus 4717;
BA_ "SigType" SG_ 2365400318 Joystick10YAxisNeutralPosStatus 4;
BA_ "SPN" SG_ 2365400318 Joystick10XAxisPos 4716;
BA_ "SPN" SG_ 2365400318 Jystck10XAxsLvrRghtPstvPosStatus 4715;
BA_ "SigType" SG_ 2365400318 Jystck10XAxsLvrRghtPstvPosStatus 4;
BA_ "SPN" SG_ 2365400318 Jystck10XAxsLvrLftNgtvePosStatus 4714;
BA_ "SigType" SG_ 2365400318 Jystck10XAxsLvrLftNgtvePosStatus 4;
BA_ "SPN" SG_ 2365400318 Joystick10XAxisNeutralPosStatus 4713;
BA_ "SigType" SG_ 2365400318 Joystick10XAxisNeutralPosStatus 4;
BA_ "SPN" SG_ 2499614718 PssngrArbgDctivationSwitchStatus 4962;
BA_ "SigType" SG_ 2499614718 PssngrArbgDctivationSwitchStatus 5;
BA_ "SPN" SG_ 2499614718 Beltlock10Status 4961;
BA_ "SigType" SG_ 2499614718 Beltlock10Status 5;
BA_ "SPN" SG_ 2499614718 Beltlock9Status 4960;
BA_ "SigType" SG_ 2499614718 Beltlock9Status 5;
BA_ "SPN" SG_ 2499614718 Beltlock8Status 4959;
BA_ "SigType" SG_ 2499614718 Beltlock8Status 5;
BA_ "SPN" SG_ 2499614718 Beltlock7Status 4958;
BA_ "SigType" SG_ 2499614718 Beltlock7Status 5;
BA_ "SPN" SG_ 2499614718 Beltlock6Status 4957;
BA_ "SigType" SG_ 2499614718 Beltlock6Status 5;
BA_ "SPN" SG_ 2499614718 Beltlock5Status 4956;
BA_ "SigType" SG_ 2499614718 Beltlock5Status 5;
BA_ "SPN" SG_ 2499614718 Beltlock4Status 4955;
BA_ "SigType" SG_ 2499614718 Beltlock4Status 5;
BA_ "SPN" SG_ 2499614718 Beltlock3Status 4954;
BA_ "SigType" SG_ 2499614718 Beltlock3Status 5;
BA_ "SPN" SG_ 2499614718 PassengerBeltlockStatus 4953;
BA_ "SigType" SG_ 2499614718 PassengerBeltlockStatus 5;
BA_ "SPN" SG_ 2499614718 DriverBeltlockStatus 4952;
BA_ "SigType" SG_ 2499614718 DriverBeltlockStatus 5;
BA_ "SPN" SG_ 2566722814 BatteryCharger2OutputCurrent 4997;
BA_ "SigType" SG_ 2566722814 BatteryCharger2OutputCurrent 1;
BA_ "SPN" SG_ 2566722814 BatteryCharger2OutputVoltage 4996;
BA_ "SigType" SG_ 2566722814 BatteryCharger2OutputVoltage 1;
BA_ "SPN" SG_ 2566722814 BatteryCharger2PowerLineState 4995;
BA_ "SigType" SG_ 2566722814 BatteryCharger2PowerLineState 4;
BA_ "SPN" SG_ 2566722814 BatteryCharger2State 4994;
BA_ "SPN" SG_ 2566723070 BatteryCharger1OutputCurrent 4993;
BA_ "SigType" SG_ 2566723070 BatteryCharger1OutputCurrent 1;
BA_ "SPN" SG_ 2566723070 BatteryCharger1OutputVoltage 4992;
BA_ "SigType" SG_ 2566723070 BatteryCharger1OutputVoltage 1;
BA_ "SPN" SG_ 2566723070 BatteryCharger1PowerLineState 4991;
BA_ "SigType" SG_ 2566723070 BatteryCharger1PowerLineState 4;
BA_ "SPN" SG_ 2566723070 BatteryCharger1State 4990;
BA_ "SPN" SG_ 2566725118 TwoTWCDiffTemp 4780;
BA_ "SigType" SG_ 2566725118 TwoTWCDiffTemp 1;
BA_ "SPN" SG_ 2566725118 OneTWCDiffTemp 4779;
BA_ "SigType" SG_ 2566725118 OneTWCDiffTemp 1;
BA_ "SPN" SG_ 2566725374 TwoGOCDiffTemp 4778;
BA_ "SigType" SG_ 2566725374 TwoGOCDiffTemp 1;
BA_ "SPN" SG_ 2566725374 OneGOCDiffTemp 4777;
BA_ "SigType" SG_ 2566725374 OneGOCDiffTemp 1;
BA_ "SPN" SG_ 2566712830 OutTemp 5316;
BA_ "SigType" SG_ 2566712830 OutTemp 1;
BA_ "SPN" SG_ 2566712830 InTemp 5315;
BA_ "SigType" SG_ 2566712830 InTemp 1;
BA_ "SPN" SG_ 2566735358 DiffPressPreliminaryFMI 4300;
BA_ "SPN" SG_ 2566735358 OutTempPreliminaryFMI 4299;
BA_ "SPN" SG_ 2566735358 InTempPreliminaryFMI 4298;
BA_ "SPN" SG_ 2566735358 DiffPress 4297;
BA_ "SigType" SG_ 2566735358 DiffPress 1;
BA_ "SPN" SG_ 2566735358 OutTemp 4296;
BA_ "SigType" SG_ 2566735358 OutTemp 1;
BA_ "SPN" SG_ 2566735358 InTemp 4295;
BA_ "SigType" SG_ 2566735358 InTemp 1;
BA_ "SPN" SG_ 2365393662 CorrectedNOx 7352;
BA_ "SigType" SG_ 2365393662 CorrectedNOx 1;
BA_ "SPN" SG_ 2365393662 NOxSnsrSelfDiagFinalResult 5719;
BA_ "SigType" SG_ 2365393662 NOxSnsrSelfDiagFinalResult 1;
BA_ "SPN" SG_ 2365393662 NOxSnsrNH3Correction 5051;
BA_ "SigType" SG_ 2365393662 NOxSnsrNH3Correction 1;
BA_ "SPN" SG_ 2365393662 NOxSnsrNO2Correction 5050;
BA_ "SigType" SG_ 2365393662 NOxSnsrNO2Correction 1;
BA_ "SPN" SG_ 2365393662 NOxSnsrNOxPressCorrection 5049;
BA_ "SigType" SG_ 2365393662 NOxSnsrNOxPressCorrection 1;
BA_ "SPN" SG_ 2365393662 NOxSnsrO2PressCorrection 5048;
BA_ "SigType" SG_ 2365393662 NOxSnsrO2PressCorrection 1;
BA_ "SPN" SG_ 2365393918 NOxSnsrOpHours 5723;
BA_ "SigType" SG_ 2365393918 NOxSnsrOpHours 1;
BA_ "SPN" SG_ 2365393918 NOxSnsrNewPartDeviationNOxOffset 5047;
BA_ "SigType" SG_ 2365393918 NOxSnsrNewPartDeviationNOxOffset 1;
BA_ "SPN" SG_ 2365393918 NOxSnsrNewPartDeviationNOxGain 5046;
BA_ "SigType" SG_ 2365393918 NOxSnsrNewPartDeviationNOxGain 1;
BA_ "SPN" SG_ 2365393918 NOxSnsrHtrRatio 5045;
BA_ "SigType" SG_ 2365393918 NOxSnsrHtrRatio 1;
BA_ "SPN" SG_ 2365394174 SCRInCorrectedNOx 7354;
BA_ "SigType" SG_ 2365394174 SCRInCorrectedNOx 1;
BA_ "SPN" SG_ 2365394174 NOxSnsrSelfDiagFinalResult 5720;
BA_ "SigType" SG_ 2365394174 NOxSnsrSelfDiagFinalResult 1;
BA_ "SPN" SG_ 2365394174 NOxSnsrNH3Correction 5044;
BA_ "SigType" SG_ 2365394174 NOxSnsrNH3Correction 1;
BA_ "SPN" SG_ 2365394174 NOxSnsrNO2Correction 5043;
BA_ "SigType" SG_ 2365394174 NOxSnsrNO2Correction 1;
BA_ "SPN" SG_ 2365394174 NOxSnsrNOxPressCorrection 5042;
BA_ "SigType" SG_ 2365394174 NOxSnsrNOxPressCorrection 1;
BA_ "SPN" SG_ 2365394174 NOxSnsrO2PressCorrection 5041;
BA_ "SigType" SG_ 2365394174 NOxSnsrO2PressCorrection 1;
BA_ "SPN" SG_ 2365394430 NOxSnsrOpHours 5724;
BA_ "SigType" SG_ 2365394430 NOxSnsrOpHours 1;
BA_ "SPN" SG_ 2365394430 NOxSnsrNewPartDeviationNOxOffset 5040;
BA_ "SigType" SG_ 2365394430 NOxSnsrNewPartDeviationNOxOffset 1;
BA_ "SPN" SG_ 2365394430 NOxSnsrNewPartDeviationNOxGain 5039;
BA_ "SigType" SG_ 2365394430 NOxSnsrNewPartDeviationNOxGain 1;
BA_ "SPN" SG_ 2365394430 NOxSnsrHtrRatio 5038;
BA_ "SigType" SG_ 2365394430 NOxSnsrHtrRatio 1;
BA_ "SPN" SG_ 2566735102 Press2Ctrl 5428;
BA_ "SigType" SG_ 2566735102 Press2Ctrl 1;
BA_ "SPN" SG_ 2566735102 FlowDiverterVlvCtrl 5427;
BA_ "SigType" SG_ 2566735102 FlowDiverterVlvCtrl 5;
BA_ "SPN" SG_ 2566735102 PumpRelayCtrl 5426;
BA_ "SigType" SG_ 2566735102 PumpRelayCtrl 5;
BA_ "SPN" SG_ 2566735102 Press2 4303;
BA_ "SigType" SG_ 2566735102 Press2 1;
BA_ "SPN" SG_ 2157313790 StdDeviationCalOffset 5498;
BA_ "SigType" SG_ 2157313790 StdDeviationCalOffset 1;
BA_ "SPN" SG_ 2157313790 MeanCalOffset 5497;
BA_ "SigType" SG_ 2157313790 MeanCalOffset 1;
BA_ "SPN" SG_ 2566724350 OutTemp 4810;
BA_ "SigType" SG_ 2566724350 OutTemp 1;
BA_ "SPN" SG_ 2566724350 InTemp 4809;
BA_ "SigType" SG_ 2566724350 InTemp 1;
BA_ "SPN" SG_ 2566735614 DiffPressPreliminaryFMI 4294;
BA_ "SPN" SG_ 2566735614 OutTempPreliminaryFMI 4293;
BA_ "SPN" SG_ 2566735614 InTempPreliminaryFMI 4292;
BA_ "SPN" SG_ 2566735614 DiffPress 4291;
BA_ "SigType" SG_ 2566735614 DiffPress 1;
BA_ "SPN" SG_ 2566735614 OutTemp 4290;
BA_ "SigType" SG_ 2566735614 OutTemp 1;
BA_ "SPN" SG_ 2566735614 InTemp 4289;
BA_ "SigType" SG_ 2566735614 InTemp 1;
BA_ "SPN" SG_ 2566805246 HtrPreliminaryFMI 4366;
BA_ "SPN" SG_ 2566805246 Htr 3363;
BA_ "SigType" SG_ 2566805246 Htr 1;
BA_ "SPN" SG_ 2566805246 SCROpIndSev 5246;
BA_ "SPN" SG_ 2566805246 TempPreliminaryFMI 4365;
BA_ "SPN" SG_ 2566805246 DEFTankLowLvlInd 5245;
BA_ "SPN" SG_ 2566805246 LvlVolPreliminaryFMI 3532;
BA_ "SPN" SG_ 2566805246 Lvl 3517;
BA_ "SigType" SG_ 2566805246 Lvl 1;
BA_ "SPN" SG_ 2566805246 Temp1 3031;
BA_ "SigType" SG_ 2566805246 Temp1 1;
BA_ "SPN" SG_ 2566805246 Volume 1761;
BA_ "SigType" SG_ 2566805246 Volume 1;
BA_ "SPN" SG_ 2365394686 CorrectedNOx 7351;
BA_ "SigType" SG_ 2365394686 CorrectedNOx 1;
BA_ "SPN" SG_ 2365394686 NOxSnsrSelfDiagFinalResult 5717;
BA_ "SigType" SG_ 2365394686 NOxSnsrSelfDiagFinalResult 1;
BA_ "SPN" SG_ 2365394686 NOxSnsrNH3Correction 5037;
BA_ "SigType" SG_ 2365394686 NOxSnsrNH3Correction 1;
BA_ "SPN" SG_ 2365394686 NOxSnsrNO2Correction 5036;
BA_ "SigType" SG_ 2365394686 NOxSnsrNO2Correction 1;
BA_ "SPN" SG_ 2365394686 NOxSnsrNOxPressCorrection 5035;
BA_ "SigType" SG_ 2365394686 NOxSnsrNOxPressCorrection 1;
BA_ "SPN" SG_ 2365394686 NOxSnsrO2PressCorrection 5034;
BA_ "SigType" SG_ 2365394686 NOxSnsrO2PressCorrection 1;
BA_ "SPN" SG_ 2365394942 NOxSnsrOpHours 5721;
BA_ "SigType" SG_ 2365394942 NOxSnsrOpHours 1;
BA_ "SPN" SG_ 2365394942 NOxSnsrNewPartDeviationNOxOffset 5033;
BA_ "SigType" SG_ 2365394942 NOxSnsrNewPartDeviationNOxOffset 1;
BA_ "SPN" SG_ 2365394942 NOxSnsrNewPartDeviationNOxGain 5032;
BA_ "SigType" SG_ 2365394942 NOxSnsrNewPartDeviationNOxGain 1;
BA_ "SPN" SG_ 2365394942 NOxSnsrHtrRatio 5031;
BA_ "SigType" SG_ 2365394942 NOxSnsrHtrRatio 1;
BA_ "SPN" SG_ 2365395198 SCRInCorrectedNOx 7353;
BA_ "SigType" SG_ 2365395198 SCRInCorrectedNOx 1;
BA_ "SPN" SG_ 2365395198 NOxSnsrSelfDiagFinalResult 5718;
BA_ "SigType" SG_ 2365395198 NOxSnsrSelfDiagFinalResult 1;
BA_ "SPN" SG_ 2365395198 NOxSnsrNH3Correction 5030;
BA_ "SigType" SG_ 2365395198 NOxSnsrNH3Correction 1;
BA_ "SPN" SG_ 2365395198 NOxSnsrNO2Correction 5029;
BA_ "SigType" SG_ 2365395198 NOxSnsrNO2Correction 1;
BA_ "SPN" SG_ 2365395198 NOxSnsrNOxPressCorrection 5028;
BA_ "SigType" SG_ 2365395198 NOxSnsrNOxPressCorrection 1;
BA_ "SPN" SG_ 2365395198 NOxSnsrO2PressCorrection 5027;
BA_ "SigType" SG_ 2365395198 NOxSnsrO2PressCorrection 1;
BA_ "SPN" SG_ 2365395454 NOxSnsrOpHours 5722;
BA_ "SigType" SG_ 2365395454 NOxSnsrOpHours 1;
BA_ "SPN" SG_ 2365395454 NOxSnsrNewPartDeviationNOxOffset 5026;
BA_ "SigType" SG_ 2365395454 NOxSnsrNewPartDeviationNOxOffset 1;
BA_ "SPN" SG_ 2365395454 NOxSnsrNewPartDeviationNOxGain 5025;
BA_ "SigType" SG_ 2365395454 NOxSnsrNewPartDeviationNOxGain 1;
BA_ "SPN" SG_ 2365395454 NOxSnsrHtrRatio 5024;
BA_ "SigType" SG_ 2365395454 NOxSnsrHtrRatio 1;
BA_ "SPN" SG_ 2157248254 StdDeviationCalOffset 5496;
BA_ "SigType" SG_ 2157248254 StdDeviationCalOffset 1;
BA_ "SPN" SG_ 2157248254 MeanCalOffset 5495;
BA_ "SigType" SG_ 2157248254 MeanCalOffset 1;
BA_ "SPN" SG_ 2566711806 Armrest2Switch2 5494;
BA_ "SigType" SG_ 2566711806 Armrest2Switch2 5;
BA_ "SPN" SG_ 2566711806 Armrest2Switch1 5493;
BA_ "SigType" SG_ 2566711806 Armrest2Switch1 5;
BA_ "SPN" SG_ 2566711806 Armrest1Switch2 5492;
BA_ "SigType" SG_ 2566711806 Armrest1Switch2 5;
BA_ "SPN" SG_ 2566711806 Armrest1Switch1 1503;
BA_ "SigType" SG_ 2566711806 Armrest1Switch1 5;
BA_ "SPN" SG_ 2364549886 AngularRateMeasurementLatency 4989;
BA_ "SigType" SG_ 2364549886 AngularRateMeasurementLatency 1;
BA_ "SPN" SG_ 2364549886 YawRateExRangeFigureOfMerit 4988;
BA_ "SigType" SG_ 2364549886 YawRateExRangeFigureOfMerit 5;
BA_ "SPN" SG_ 2364549886 RollRateExRangeFigureOfMerit 4987;
BA_ "SigType" SG_ 2364549886 RollRateExRangeFigureOfMerit 5;
BA_ "SPN" SG_ 2364549886 PitchRateExRangeFigureOfMerit 4986;
BA_ "SigType" SG_ 2364549886 PitchRateExRangeFigureOfMerit 5;
BA_ "SPN" SG_ 2364549886 YawRateExRange 4985;
BA_ "SigType" SG_ 2364549886 YawRateExRange 1;
BA_ "SPN" SG_ 2364549886 RollRateExRange 4984;
BA_ "SigType" SG_ 2364549886 RollRateExRange 1;
BA_ "SPN" SG_ 2364549886 PitchRateExRange 4983;
BA_ "SigType" SG_ 2364549886 PitchRateExRange 1;
BA_ "SPN" SG_ 2566712318 DesulfationStatus 5462;
BA_ "SigType" SG_ 2566712318 DesulfationStatus 5;
BA_ "SPN" SG_ 2566712318 RegenStatus 5460;
BA_ "SigType" SG_ 2566712318 RegenStatus 5;
BA_ "SPN" SG_ 2566712574 DesulfationStatus 5461;
BA_ "SigType" SG_ 2566712574 DesulfationStatus 5;
BA_ "SPN" SG_ 2566712574 RegenStatus 5459;
BA_ "SigType" SG_ 2566712574 RegenStatus 5;
BA_ "SPN" SG_ 2164078590 ConversionEfficiency 4419;
BA_ "SigType" SG_ 2164078590 ConversionEfficiency 1;
BA_ "SPN" SG_ 2164078590 CommandedDEFConsumption 4418;
BA_ "SigType" SG_ 2164078590 CommandedDEFConsumption 1;
BA_ "SPN" SG_ 2164078590 DEFAvgConsumption 4417;
BA_ "SigType" SG_ 2164078590 DEFAvgConsumption 1;
BA_ "SPN" SG_ 2566731006 DEFQuickThawHtrPreliminaryFMI 4439;
BA_ "SPN" SG_ 2566731006 DEFQuickThawHtr 4438;
BA_ "SigType" SG_ 2566731006 DEFQuickThawHtr 1;
BA_ "SPN" SG_ 2566731006 DEFQuickThawTempPreliminaryFMI 4437;
BA_ "SPN" SG_ 2566731006 DEFQuickThawLvlPreliminaryFMI 4436;
BA_ "SPN" SG_ 2566731006 DEFQuickThawTankLvl 4435;
BA_ "SigType" SG_ 2566731006 DEFQuickThawTankLvl 1;
BA_ "SPN" SG_ 2566731006 DEFQuickThawTemp 4434;
BA_ "SigType" SG_ 2566731006 DEFQuickThawTemp 1;
BA_ "SPN" SG_ 2566731006 DEFQuickThawTankVolume 4433;
BA_ "SigType" SG_ 2566731006 DEFQuickThawTankVolume 1;
BA_ "SPN" SG_ 2566731262 HtrPreliminaryFMI 4432;
BA_ "SPN" SG_ 2566731262 Htr 4431;
BA_ "SigType" SG_ 2566731262 Htr 1;
BA_ "SPN" SG_ 2566731262 TempPreliminaryFMI 4430;
BA_ "SPN" SG_ 2566731262 LvlVolPreliminaryFMI 4429;
BA_ "SPN" SG_ 2566731262 Lvl 4428;
BA_ "SigType" SG_ 2566731262 Lvl 1;
BA_ "SPN" SG_ 2566731262 Temp1 4427;
BA_ "SigType" SG_ 2566731262 Temp1 1;
BA_ "SPN" SG_ 2566731262 Volume 4426;
BA_ "SigType" SG_ 2566731262 Volume 1;
BA_ "SPN" SG_ 2566730750 DosingUnit2DiverterVlv 7537;
BA_ "SigType" SG_ 2566730750 DosingUnit2DiverterVlv 1;
BA_ "SPN" SG_ 2566730750 TankDrainVlvCmd 5439;
BA_ "SigType" SG_ 2566730750 TankDrainVlvCmd 1;
BA_ "SPN" SG_ 2566730750 PumpSt 5438;
BA_ "SigType" SG_ 2566730750 PumpSt 5;
BA_ "SPN" SG_ 2566730750 TankFillVlvCmd 5437;
BA_ "SigType" SG_ 2566730750 TankFillVlvCmd 1;
BA_ "SPN" SG_ 2566730750 DosingUnit1DiverterVlv 4442;
BA_ "SigType" SG_ 2566730750 DosingUnit1DiverterVlv 1;
BA_ "SPN" SG_ 2566730750 PumpDrivePercentage 4441;
BA_ "SigType" SG_ 2566730750 PumpDrivePercentage 1;
BA_ "SPN" SG_ 2566730750 Pump1MotorSpd 4440;
BA_ "SigType" SG_ 2566730750 Pump1MotorSpd 1;
BA_ "SPN" SG_ 2566731518 TypeProperty 4425;
BA_ "SPN" SG_ 2566731518 PropertiesPreliminaryFMI 4424;
BA_ "SPN" SG_ 2566731518 Temp2PreliminaryFMI 4423;
BA_ "SPN" SG_ 2566731518 Conductivity 4422;
BA_ "SigType" SG_ 2566731518 Conductivity 1;
BA_ "SPN" SG_ 2566731518 Concentration 4421;
BA_ "SigType" SG_ 2566731518 Concentration 1;
BA_ "SPN" SG_ 2566731518 Temp2 4420;
BA_ "SigType" SG_ 2566731518 Temp2 1;
BA_ "SPN" SG_ 2566732030 OutTempPreliminaryFMI 4416;
BA_ "SPN" SG_ 2566732030 OutTemp 4415;
BA_ "SigType" SG_ 2566732030 OutTemp 1;
BA_ "SPN" SG_ 2566732030 InTempPreliminaryFMI 4414;
BA_ "SPN" SG_ 2566732030 InTemp 4413;
BA_ "SigType" SG_ 2566732030 InTemp 1;
BA_ "SPN" SG_ 2566732286 InAbsPress 6798;
BA_ "SigType" SG_ 2566732286 InAbsPress 1;
BA_ "SPN" SG_ 2566732286 InPress 6587;
BA_ "SigType" SG_ 2566732286 InPress 1;
BA_ "SPN" SG_ 2566732286 DiffPressPreliminaryFMI 4412;
BA_ "SPN" SG_ 2566732286 DiffPress 4411;
BA_ "SigType" SG_ 2566732286 DiffPress 1;
BA_ "SPN" SG_ 2164079358 DEFLineHtr10 7571;
BA_ "SigType" SG_ 2164079358 DEFLineHtr10 5;
BA_ "SPN" SG_ 2164079358 DEFLineHtr9 7570;
BA_ "SigType" SG_ 2164079358 DEFLineHtr9 5;
BA_ "SPN" SG_ 2164079358 DEFLineHtr8 7569;
BA_ "SigType" SG_ 2164079358 DEFLineHtr8 5;
BA_ "SPN" SG_ 2164079358 DEFLineHtr7 7568;
BA_ "SigType" SG_ 2164079358 DEFLineHtr7 5;
BA_ "SPN" SG_ 2164079358 DEFLineHtr6 7567;
BA_ "SigType" SG_ 2164079358 DEFLineHtr6 5;
BA_ "SPN" SG_ 2164079358 DEFLineHtr5 5490;
BA_ "SigType" SG_ 2164079358 DEFLineHtr5 4;
BA_ "SPN" SG_ 2164079358 DEFLineHtrRelay3 7527;
BA_ "SigType" SG_ 2164079358 DEFLineHtrRelay3 5;
BA_ "SPN" SG_ 2164079358 DEFLineHtrRelay2 7526;
BA_ "SigType" SG_ 2164079358 DEFLineHtrRelay2 5;
BA_ "SPN" SG_ 2164079358 DEFLineHtrRelay1 5973;
BA_ "SigType" SG_ 2164079358 DEFLineHtrRelay1 5;
BA_ "SPN" SG_ 2164079358 DEFQuickThawHtrCmd 5415;
BA_ "SigType" SG_ 2164079358 DEFQuickThawHtrCmd 1;
BA_ "SPN" SG_ 2164079358 DEFTankHtrCmd 5138;
BA_ "SigType" SG_ 2164079358 DEFTankHtrCmd 1;
BA_ "SPN" SG_ 2164079358 DEFLineHtr4 4410;
BA_ "SigType" SG_ 2164079358 DEFLineHtr4 5;
BA_ "SPN" SG_ 2164079358 DEFLineHtr3 4409;
BA_ "SigType" SG_ 2164079358 DEFLineHtr3 5;
BA_ "SPN" SG_ 2164079358 DEFLineHtr2 4408;
BA_ "SigType" SG_ 2164079358 DEFLineHtr2 5;
BA_ "SPN" SG_ 2164079358 DEFLineHtr1 4407;
BA_ "SigType" SG_ 2164079358 DEFLineHtr1 5;
BA_ "SPN" SG_ 2164079358 DEFDoserHeatingModeReq 4406;
BA_ "SPN" SG_ 2164079358 DEFDoserFaultSuppressionReq 4405;
BA_ "SigType" SG_ 2164079358 DEFDoserFaultSuppressionReq 5;
BA_ "SPN" SG_ 2364549118 DEFReqQuantityOfIntegrator 4403;
BA_ "SigType" SG_ 2364549118 DEFReqQuantityOfIntegrator 1;
BA_ "SPN" SG_ 2364549118 DEFDosingReqQuantity6594 6594;
BA_ "SigType" SG_ 2364549118 DEFDosingReqQuantity6594 1;
BA_ "SPN" SG_ 2364549118 DEFPumpHtrCmd 7087;
BA_ "SigType" SG_ 2364549118 DEFPumpHtrCmd 1;
BA_ "SPN" SG_ 2364549118 DEFDosingTestInjPermStatus 7520;
BA_ "SigType" SG_ 2364549118 DEFDosingTestInjPermStatus 5;
BA_ "SPN" SG_ 2364549118 DEFHydStiffnessCheckPermStatus 7519;
BA_ "SigType" SG_ 2364549118 DEFHydStiffnessCheckPermStatus 5;
BA_ "SPN" SG_ 2364549118 SysReqSt 4402;
BA_ "SPN" SG_ 2364549118 DEFDosingReqQuantity 4401;
BA_ "SigType" SG_ 2364549118 DEFDosingReqQuantity 1;
BA_ "SPN" SG_ 2566732798 DEFLineHtr4PreliminaryFMI 4400;
BA_ "SPN" SG_ 2566732798 DEFLineHtr4St 4399;
BA_ "SigType" SG_ 2566732798 DEFLineHtr4St 5;
BA_ "SPN" SG_ 2566732798 DEFLineHtr3PreliminaryFMI 4398;
BA_ "SPN" SG_ 2566732798 DEFLineHtr3St 4397;
BA_ "SigType" SG_ 2566732798 DEFLineHtr3St 5;
BA_ "SPN" SG_ 2566732798 DEFLineHtr2PreliminaryFMI 4396;
BA_ "SPN" SG_ 2566732798 DEFLineHtr2St 4395;
BA_ "SigType" SG_ 2566732798 DEFLineHtr2St 5;
BA_ "SPN" SG_ 2566732798 DEFLineHtr1PreliminaryFMI 4394;
BA_ "SPN" SG_ 2566732798 DEFLineHtr1St 4393;
BA_ "SigType" SG_ 2566732798 DEFLineHtr1St 5;
BA_ "SPN" SG_ 2566732798 FeedbackCtrlStatus 4392;
BA_ "SPN" SG_ 2566732798 VlvExhTempReductionReq 4391;
BA_ "SPN" SG_ 2566732798 DEFDoser1Temp 4390;
BA_ "SigType" SG_ 2566732798 DEFDoser1Temp 1;
BA_ "SPN" SG_ 2566732798 AirAssistVlv 4389;
BA_ "SigType" SG_ 2566732798 AirAssistVlv 1;
BA_ "SPN" SG_ 2566732798 AirAssistAbsPress 4388;
BA_ "SigType" SG_ 2566732798 AirAssistAbsPress 1;
BA_ "SPN" SG_ 2364548862 DEFActualDosingQuantity6596 6596;
BA_ "SigType" SG_ 2364548862 DEFActualDosingQuantity6596 1;
BA_ "SPN" SG_ 2364548862 Sys2St 7525;
BA_ "SPN" SG_ 2364548862 DEFDoser1AbsPress 4387;
BA_ "SigType" SG_ 2364548862 DEFDoser1AbsPress 1;
BA_ "SPN" SG_ 2364548862 DEFActualQuantityOfIntegrator 4386;
BA_ "SigType" SG_ 2364548862 DEFActualQuantityOfIntegrator 1;
BA_ "SPN" SG_ 2364548862 Sys1St 4385;
BA_ "SPN" SG_ 2364548862 DEFActualDosingQuantity 4384;
BA_ "SigType" SG_ 2364548862 DEFActualDosingQuantity 1;
BA_ "SPN" SG_ 2364549374 OutNH3GasSnsrHtrCtrl 4449;
BA_ "SigType" SG_ 2364549374 OutNH3GasSnsrHtrCtrl 5;
BA_ "SPN" SG_ 2364549374 OutNH3GasSnsrHtrPreliminaryFMI 4448;
BA_ "SPN" SG_ 2364549374 OutNH3GasSnsrAtTemp 4447;
BA_ "SigType" SG_ 2364549374 OutNH3GasSnsrAtTemp 5;
BA_ "SPN" SG_ 2364549374 OutNH3GasSnsrPwrInRange 4446;
BA_ "SigType" SG_ 2364549374 OutNH3GasSnsrPwrInRange 5;
BA_ "SPN" SG_ 2364549374 OutNH3ReadingStable 4445;
BA_ "SigType" SG_ 2364549374 OutNH3ReadingStable 5;
BA_ "SPN" SG_ 2364549374 OutNH3SnsrPreliminaryFMI 4444;
BA_ "SPN" SG_ 2364549374 OutNH3 4443;
BA_ "SigType" SG_ 2364549374 OutNH3 1;
BA_ "SPN" SG_ 2566726142 DiffPressPreliminaryFMI 4764;
BA_ "SPN" SG_ 2566726142 OutTempPreliminaryFMI 4763;
BA_ "SPN" SG_ 2566726142 InTempPreliminaryFMI 4762;
BA_ "SPN" SG_ 2566726142 DiffPress 4761;
BA_ "SigType" SG_ 2566726142 DiffPress 1;
BA_ "SPN" SG_ 2566726142 OutTemp 4760;
BA_ "SigType" SG_ 2566726142 OutTemp 1;
BA_ "SPN" SG_ 2566726142 InTemp 4759;
BA_ "SigType" SG_ 2566726142 InTemp 1;
BA_ "SPN" SG_ 2566725630 DiffPressPreliminaryFMI 4776;
BA_ "SPN" SG_ 2566725630 OutTempPreliminaryFMI 4775;
BA_ "SPN" SG_ 2566725630 InTempPreliminaryFMI 4774;
BA_ "SPN" SG_ 2566725630 DiffPress 4773;
BA_ "SigType" SG_ 2566725630 DiffPress 1;
BA_ "SPN" SG_ 2566725630 OutTemp 4772;
BA_ "SigType" SG_ 2566725630 OutTemp 1;
BA_ "SPN" SG_ 2566725630 InTemp 4771;
BA_ "SigType" SG_ 2566725630 InTemp 1;
BA_ "SPN" SG_ 2566733310 DEFQuickThawHtrPreliminaryFMI 4373;
BA_ "SPN" SG_ 2566733310 DEFQuickThawHtr 4372;
BA_ "SigType" SG_ 2566733310 DEFQuickThawHtr 1;
BA_ "SPN" SG_ 2566733310 DEFQuickThawTempPreliminaryFMI 4371;
BA_ "SPN" SG_ 2566733310 DEFQuickThawLvlVolPreliminaryFMI 4370;
BA_ "SPN" SG_ 2566733310 DEFQuickThawTankLvl 4369;
BA_ "SigType" SG_ 2566733310 DEFQuickThawTankLvl 1;
BA_ "SPN" SG_ 2566733310 DEFQuickThawTemp 4368;
BA_ "SigType" SG_ 2566733310 DEFQuickThawTemp 1;
BA_ "SPN" SG_ 2566733310 DEFQuickThawTankVolume 4367;
BA_ "SigType" SG_ 2566733310 DEFQuickThawTankVolume 1;
BA_ "SPN" SG_ 2566733054 DosingUnit2DiverterVlv 7536;
BA_ "SigType" SG_ 2566733054 DosingUnit2DiverterVlv 1;
BA_ "SPN" SG_ 2566733054 Pump 7107;
BA_ "SigType" SG_ 2566733054 Pump 4;
BA_ "SPN" SG_ 2566733054 PumpPwrRelay 7416;
BA_ "SigType" SG_ 2566733054 PumpPwrRelay 4;
BA_ "SPN" SG_ 2566733054 TankDrainVlvCmd 5436;
BA_ "SigType" SG_ 2566733054 TankDrainVlvCmd 1;
BA_ "SPN" SG_ 2566733054 PumpSt 5435;
BA_ "SigType" SG_ 2566733054 PumpSt 5;
BA_ "SPN" SG_ 2566733054 TankFillVlvCmd 5434;
BA_ "SigType" SG_ 2566733054 TankFillVlvCmd 1;
BA_ "SPN" SG_ 2566733054 DosingUnit1DiverterVlv 4376;
BA_ "SigType" SG_ 2566733054 DosingUnit1DiverterVlv 1;
BA_ "SPN" SG_ 2566733054 PumpDrivePercentage 4375;
BA_ "SigType" SG_ 2566733054 PumpDrivePercentage 1;
BA_ "SPN" SG_ 2566733054 Pump1MotorSpd 4374;
BA_ "SigType" SG_ 2566733054 Pump1MotorSpd 1;
BA_ "SPN" SG_ 2499624702 OutTempPreliminaryFMI 4362;
BA_ "SPN" SG_ 2499624702 OutTemp 4363;
BA_ "SigType" SG_ 2499624702 OutTemp 1;
BA_ "SPN" SG_ 2499624702 InTempPreliminaryFMI 4361;
BA_ "SPN" SG_ 2499624702 InTemp 4360;
BA_ "SigType" SG_ 2499624702 InTemp 1;
BA_ "SPN" SG_ 2566733822 InAbsPress 6797;
BA_ "SigType" SG_ 2566733822 InAbsPress 1;
BA_ "SPN" SG_ 2566733822 InPress 6586;
BA_ "SigType" SG_ 2566733822 InPress 1;
BA_ "SPN" SG_ 2566733822 DiffPressPreliminaryFMI 4359;
BA_ "SPN" SG_ 2566733822 DiffPress 4358;
BA_ "SigType" SG_ 2566733822 DiffPress 1;
BA_ "SPN" SG_ 2566734078 DEFLineHtr10 7566;
BA_ "SigType" SG_ 2566734078 DEFLineHtr10 5;
BA_ "SPN" SG_ 2566734078 DEFLineHtr9 7565;
BA_ "SigType" SG_ 2566734078 DEFLineHtr9 5;
BA_ "SPN" SG_ 2566734078 DEFLineHtr8 7564;
BA_ "SigType" SG_ 2566734078 DEFLineHtr8 5;
BA_ "SPN" SG_ 2566734078 DEFLineHtr7 7563;
BA_ "SigType" SG_ 2566734078 DEFLineHtr7 5;
BA_ "SPN" SG_ 2566734078 DEFLineHtr6 7562;
BA_ "SigType" SG_ 2566734078 DEFLineHtr6 5;
BA_ "SPN" SG_ 2566734078 DEFLineHtr5 7561;
BA_ "SigType" SG_ 2566734078 DEFLineHtr5 5;
BA_ "SPN" SG_ 2566734078 DEFLineHtrRelay3 7540;
BA_ "SigType" SG_ 2566734078 DEFLineHtrRelay3 5;
BA_ "SPN" SG_ 2566734078 DEFLineHtrRelay2 7069;
BA_ "SigType" SG_ 2566734078 DEFLineHtrRelay2 4;
BA_ "SPN" SG_ 2566734078 DEFLineHtrRelay1 5491;
BA_ "SigType" SG_ 2566734078 DEFLineHtrRelay1 4;
BA_ "SPN" SG_ 2566734078 DEFPumpHtrCmd 5707;
BA_ "SigType" SG_ 2566734078 DEFPumpHtrCmd 1;
BA_ "SPN" SG_ 2566734078 DEFQuickThawHtrCmd 5414;
BA_ "SigType" SG_ 2566734078 DEFQuickThawHtrCmd 1;
BA_ "SPN" SG_ 2566734078 DEFTankHtrCmd 5137;
BA_ "SigType" SG_ 2566734078 DEFTankHtrCmd 1;
BA_ "SPN" SG_ 2566734078 DEFLineHtr4 4357;
BA_ "SigType" SG_ 2566734078 DEFLineHtr4 5;
BA_ "SPN" SG_ 2566734078 DEFLineHtr3 4356;
BA_ "SigType" SG_ 2566734078 DEFLineHtr3 5;
BA_ "SPN" SG_ 2566734078 DEFLineHtr2 4355;
BA_ "SigType" SG_ 2566734078 DEFLineHtr2 5;
BA_ "SPN" SG_ 2566734078 DEFLineHtr1 4354;
BA_ "SigType" SG_ 2566734078 DEFLineHtr1 5;
BA_ "SPN" SG_ 2566734078 DEFDoserHeatingModeReq 4353;
BA_ "SPN" SG_ 2566734078 DEFDoserFaultSuppressionReq 4352;
BA_ "SigType" SG_ 2566734078 DEFDoserFaultSuppressionReq 5;
BA_ "SPN" SG_ 2364548350 DEFDosingReqQuantity6593 6593;
BA_ "SigType" SG_ 2364548350 DEFDosingReqQuantity6593 1;
BA_ "SPN" SG_ 2364548350 DEFDosingTestInjPermStatus 7518;
BA_ "SigType" SG_ 2364548350 DEFDosingTestInjPermStatus 5;
BA_ "SPN" SG_ 2364548350 DEFHydStiffnessCheckPermStatus 7517;
BA_ "SigType" SG_ 2364548350 DEFHydStiffnessCheckPermStatus 5;
BA_ "SPN" SG_ 2364548350 DEFReqQuantityOfIntegrator 4350;
BA_ "SigType" SG_ 2364548350 DEFReqQuantityOfIntegrator 1;
BA_ "SPN" SG_ 2364548350 SysReqSt 4349;
BA_ "SPN" SG_ 2364548350 DEFDosingReqQuantity 4348;
BA_ "SigType" SG_ 2364548350 DEFDosingReqQuantity 1;
BA_ "SPN" SG_ 2566734334 DEFLineHtr4PreliminaryFMI 4347;
BA_ "SPN" SG_ 2566734334 DEFLineHtr4St 4346;
BA_ "SigType" SG_ 2566734334 DEFLineHtr4St 5;
BA_ "SPN" SG_ 2566734334 DEFLineHtr3PreliminaryFMI 4345;
BA_ "SPN" SG_ 2566734334 DEFLineHtr3St 4344;
BA_ "SigType" SG_ 2566734334 DEFLineHtr3St 5;
BA_ "SPN" SG_ 2566734334 DEFLineHtr2PreliminaryFMI 4343;
BA_ "SPN" SG_ 2566734334 DEFLineHtr2St 4342;
BA_ "SigType" SG_ 2566734334 DEFLineHtr2St 5;
BA_ "SPN" SG_ 2566734334 DEFLineHtr1PreliminaryFMI 4341;
BA_ "SPN" SG_ 2566734334 DEFLineHtr1St 4340;
BA_ "SigType" SG_ 2566734334 DEFLineHtr1St 5;
BA_ "SPN" SG_ 2566734334 FeedbackCtrlStatus 4339;
BA_ "SPN" SG_ 2566734334 VlvExhTempReductionReq 4338;
BA_ "SPN" SG_ 2566734334 DEFDoser1Temp 4337;
BA_ "SigType" SG_ 2566734334 DEFDoser1Temp 1;
BA_ "SPN" SG_ 2566734334 AirAssistVlv 4336;
BA_ "SigType" SG_ 2566734334 AirAssistVlv 1;
BA_ "SPN" SG_ 2566734334 AirAssistAbsPress 4335;
BA_ "SigType" SG_ 2566734334 AirAssistAbsPress 1;
BA_ "SPN" SG_ 2364548094 DEFDoser1AbsPress 4334;
BA_ "SigType" SG_ 2364548094 DEFDoser1AbsPress 1;
BA_ "SPN" SG_ 2364548094 DEFActualDosingQuantity6595 6595;
BA_ "SigType" SG_ 2364548094 DEFActualDosingQuantity6595 1;
BA_ "SPN" SG_ 2364548094 DEFActualQuantityOfIntegrator 4333;
BA_ "SigType" SG_ 2364548094 DEFActualQuantityOfIntegrator 1;
BA_ "SPN" SG_ 2364548094 Sys2St 7524;
BA_ "SPN" SG_ 2364548094 Sys1St 4332;
BA_ "SPN" SG_ 2364548094 DEFActualDosingQuantity 4331;
BA_ "SigType" SG_ 2364548094 DEFActualDosingQuantity 1;
BA_ "SPN" SG_ 2364548606 OutNH3GasSnsrHtrCtrl 4383;
BA_ "SigType" SG_ 2364548606 OutNH3GasSnsrHtrCtrl 5;
BA_ "SPN" SG_ 2364548606 OutNH3GasSnsrHtrPreliminaryFMI 4382;
BA_ "SPN" SG_ 2364548606 OutNH3GasSnsrAtTemp 4381;
BA_ "SigType" SG_ 2364548606 OutNH3GasSnsrAtTemp 5;
BA_ "SPN" SG_ 2364548606 OutNH3GasSnsrPwrInRange 4380;
BA_ "SigType" SG_ 2364548606 OutNH3GasSnsrPwrInRange 5;
BA_ "SPN" SG_ 2364548606 OutNH3ReadingStable 4379;
BA_ "SigType" SG_ 2364548606 OutNH3ReadingStable 5;
BA_ "SPN" SG_ 2364548606 OutNH3SnsrPreliminaryFMI 4378;
BA_ "SPN" SG_ 2364548606 OutNH3 4377;
BA_ "SigType" SG_ 2364548606 OutNH3 1;
BA_ "SPN" SG_ 2566726398 DiffPressPreliminaryFMI 4758;
BA_ "SPN" SG_ 2566726398 OutTempPreliminaryFMI 4757;
BA_ "SPN" SG_ 2566726398 InTempPreliminaryFMI 4756;
BA_ "SPN" SG_ 2566726398 DiffPress 4755;
BA_ "SigType" SG_ 2566726398 DiffPress 1;
BA_ "SPN" SG_ 2566726398 OutTemp 4754;
BA_ "SigType" SG_ 2566726398 OutTemp 1;
BA_ "SPN" SG_ 2566726398 InTemp 4753;
BA_ "SigType" SG_ 2566726398 InTemp 1;
BA_ "SPN" SG_ 2566742270 SPN1 1214;
BA_ "SPN" SG_ 2566742270 FailureModeIdentifier1 1215;
BA_ "SPN" SG_ 2566742270 FailureSpecificB1Counter 4147;
BA_ "SigType" SG_ 2566742270 FailureSpecificB1Counter 1;
BA_ "SPN" SG_ 2566742526 SysGreatestB1Counter 4146;
BA_ "SigType" SG_ 2566742526 SysGreatestB1Counter 1;
BA_ "SPN" SG_ 2566742526 SysCumulativeContinuousMITime 4145;
BA_ "SigType" SG_ 2566742526 SysCumulativeContinuousMITime 1;
BA_ "SPN" SG_ 2566742782 RegulationDescription 4144;
BA_ "SigType" SG_ 2566742782 RegulationDescription 8;
BA_ "SPN" SG_ 2566743038 SysIncompleteMonitorCount 4143;
BA_ "SigType" SG_ 2566743038 SysIncompleteMonitorCount 1;
BA_ "SPN" SG_ 2566743038 SysMalIndActivationMode 4142;
BA_ "SPN" SG_ 2566743038 SysMalIndDisplayStrategy 4141;
BA_ "SigType" SG_ 2566743038 SysMalIndDisplayStrategy 4;
BA_ "SPN" SG_ 2566743038 SysContinuousMalfunctionInd 4140;
BA_ "SigType" SG_ 2566743038 SysContinuousMalfunctionInd 4;
BA_ "SPN" SG_ 2566743038 SysNonRoadworthyCompCount 4139;
BA_ "SigType" SG_ 2566743038 SysNonRoadworthyCompCount 1;
BA_ "SPN" SG_ 2566743294 VehicleCurrentMIAccumTime 4138;
BA_ "SigType" SG_ 2566743294 VehicleCurrentMIAccumTime 1;
BA_ "SPN" SG_ 2566743294 VehicleIncompleteMonitorCount 4137;
BA_ "SigType" SG_ 2566743294 VehicleIncompleteMonitorCount 1;
BA_ "SPN" SG_ 2566743294 VehicleMalfunctionIndActMode 4136;
BA_ "SigType" SG_ 2566743294 VehicleMalfunctionIndActMode 4;
BA_ "SPN" SG_ 2566743294 VehicleMalfunctionIndStrategy 4135;
BA_ "SigType" SG_ 2566743294 VehicleMalfunctionIndStrategy 4;
BA_ "SPN" SG_ 2566743294 VehicleContinuousMalfunctionInd 4134;
BA_ "SigType" SG_ 2566743294 VehicleContinuousMalfunctionInd 4;
BA_ "SPN" SG_ 2566743294 VehicleNonRoadworthyCompCount 4133;
BA_ "SigType" SG_ 2566743294 VehicleNonRoadworthyCompCount 1;
BA_ "SPN" SG_ 2560687870 PMNTEDeficiencyAreaStatus 4132;
BA_ "SigType" SG_ 2560687870 PMNTEDeficiencyAreaStatus 4;
BA_ "SPN" SG_ 2560687870 MnfcPMNTECarveOutAreaStatus 4131;
BA_ "SigType" SG_ 2560687870 MnfcPMNTECarveOutAreaStatus 4;
BA_ "SPN" SG_ 2560687870 PMNTEControlAreaStatus 4130;
BA_ "SPN" SG_ 2560687870 NOxNTEDeficiencyAreaStatus 4129;
BA_ "SigType" SG_ 2560687870 NOxNTEDeficiencyAreaStatus 4;
BA_ "SPN" SG_ 2560687870 MnfcNOxNTECarveOutAreaStatus 4128;
BA_ "SigType" SG_ 2560687870 MnfcNOxNTECarveOutAreaStatus 4;
BA_ "SPN" SG_ 2560687870 NOxNTEControlAreaStatus 4127;
BA_ "SPN" SG_ 2292317950 AECDEngineHours1Timer2 4126;
BA_ "SigType" SG_ 2292317950 AECDEngineHours1Timer2 1;
BA_ "SPN" SG_ 2292317950 AECDEngineHours1Timer1 4125;
BA_ "SigType" SG_ 2292317950 AECDEngineHours1Timer1 1;
BA_ "SPN" SG_ 2292317950 AECDNumber1 4124;
BA_ "SigType" SG_ 2292317950 AECDNumber1 1;
BA_ "SPN" SG_ 2566809342 BatteryMainSwitchHoldState 1681;
BA_ "SigType" SG_ 2566809342 BatteryMainSwitchHoldState 4;
BA_ "SPN" SG_ 2365446910 Joystick3XAxisDetentPosStatus 2754;
BA_ "SigType" SG_ 2365446910 Joystick3XAxisDetentPosStatus 4;
BA_ "SPN" SG_ 2365446910 Joystick3Button9PressedStatus 2767;
BA_ "SigType" SG_ 2365446910 Joystick3Button9PressedStatus 4;
BA_ "SPN" SG_ 2365446910 Joystick3Button10PressedStatus 2768;
BA_ "SigType" SG_ 2365446910 Joystick3Button10PressedStatus 4;
BA_ "SPN" SG_ 2365446910 Joystick3Button11PressedStatus 2769;
BA_ "SigType" SG_ 2365446910 Joystick3Button11PressedStatus 4;
BA_ "SPN" SG_ 2365446910 Joystick3Button12PressedStatus 2770;
BA_ "SigType" SG_ 2365446910 Joystick3Button12PressedStatus 4;
BA_ "SPN" SG_ 2365446910 Joystick3YAxisDetentPosStatus 2755;
BA_ "SigType" SG_ 2365446910 Joystick3YAxisDetentPosStatus 4;
BA_ "SPN" SG_ 2365446910 Joystick3YAxisPos 2735;
BA_ "SPN" SG_ 2365446910 Jystck3YAxsLvrFrwrdPstvPosStatus 2740;
BA_ "SigType" SG_ 2365446910 Jystck3YAxsLvrFrwrdPstvPosStatus 4;
BA_ "SPN" SG_ 2365446910 Jystck3YAxsLvrBckNgtivePosStatus 2745;
BA_ "SigType" SG_ 2365446910 Jystck3YAxsLvrBckNgtivePosStatus 4;
BA_ "SPN" SG_ 2365446910 Joystick3YAxisNeutralPosStatus 2750;
BA_ "SigType" SG_ 2365446910 Joystick3YAxisNeutralPosStatus 4;
BA_ "SPN" SG_ 2365446910 Joystick3XAxisPos 2734;
BA_ "SPN" SG_ 2365446910 Jystck3XAxsLvrRghtPstvePosStatus 2739;
BA_ "SigType" SG_ 2365446910 Jystck3XAxsLvrRghtPstvePosStatus 4;
BA_ "SPN" SG_ 2365446910 Jystck3XAxsLvrLftNgtivePosStatus 2744;
BA_ "SigType" SG_ 2365446910 Jystck3XAxsLvrLftNgtivePosStatus 4;
BA_ "SPN" SG_ 2365446910 Joystick3XAxisNeutralPosStatus 2749;
BA_ "SigType" SG_ 2365446910 Joystick3XAxisNeutralPosStatus 4;
BA_ "SPN" SG_ 2365446910 Joystick3Button5PressedStatus 2763;
BA_ "SigType" SG_ 2365446910 Joystick3Button5PressedStatus 4;
BA_ "SPN" SG_ 2365446910 Joystick3Button6PressedStatus 2764;
BA_ "SigType" SG_ 2365446910 Joystick3Button6PressedStatus 4;
BA_ "SPN" SG_ 2365446910 Joystick3Button7PressedStatus 2765;
BA_ "SigType" SG_ 2365446910 Joystick3Button7PressedStatus 4;
BA_ "SPN" SG_ 2365446910 Joystick3Button8PressedStatus 2766;
BA_ "SigType" SG_ 2365446910 Joystick3Button8PressedStatus 4;
BA_ "SPN" SG_ 2365446910 Joystick3Button1PressedStatus 2759;
BA_ "SigType" SG_ 2365446910 Joystick3Button1PressedStatus 4;
BA_ "SPN" SG_ 2365446910 Joystick3Button2PressedStatus 2760;
BA_ "SigType" SG_ 2365446910 Joystick3Button2PressedStatus 4;
BA_ "SPN" SG_ 2365446910 Joystick3Button3PressedStatus 2761;
BA_ "SigType" SG_ 2365446910 Joystick3Button3PressedStatus 4;
BA_ "SPN" SG_ 2365446910 Joystick3Button4PressedStatus 2762;
BA_ "SigType" SG_ 2365446910 Joystick3Button4PressedStatus 4;
VAL_ 2365403390 Joystick4Button9PressedStatus 3 "Not Available" 2 "Error Indicator" 1 "Button pressed" 0 "Button not pressed" ;
VAL_ 2365403390 Joystick4Button10PressedStatus 1 "Button pressed" 0 "Button not pressed" 3 "Not Available" 2 "Error Indicator" ;
VAL_ 2365403390 Joystick4Button11PressedStatus 3 "Not Available" 2 "Error Indicator" 1 "Button pressed" 0 "Button not pressed" ;
VAL_ 2365403390 Joystick4Button12PressedStatus 3 "Not Available" 2 "Error Indicator" 1 "Button pressed" 0 "Button not pressed" ;
VAL_ 2365403390 Joystick4Button5PressedStatus 3 "Not Available" 2 "Error Indicator" 1 "Button pressed" 0 "Button not pressed" ;
VAL_ 2365403390 Joystick4Button6PressedStatus 3 "Not Available" 2 "Error Indicator" 1 "Button pressed" 0 "Button not pressed" ;
VAL_ 2365403390 Joystick4Button7PressedStatus 3 "Not Available" 2 "Error Indicator" 1 "Button pressed" 0 "Button not pressed" ;
VAL_ 2365403390 Joystick4Button8PressedStatus 3 "Not Available" 2 "Error Indicator" 1 "Button pressed" 0 "Button not pressed" ;
VAL_ 2365403390 Joystick4Button1PressedStatus 3 "Not Available" 2 "Error Indicator" 1 "Button pressed" 0 "Button not pressed" ;
VAL_ 2365403390 Joystick4Button2PressedStatus 3 "Not Available" 2 "Error Indicator" 1 "Button pressed" 0 "Button not pressed" ;
VAL_ 2365403390 Joystick4Button3PressedStatus 3 "Not Available" 2 "Error Indicator" 1 "Button pressed" 0 "Button not pressed" ;
VAL_ 2365403390 Joystick4Button4PressedStatus 3 "Not Available" 2 "Error Indicator" 1 "Button pressed" 0 "Button not pressed" ;
VAL_ 2365403390 Joystick4XAxisDetentPosStatus 3 "Not Available" 2 "Error Indicator" 1 "In the Detent Position" 0 "Not in the Detent Position" ;
VAL_ 2365403390 Joystick4YAxisDetentPosStatus 3 "Not Available" 2 "Error Indicator" 1 "In the Detent Position" 0 "Not in the Detent Position" ;
VAL_ 2365403390 Jystck4YAxsLvrFrwrdPstvPosStatus 3 "Not Available" 2 "Error Indicator" 1 "On positive side of Neutral" 0 "Not on Positive side of Neutral" ;
VAL_ 2365403390 Jystck4YAxsLvrBckNgtivePosStatus 3 "Not Available" 2 "Error Indicator" 1 "On negative side of Neutral" 0 "Not on negative side of Neutral" ;
VAL_ 2365403390 Joystick4YAxisNeutralPosStatus 3 "Not Available" 2 "Error Indicator" 1 "In Neutral Position" 0 "Not in Neutral Position" ;
VAL_ 2365403390 Jystck4XAxsLvrRghtPstvePosStatus 3 "Not Available" 2 "Error Indicator" 1 "On positive side of Neutral" 0 "Not on Positive side of Neutral" ;
VAL_ 2365403390 Jystck4XAxsLvrLftNgtivePosStatus 3 "Not Available" 2 "Error Indicator" 1 "On negative side of Neutral" 0 "Not on negative side of Neutral" ;
VAL_ 2365403390 Joystick4XAxisNeutralPosStatus 3 "Not Available" 2 "Error Indicator" 1 "In Neutral Position" 0 "Not in Neutral Position" ;
VAL_ 2365400318 Joystick10Button9PressedStatus 3 "Not Available" 2 "Error Indicator" 1 "Button pressed" 0 "Button not pressed" ;
VAL_ 2365400318 Joystick10Button10PressedStatus 3 "Not Available" 2 "Error Indicator" 1 "Button pressed" 0 "Button not pressed" ;
VAL_ 2365400318 Joystick10Button11PressedStatus 3 "Not Available" 2 "Error Indicator" 1 "Button pressed" 0 "Button not pressed" ;
VAL_ 2365400318 Joystick10Button12PressedStatus 3 "Not Available" 2 "Error Indicator" 1 "Button pressed" 0 "Button not pressed" ;
VAL_ 2365400318 Joystick10Button5PressedStatus 3 "Not Available" 2 "Error Indicator" 1 "Button pressed" 0 "Button not pressed" ;
VAL_ 2365400318 Joystick10Button6PressedStatus 3 "Not Available" 2 "Error Indicator" 1 "Button pressed" 0 "Button not pressed" ;
VAL_ 2365400318 Joystick10Button7PressedStatus 3 "Not Available" 2 "Error Indicator" 1 "Button pressed" 0 "Button not pressed" ;
VAL_ 2365400318 Joystick10Button8PressedStatus 3 "Not Available" 2 "Error Indicator" 1 "Button pressed" 0 "Button not pressed" ;
VAL_ 2365400318 Joystick10Button1PressedStatus 3 "Not Available" 2 "Error Indicator" 1 "Button pressed" 0 "Button not pressed" ;
VAL_ 2365400318 Joystick10Button2PressedStatus 3 "Not Available" 2 "Error Indicator" 1 "Button pressed" 0 "Button not pressed" ;
VAL_ 2365400318 Joystick10Button3PressedStatus 3 "Not Available" 2 "Error Indicator" 1 "Button pressed" 0 "Button not pressed" ;
VAL_ 2365400318 Joystick10Button4PressedStatus 3 "Not Available" 2 "Error Indicator" 1 "Button pressed" 0 "Button not pressed" ;
VAL_ 2365400318 Joystick10XAxisDetentPosStatus 3 "Not Available" 2 "Error Indicator" 1 "In the Detent Position" 0 "Not in the Detent Position" ;
VAL_ 2365400318 Joystick10YAxisDetentPosStatus 3 "Not Available" 2 "Error Indicator" 1 "In the Detent Position" 0 "Not in the Detent Position" ;
VAL_ 2365400318 Jystck10YAxsLvrFrwrdPstvPsStatus 3 "Not Available" 2 "Error Indicator" 1 "On positive side of Neutral" 0 "Not on Positive side of Neutral" ;
VAL_ 2365400318 Jystck10YAxsLvrBckNgtvePosStatus 3 "Not Available" 2 "Error Indicator" 1 "On negative side of Neutral" 0 "Not on negative side of Neutral" ;
VAL_ 2365400318 Joystick10YAxisNeutralPosStatus 3 "Not Available" 2 "Error Indicator" 1 "In Neutral Position" 0 "Not in Neutral Position" ;
VAL_ 2365400318 Jystck10XAxsLvrRghtPstvPosStatus 3 "Not Available" 2 "Error Indicator" 1 "On positive side of Neutral" 0 "Not on Positive side of Neutral" ;
VAL_ 2365400318 Jystck10XAxsLvrLftNgtvePosStatus 3 "Not Available" 2 "Error Indicator" 1 "On negative side of Neutral" 0 "Not on negative side of Neutral" ;
VAL_ 2365400318 Joystick10XAxisNeutralPosStatus 3 "Not Available" 2 "Error Indicator" 1 "In Neutral Position" 0 "Not in Neutral Position" ;
VAL_ 2499614718 PssngrArbgDctivationSwitchStatus 3 "not available" 2 "Error" 1 "passenger airbag deactivated" 0 "passenger airbag activated" ;
VAL_ 2499614718 Beltlock10Status 3 "not available" 2 "Error" 1 "locked" 0 "unlocked" ;
VAL_ 2499614718 Beltlock9Status 3 "not available" 2 "Error" 1 "locked" 0 "unlocked" ;
VAL_ 2499614718 Beltlock8Status 3 "not available" 2 "Error" 1 "locked" 0 "unlocked" ;
VAL_ 2499614718 Beltlock7Status 3 "not available" 2 "Error" 1 "locked" 0 "unlocked" ;
VAL_ 2499614718 Beltlock6Status 3 "not available" 2 "Error" 1 "locked" 0 "unlocked" ;
VAL_ 2499614718 Beltlock5Status 3 "not available" 2 "Error" 1 "locked" 0 "unlocked" ;
VAL_ 2499614718 Beltlock4Status 3 "not available" 2 "Error" 1 "locked" 0 "unlocked" ;
VAL_ 2499614718 Beltlock3Status 0 "unlocked" 3 "not available" 2 "Error" 1 "locked" ;
VAL_ 2499614718 PassengerBeltlockStatus 3 "not available" 2 "Error" 1 "locked" 0 "unlocked" ;
VAL_ 2499614718 DriverBeltlockStatus 3 "not available" 2 "Error" 1 "locked" 0 "unlocked" ;
VAL_ 2566722814 BatteryCharger2PowerLineState 3 "Not available" 2 "Error" 1 "Connected" 0 "Disconnected" ;
VAL_ 2566722814 BatteryCharger2State 13 "Battery failure" 2 "Stand-by or maintaining the battery charge." 1 "Charging the battery." 0 "Idling" 15 "Not available." 14 "Charger failure" ;
VAL_ 2566723070 BatteryCharger1PowerLineState 3 "Not available" 2 "Error" 1 "Connected" 0 "Disconnected" ;
VAL_ 2566723070 BatteryCharger1State 15 "Not available." 14 "Charger failure" 13 "Battery failure" 2 "Stand-by or maintaining the battery charge." 1 "Charging the battery." 0 "Idling" ;
VAL_ 2566735102 FlowDiverterVlvCtrl 3 "not available" 2 "reserved for SAE assignment" 1 "on" 0 "off" ;
VAL_ 2566735102 PumpRelayCtrl 3 "not available" 2 "reserved for SAE assignment" 1 "on" 0 "off" ;
VAL_ 2566805246 SCROpIndSev 7 "Not Available / Not Supported" 6 "Temporary Override of Inducement " 5 "Inducement Level 5  .." 4 "Inducement Level 4  .." 3 "Inducement Level 3 … EPA defined SCR Inducement" 2 "Inducement Level 2 … DEF Warning" 1 "Inducement Level 1 … EPA defined SCR Inducement" 0 "Driver Warning" ;
VAL_ 2566805246 DEFTankLowLvlInd 7 "not available" 6 "reserved for SAE assignment" 5 "reserved for SAE assignment" 4 "On fast blink" 3 "reserved for SAE assignment" 2 "reserved for SAE assignment" 1 "On solid" 0 "Off" ;
VAL_ 2566711806 Armrest2Switch2 3 "Don't care/take no action" 2 "Reserved" 1 "On" 0 "Off" ;
VAL_ 2566711806 Armrest2Switch1 3 "Don't care/take no action" 2 "Reserved" 1 "On" 0 "Off" ;
VAL_ 2566711806 Armrest1Switch2 3 "Don't care/take no action" 2 "Reserved" 1 "On" 0 "Off" ;
VAL_ 2566711806 Armrest1Switch1 3 "Don't care/take no action" 2 "Reserved" 1 "On" 0 "Off" ;
VAL_ 2364549886 YawRateExRangeFigureOfMerit 3 "Not available" 2 "Error" 1 "Yaw rate degraded" 0 "Yaw rate fully functional" ;
VAL_ 2364549886 RollRateExRangeFigureOfMerit 3 "Not available" 2 "Error" 1 "Roll rate degraded" 0 "Roll rate fully functional" ;
VAL_ 2364549886 PitchRateExRangeFigureOfMerit 3 "Not available" 2 "Error" 1 "Pitch rate degraded" 0 "Pitch rate fully functional" ;
VAL_ 2566712318 DesulfationStatus 3 "Not available" 2 "Error indicator" 1 "Active" 0 "Inactive" ;
VAL_ 2566712318 RegenStatus 3 "Not available" 2 "Error indicator" 1 "Active" 0 "Inactive" ;
VAL_ 2566712574 DesulfationStatus 3 "Not available" 2 "Error indicator" 1 "Active" 0 "Inactive" ;
VAL_ 2566712574 RegenStatus 3 "Not available" 2 "Error indicator" 1 "Active" 0 "Inactive" ;
VAL_ 2566730750 PumpSt 3 "not available" 2 "reserved for SAE assignment" 1 "pump error" 0 "pump operational" ;
VAL_ 2566731518 TypeProperty 15 "Not available" 14 "Error with diesel exhaust fluid property detection" 13 "Not able to determine fluid property" 12 "Diesel exhaust fluid" 3 "Diesel exhaust fluid is proper mixture" 2 "Fluid is diesel" 1 "Urea concentration too low" 0 "Urea concentration too high" ;
VAL_ 2164079358 DEFLineHtr10 3 "not available" 2 "reserved for future assignment by SAE" 1 "request for heater to be active" 0 "request for heater to be inactive" ;
VAL_ 2164079358 DEFLineHtr9 3 "not available" 2 "reserved for future assignment by SAE" 1 "request for heater to be active" 0 "request for heater to be inactive" ;
VAL_ 2164079358 DEFLineHtr8 3 "not available" 2 "reserved for future assignment by SAE" 1 "request for heater to be active" 0 "request for heater to be inactive" ;
VAL_ 2164079358 DEFLineHtr7 3 "not available" 2 "reserved for future assignment by SAE" 1 "request for heater to be active" 0 "request for heater to be inactive" ;
VAL_ 2164079358 DEFLineHtr6 3 "not available" 2 "reserved for future assignment by SAE" 1 "request for heater to be active" 0 "request for heater to be inactive" ;
VAL_ 2164079358 DEFLineHtr5 3 "not available" 2 "reserved for future assignment by SAE " 1 "request for heater to be active " 0 "request for heater to be inactive " ;
VAL_ 2164079358 DEFLineHtrRelay3 3 "Not available" 2 "Error" 1 "On" 0 "Off" ;
VAL_ 2164079358 DEFLineHtrRelay2 3 "Not available" 2 "Error" 1 "On" 0 "Off" ;
VAL_ 2164079358 DEFLineHtrRelay1 3 "Not available" 2 "Error" 1 "On" 0 "Off" ;
VAL_ 2164079358 DEFLineHtr4 3 "not available" 2 "reserved for future assignment by SAE " 1 "request for heater to be active " 0 "request for heater to be inactive " ;
VAL_ 2164079358 DEFLineHtr3 3 "not available" 2 "reserved for future assignment by SAE " 1 "request for heater to be active " 0 "request for heater to be inactive " ;
VAL_ 2164079358 DEFLineHtr2 3 "not available" 2 "reserved for future assignment by SAE " 1 "request for heater to be active " 0 "request for heater to be inactive " ;
VAL_ 2164079358 DEFLineHtr1 3 "not available" 2 "reserved for future assignment by SAE " 1 "request for heater to be active " 0 "request for heater to be inactive " ;
VAL_ 2164079358 DEFDoserHeatingModeReq 7 "Not available" 3 "Heater on" 2 "Heater automatic mode" 1 "Heater economy mode" 0 "Heater off" ;
VAL_ 2164079358 DEFDoserFaultSuppressionReq 3 "Not available" 2 "Reserved" 1 "Error suppression on" 0 "Error suppression off" ;
VAL_ 2364549118 DEFDosingTestInjPermStatus 3 "not available" 2 "error" 1 "DEF dosing test injection allowed" 0 "not allowed" ;
VAL_ 2364549118 DEFHydStiffnessCheckPermStatus 3 "not available" 2 "error" 1 "DEF hydraulic stiffness check allowed" 0 "not allowed" ;
VAL_ 2364549118 SysReqSt 15 "Not available" 14 "Error" 10 "Service test mode,  dosing not allowed" 9 "Service test mode,  dosing allowed " 8 "Diagnosis" 7 "Shutoff" 6 "Protect mode against cold" 5 "Protect mode against heat" 4 "Reserved for future assignment by SAE " 3 "System error pending " 2 "Normal dosing operation " 1 "Preparing dosing readiness" 0 "Dormant" ;
VAL_ 2566732798 DEFLineHtr4St 3 "not available" 2 "error " 1 "heater active " 0 "heater inactive " ;
VAL_ 2566732798 DEFLineHtr3St 3 "not available" 2 "error " 1 "heater active " 0 "heater inactive " ;
VAL_ 2566732798 DEFLineHtr2St 3 "not available" 2 "error " 1 "heater active " 0 "heater inactive " ;
VAL_ 2566732798 DEFLineHtr1St 3 "not available" 2 "error " 1 "heater active " 0 "heater inactive " ;
VAL_ 2566732798 FeedbackCtrlStatus 7 "not available" 6 "error " 5 "reserved for future assignment by SAE " 4 "reserved for future assignment by SAE " 3 "reserved for future assignment by SAE " 2 "reserved for future assignment by SAE " 1 "closed loop control active " 0 "open loop control active " ;
VAL_ 2566732798 VlvExhTempReductionReq 7 "not available" 6 "error" 5 "reserved for future assignment by SAE" 4 "reserved for future assignment by SAE" 3 "reserved for future assignment by SAE" 2 "reduction request stage 2" 1 "reduction request stage 1" 0 "no request " ;
VAL_ 2364548862 Sys2St 15 "Not available" 14 "Error" 11 "Ok to Power Down" 10 "Service test mode,  dosing not allowed" 9 "Service test mode,  dosing allowed" 8 "Diagnosis" 7 "Shutoff" 6 "Protect mode against cold" 5 "Protect mode against heat" 4 "Purging" 3 "System error pending" 2 "Normal dosing operation" 1 "Preparing dosing readiness" 0 "Dormant" ;
VAL_ 2364548862 Sys1St 15 "Not available" 14 "Error" 11 "Ok to Power Down" 10 "Service test mode,  dosing not allowed" 9 "Service test mode,  dosing allowed " 8 "Diagnosis" 7 "Shutoff" 6 "Protect mode against cold" 5 "Protect mode against heat" 4 "Purging" 3 "System error pending" 2 "Normal dosing operation" 1 "Preparing dosing readiness" 0 "Dormant" ;
VAL_ 2364549374 OutNH3GasSnsrHtrCtrl 3 "Heater off or Not available" 2 "Preheat 1 " 1 "Preheat 2 " 0 "Automatic " ;
VAL_ 2364549374 OutNH3GasSnsrAtTemp 3 "Not available" 2 "Error" 1 "Heater element is in range" 0 "Heater element is not in range" ;
VAL_ 2364549374 OutNH3GasSnsrPwrInRange 3 "Not available" 2 "Error" 1 "Heater element is in range" 0 "Heater element is not in range" ;
VAL_ 2364549374 OutNH3ReadingStable 3 "Not available" 2 "Error" 1 "Reading is stable" 0 "Reading is not stable" ;
VAL_ 2566733054 Pump 3 "not available" 2 "error" 1 "on" 0 "off" ;
VAL_ 2566733054 PumpPwrRelay 3 "not available" 2 "error" 1 "active" 0 "not active" ;
VAL_ 2566733054 PumpSt 3 "not available" 2 "reserved for SAE assignment" 1 "pump error" 0 "pump operational" ;
VAL_ 2566734078 DEFLineHtr10 3 "not available" 2 "reserved for future assignment by SAE" 1 "request for heater to be active" 0 "request for heater to be inactive" ;
VAL_ 2566734078 DEFLineHtr9 3 "not available" 2 "reserved for future assignment by SAE" 1 "request for heater to be active" 0 "request for heater to be inactive" ;
VAL_ 2566734078 DEFLineHtr8 3 "not available" 2 "reserved for future assignment by SAE" 1 "request for heater to be active" 0 "request for heater to be inactive" ;
VAL_ 2566734078 DEFLineHtr7 3 "not available" 2 "reserved for future assignment by SAE" 1 "request for heater to be active" 0 "request for heater to be inactive" ;
VAL_ 2566734078 DEFLineHtr6 3 "not available" 2 "reserved for future assignment by SAE" 1 "request for heater to be active" 0 "request for heater to be inactive" ;
VAL_ 2566734078 DEFLineHtr5 3 "not available" 2 "reserved for future assignment by SAE" 1 "request for heater to be active" 0 "request for heater to be inactive" ;
VAL_ 2566734078 DEFLineHtrRelay3 3 "Not available" 2 "Error" 1 "On" 0 "Off" ;
VAL_ 2566734078 DEFLineHtrRelay2 3 "Not available" 2 "Error" 1 "On" 0 "Off" ;
VAL_ 2566734078 DEFLineHtrRelay1 3 "Not available" 2 "Error" 1 "On" 0 "Off" ;
VAL_ 2566734078 DEFLineHtr4 3 "not available" 2 "reserved for future assignment by SAE " 1 "request for heater to be active " 0 "request for heater to be inactive " ;
VAL_ 2566734078 DEFLineHtr3 3 "not available" 2 "reserved for future assignment by SAE " 1 "request for heater to be active " 0 "request for heater to be inactive " ;
VAL_ 2566734078 DEFLineHtr2 3 "not available" 2 "reserved for future assignment by SAE " 1 "request for heater to be active " 0 "request for heater to be inactive " ;
VAL_ 2566734078 DEFLineHtr1 3 "not available" 2 "reserved for future assignment by SAE " 1 "request for heater to be active " 0 "request for heater to be inactive " ;
VAL_ 2566734078 DEFDoserHeatingModeReq 7 "Not available" 3 "Heater on" 2 "Heater automatic mode" 1 "Heater economy mode" 0 "Heater off" ;
VAL_ 2566734078 DEFDoserFaultSuppressionReq 3 "Not available" 2 "Reserved" 1 "Error suppression on" 0 "Error suppression off" ;
VAL_ 2364548350 DEFDosingTestInjPermStatus 3 "not available" 2 "error" 1 "DEF dosing test injection allowed" 0 "not allowed" ;
VAL_ 2364548350 DEFHydStiffnessCheckPermStatus 3 "not available" 2 "error" 1 "DEF hydraulic stiffness check allowed" 0 "not allowed" ;
VAL_ 2364548350 SysReqSt 15 "Not available" 14 "Error" 10 "Service test mode,  dosing not allowed" 9 "Service test mode,  dosing allowed " 8 "Diagnosis" 7 "Shutoff" 6 "Protect mode against cold" 5 "Protect mode against heat" 4 "Reserved for future assignment by SAE " 3 "System error pending " 2 "Normal dosing operation " 1 "Preparing dosing readiness" 0 "Dormant" ;
VAL_ 2566734334 DEFLineHtr4St 3 "not available" 2 "error " 1 "heater active " 0 "heater inactive " ;
VAL_ 2566734334 DEFLineHtr3St 3 "not available" 2 "error " 1 "heater active " 0 "heater inactive " ;
VAL_ 2566734334 DEFLineHtr2St 3 "not available" 2 "error " 1 "heater active " 0 "heater inactive " ;
VAL_ 2566734334 DEFLineHtr1St 3 "not available" 2 "error " 1 "heater active " 0 "heater inactive " ;
VAL_ 2566734334 FeedbackCtrlStatus 7 "not available" 6 "error " 5 "reserved for future assignment by SAE " 4 "reserved for future assignment by SAE " 3 "reserved for future assignment by SAE " 2 "reserved for future assignment by SAE " 1 "closed loop control active " 0 "open loop control active " ;
VAL_ 2566734334 VlvExhTempReductionReq 7 "not available" 6 "error" 5 "reserved for future assignment by SAE" 4 "reserved for future assignment by SAE" 3 "reserved for future assignment by SAE" 2 "reduction request stage 2" 1 "reduction request stage 1" 0 "no request " ;
VAL_ 2364548094 Sys2St 15 "Not available" 14 "Error" 11 "Ok to Power Down" 10 "Service test mode,  dosing not allowed" 9 "Service test mode,  dosing allowed" 8 "Diagnosis" 7 "Shutoff" 6 "Protect mode against cold" 5 "Protect mode against heat" 4 "Purging" 3 "System error pending" 2 "Normal dosing operation" 1 "Preparing dosing readiness" 0 "Dormant" ;
VAL_ 2364548094 Sys1St 15 "Not available" 14 "Error" 11 "Ok to Power Down" 10 "Service test mode,  dosing not allowed" 9 "Service test mode,  dosing allowed " 8 "Diagnosis" 7 "Shutoff " 6 "Protect mode against cold " 5 "Protect mode against heat " 4 "Purging" 3 "System error pending" 2 "Normal dosing operation" 1 "Preparing dosing readiness" 0 "Dormant" ;
VAL_ 2364548606 OutNH3GasSnsrHtrCtrl 3 "Heater off or not available" 2 "Preheat 1 " 1 "Preheat 2 " 0 "Automatic " ;
VAL_ 2364548606 OutNH3GasSnsrAtTemp 3 "Not available" 2 "Error" 1 "Heater element is in range" 0 "Heater element is not in range" ;
VAL_ 2364548606 OutNH3GasSnsrPwrInRange 3 "Not available" 2 "Error" 1 "Power is in range" 0 "Power is not in range" ;
VAL_ 2364548606 OutNH3ReadingStable 3 "Not available" 2 "Error" 1 "Reading is stable" 0 "Reading is not stable" ;
VAL_ 2566742270 FailureModeIdentifier1 31 "Not available" 19 "Received network data in error" 18 "Below normal (moderately severe)" 17 "Below normal (least severe)" 16 "Above normal (moderately severe)" 15 "Above normal (least severe)" 14 "Special intstructions" 13 "Out of calibration" 12 "Bad intelligent device" 11 "Root cause not known" 10 "Abnormal rate of change" 9 "Abnormal update rate" 8 "Abnormal frequency" 7 "Mechanical system not responding" 6 "Current above normal" 5 "Current below normal" 4 "Voltage below normal" 3 "Voltage above normal" 2 "Data erratic" 1 "Below normal (most severe)" 0 "Above normal (most severe)" ;
VAL_ 2560687870 PMNTEDeficiencyAreaStatus 3 "NotAvailable" 2 "Reserved" 1 "InsideControlArea" 0 "OutsideControlArea" ;
VAL_ 2560687870 MnfcPMNTECarveOutAreaStatus 3 "NotAvailable" 2 "Reserved" 1 "InsideControlArea" 0 "OutsideControlArea" ;
VAL_ 2560687870 PMNTEControlAreaStatus 3 "NotAvailable" 2 "Reserved" 1 "InsideControlArea" 0 "OutsideControlArea" ;
VAL_ 2560687870 NOxNTEDeficiencyAreaStatus 3 "NotAvailable" 2 "Reserved" 1 "InsideControlArea" 0 "OutsideControlArea" ;
VAL_ 2560687870 MnfcNOxNTECarveOutAreaStatus 3 "NotAvailable" 2 "Reserved" 1 "InsideControlArea" 0 "OutsideControlArea" ;
VAL_ 2560687870 NOxNTEControlAreaStatus 3 "NotAvailable" 2 "Reserved" 1 "InsideControlArea" 0 "OutsideControlArea" ;
VAL_ 2566809342 BatteryMainSwitchHoldState 3 "Don't care/take no action" 2 "Reserved" 1 "Battery main switch held" 0 "Battery main switch not held" ;
VAL_ 2365446910 Joystick3XAxisDetentPosStatus 3 "Not Available" 2 "Error Indicator" 1 "In the Detent Position" 0 "Not in the Detent Position" ;
VAL_ 2365446910 Joystick3Button9PressedStatus 3 "Not Available" 2 "Error Indicator" 1 "Button pressed" 0 "Button not pressed" ;
VAL_ 2365446910 Joystick3Button10PressedStatus 3 "Not Available" 2 "Error Indicator" 1 "Button pressed" 0 "Button not pressed" ;
VAL_ 2365446910 Joystick3Button11PressedStatus 3 "Not Available" 2 "Error Indicator" 1 "Button pressed" 0 "Button not pressed" ;
VAL_ 2365446910 Joystick3Button12PressedStatus 3 "Not Available" 2 "Error Indicator" 1 "Button pressed" 0 "Button not pressed" ;
VAL_ 2365446910 Joystick3YAxisDetentPosStatus 3 "Not Available" 2 "Error Indicator" 1 "In the Detent Position" 0 "Not in the Detent Position" ;
VAL_ 2365446910 Jystck3YAxsLvrFrwrdPstvPosStatus 3 "Not Available" 2 "Error Indicator" 1 "On positive side of Neutral" 0 "Not on Positive side of Neutral" ;
VAL_ 2365446910 Jystck3YAxsLvrBckNgtivePosStatus 3 "Not Available" 2 "Error Indicator" 1 "On negative side of Neutral" 0 "Not on negative side of Neutral" ;
VAL_ 2365446910 Joystick3YAxisNeutralPosStatus 3 "Not Available" 2 "Error Indicator" 1 "In Neutral Position" 0 "Not in Neutral Position" ;
VAL_ 2365446910 Jystck3XAxsLvrRghtPstvePosStatus 3 "Not Available" 2 "Error Indicator" 1 "On positive side of Neutral" 0 "Not on Positive side of Neutral" ;
VAL_ 2365446910 Jystck3XAxsLvrLftNgtivePosStatus 3 "Not Available" 2 "Error Indicator" 1 "On negative side of Neutral" 0 "Not on negative side of Neutral" ;
VAL_ 2365446910 Joystick3XAxisNeutralPosStatus 3 "Not Available" 2 "Error Indicator" 1 "In Neutral Position" 0 "Not in Neutral Position" ;
VAL_ 2365446910 Joystick3Button5PressedStatus 3 "Not Available" 2 "Error Indicator" 1 "Button pressed" 0 "Button not pressed" ;
VAL_ 2365446910 Joystick3Button6PressedStatus 3 "Not Available" 2 "Error Indicator" 1 "Button pressed" 0 "Button not pressed" ;
VAL_ 2365446910 Joystick3Button7PressedStatus 3 "Not Available" 2 "Error Indicator" 1 "Button pressed" 0 "Button not pressed" ;
VAL_ 2365446910 Joystick3Button8PressedStatus 3 "Not Available" 2 "Error Indicator" 1 "Button pressed" 0 "Button not pressed" ;
VAL_ 2365446910 Joystick3Button1PressedStatus 3 "Not Available" 2 "Error Indicator" 1 "Button pressed" 0 "Button not pressed" ;
VAL_ 2365446910 Joystick3Button2PressedStatus 3 "Not Available" 2 "Error Indicator" 1 "Button pressed" 0 "Button not pressed" ;
VAL_ 2365446910 Joystick3Button3PressedStatus 3 "Not Available" 2 "Error Indicator" 1 "Button pressed" 0 "Button not pressed" ;
VAL_ 2365446910 Joystick3Button4PressedStatus 3 "Not Available" 2 "Error Indicator" 1 "Button pressed" 0 "Button not pressed" ;
